VERSION "June 2, 2025"

NS_ :

BS_:

BU_: VEH CH Receiver Receiver ChassisBus VehicleBus PartyBus

BO_ 1029 VIN_info: 8 VEH
 SG_ VIN_infoIndex M : 0|8@1+ (1,0) [0|255] "" Vector__XXX
 SG_ VIN_B405 m17 : 8|56@1+ (1,0) [0|7.20576e+16] "" Vector__XXX
 SG_ VIN_C405 m18 : 8|56@1+ (1,0) [0|7.20576e+16] "" Vector__XXX
 SG_ VIN_A405 m16 : 8|56@1+ (1,0) [0|7.20576e+16] "" Vector__XXX

BO_ 1040 APP_cameraStatus: 1 CH
 SG_ APP_backupCameraFeedGood : 0|1@1+ (1,0) [0|0] "" Vector__XXX
 SG_ APP_backupCameraFrameRate : 1|6@1+ (1,0) [0|0] "" Vector__XXX

BO_ 1064 UI_telemetryControl: 8 CH
 SG_ UI_TCR_classConstElem : 5|1@1+ (1,0) [0|0] "" Vector__XXX
 SG_ UI_TCR_classMovingFourWheel : 8|1@1+ (1,0) [0|0] "" Vector__XXX
 SG_ UI_TCR_classMovingPed : 6|1@1+ (1,0) [0|0] "" Vector__XXX
 SG_ UI_TCR_classMovingTwoWheel : 7|1@1+ (1,0) [0|0] "" Vector__XXX
 SG_ UI_TCR_classUnknown : 9|1@1+ (1,0) [0|0] "" Vector__XXX
 SG_ UI_TCR_downSampleFactor : 10|4@1+ (1,0) [0|0] "" Vector__XXX
 SG_ UI_TCR_enable : 0|1@1+ (1,0) [0|0] "" Vector__XXX
 SG_ UI_TCR_maxDy : 48|5@1+ (0.5,0) [0|0] "m" Vector__XXX
 SG_ UI_TCR_maxObjects : 56|5@1+ (1,0) [0|0] "" Vector__XXX
 SG_ UI_TCR_maxRoadClass : 61|3@1+ (1,0) [0|0] "" Vector__XXX
 SG_ UI_TCR_minRCS : 40|8@1+ (0.25,-14) [0|0] "dB" Vector__XXX
 SG_ UI_TCR_moveStateIndeterm : 4|1@1+ (1,0) [0|0] "" Vector__XXX
 SG_ UI_TCR_moveStateMoving : 3|1@1+ (1,0) [0|0] "" Vector__XXX
 SG_ UI_TCR_moveStateStanding : 1|1@1+ (1,0) [0|0] "" Vector__XXX
 SG_ UI_TCR_moveStateStopped : 2|1@1+ (1,0) [0|0] "" Vector__XXX
 SG_ UI_TCR_vehSpeed : 32|8@1+ (1,0) [0|0] "" Vector__XXX
 SG_ UI_TCR_wExist : 24|5@1+ (1,0) [0|0] "" Vector__XXX

BO_ 1065 APP_warningMatrix2: 8 CH
 SG_ APP_w129_mainCamExtNotCal : 0|1@1+ (1,0) [0|0] "" Vector__XXX
 SG_ APP_w130_narrowCamExtNotCal : 1|1@1+ (1,0) [0|0] "" Vector__XXX
 SG_ APP_w131_mainCamCalSaved : 2|1@1+ (1,0) [0|0] "" Vector__XXX
 SG_ APP_w132_narrowCamCalSaved : 3|1@1+ (1,0) [0|0] "" Vector__XXX
 SG_ APP_w133_mainCamInitFault : 4|1@1+ (1,0) [0|0] "" Vector__XXX
 SG_ APP_w134_narrowCamInitFault : 5|1@1+ (1,0) [0|0] "" Vector__XXX
 SG_ APP_w135_fisheyeCamInitFault : 6|1@1+ (1,0) [0|0] "" Vector__XXX
 SG_ APP_w136_lPillarCamInitFault : 7|1@1+ (1,0) [0|0] "" Vector__XXX
 SG_ APP_w137_rPillarCamInitFault : 8|1@1+ (1,0) [0|0] "" Vector__XXX
 SG_ APP_w138_lRepeatCamInitFault : 9|1@1+ (1,0) [0|0] "" Vector__XXX
 SG_ APP_w139_rRepeatCamInitFault : 10|1@1+ (1,0) [0|0] "" Vector__XXX
 SG_ APP_w140_backupCamInitFault : 11|1@1+ (1,0) [0|0] "" Vector__XXX
 SG_ APP_w141_ECU_Thermal_Issue : 12|1@1+ (1,0) [0|0] "" Vector__XXX
 SG_ APP_w142_fwdCamPitchProblem : 13|1@1+ (1,0) [0|0] "" Vector__XXX
 SG_ APP_w143_IDF_event : 14|1@1+ (1,0) [0|0] "" Vector__XXX
 SG_ APP_w144_fanctrldError : 15|1@1+ (1,0) [0|0] "" Vector__XXX
 SG_ APP_w145_camSelfCalIssue : 16|1@1+ (1,0) [0|0] "" Vector__XXX
 SG_ APP_w146_telemetryProblem : 17|1@1+ (1,0) [0|0] "" Vector__XXX
 SG_ APP_w147_selfieCamInitFault : 18|1@1+ (1,0) [0|0] "" Vector__XXX
 SG_ APP_w148_overlayActive : 19|1@1+ (1,0) [0|0] "" Vector__XXX
 SG_ APP_w149_diskFull : 20|1@1+ (1,0) [0|0] "" Vector__XXX
 SG_ APP_w150_diMiaPartyBus : 21|1@1+ (1,0) [0|0] "" Vector__XXX
 SG_ APP_w151_epasMiaPartyBus : 22|1@1+ (1,0) [0|0] "" Vector__XXX
 SG_ APP_w152_espMiaPartyBus : 23|1@1+ (1,0) [0|0] "" Vector__XXX
 SG_ APP_w153_rcmMiaPartyBus : 24|1@1+ (1,0) [0|0] "" Vector__XXX
 SG_ APP_w154_vcleftMiaPartyBus : 25|1@1+ (1,0) [0|0] "" Vector__XXX
 SG_ APP_w155_vcrightMiaPartyBus : 26|1@1+ (1,0) [0|0] "" Vector__XXX
 SG_ APP_w156_epblMiaVehBus : 27|1@1+ (1,0) [0|0] "" Vector__XXX
 SG_ APP_w157_sccmMiaVehBus : 28|1@1+ (1,0) [0|0] "" Vector__XXX
 SG_ APP_w158_vcfrontMiaVehBus : 29|1@1+ (1,0) [0|0] "" Vector__XXX
 SG_ APP_w159_vcleftMiaVehBus : 30|1@1+ (1,0) [0|0] "" Vector__XXX
 SG_ APP_w160_vcrightMiaVehBus : 31|1@1+ (1,0) [0|0] "" Vector__XXX
 SG_ APP_w161_backupCameraUnavailable : 32|1@1+ (1,0) [0|0] "" Vector__XXX
 SG_ APP_w162_mainCameraTypeError : 33|1@1+ (1,0) [0|0] "" Vector__XXX
 SG_ APP_w163_narrowCameraTypeError : 34|1@1+ (1,0) [0|0] "" Vector__XXX
 SG_ APP_w164_fisheyeCameraTypeError : 35|1@1+ (1,0) [0|0] "" Vector__XXX
 SG_ APP_w165_lPillarCameraTypeError : 36|1@1+ (1,0) [0|0] "" Vector__XXX
 SG_ APP_w166_rPillarCameraTypeError : 37|1@1+ (1,0) [0|0] "" Vector__XXX
 SG_ APP_w167_lRepeatCameraTypeError : 38|1@1+ (1,0) [0|0] "" Vector__XXX
 SG_ APP_w168_rRepeatCameraTypeError : 39|1@1+ (1,0) [0|0] "" Vector__XXX
 SG_ APP_w169_backupCameraTypeError : 40|1@1+ (1,0) [0|0] "" Vector__XXX
 SG_ APP_w170_selfieCameraTypeError : 41|1@1+ (1,0) [0|0] "" Vector__XXX
 SG_ APP_w171_appHighCoolantFlowReq : 42|1@1+ (1,0) [0|0] "" Vector__XXX
 SG_ APP_w172_fisheyeCamExtNotCal : 43|1@1+ (1,0) [0|0] "" Vector__XXX
 SG_ APP_w173_lPillarCamExtNotCal : 44|1@1+ (1,0) [0|0] "" Vector__XXX
 SG_ APP_w174_rPillarCamExtNotCal : 45|1@1+ (1,0) [0|0] "" Vector__XXX
 SG_ APP_w175_lRepeatCamExtNotCal : 46|1@1+ (1,0) [0|0] "" Vector__XXX
 SG_ APP_w176_rRepeatCamExtNotCal : 47|1@1+ (1,0) [0|0] "" Vector__XXX
 SG_ APP_w177_fisheyeCamCalSaved : 48|1@1+ (1,0) [0|0] "" Vector__XXX
 SG_ APP_w178_lPillarCamCalSaved : 49|1@1+ (1,0) [0|0] "" Vector__XXX
 SG_ APP_w179_rPillarCamCalSaved : 50|1@1+ (1,0) [0|0] "" Vector__XXX
 SG_ APP_w180_lRepeatCamCalSaved : 51|1@1+ (1,0) [0|0] "" Vector__XXX
 SG_ APP_w181_rRepeatCamCalSaved : 52|1@1+ (1,0) [0|0] "" Vector__XXX
 SG_ APP_w182_mainCameraStreamExit : 53|1@1+ (1,0) [0|0] "" Vector__XXX
 SG_ APP_w183_narrowCameraStreamExit : 54|1@1+ (1,0) [0|0] "" Vector__XXX
 SG_ APP_w184_fisheyeCameraStreamExit : 55|1@1+ (1,0) [0|0] "" Vector__XXX
 SG_ APP_w185_lPillarCameraStreamExit : 56|1@1+ (1,0) [0|0] "" Vector__XXX
 SG_ APP_w186_rPillarCameraStreamExit : 57|1@1+ (1,0) [0|0] "" Vector__XXX
 SG_ APP_w187_lRepeatCameraStreamExit : 58|1@1+ (1,0) [0|0] "" Vector__XXX
 SG_ APP_w188_rRepeatCameraStreamExit : 59|1@1+ (1,0) [0|0] "" Vector__XXX
 SG_ APP_w189_backupCameraStreamExit : 60|1@1+ (1,0) [0|0] "" Vector__XXX
 SG_ APP_w190_selfieCameraStreamExit : 61|1@1+ (1,0) [0|0] "" Vector__XXX
 SG_ APP_w191_autopilotAborting : 62|1@1+ (1,0) [0|0] "" Vector__XXX
 SG_ APP_w192_emergencySpeakerFail : 63|1@1+ (1,0) [0|0] "" Vector__XXX

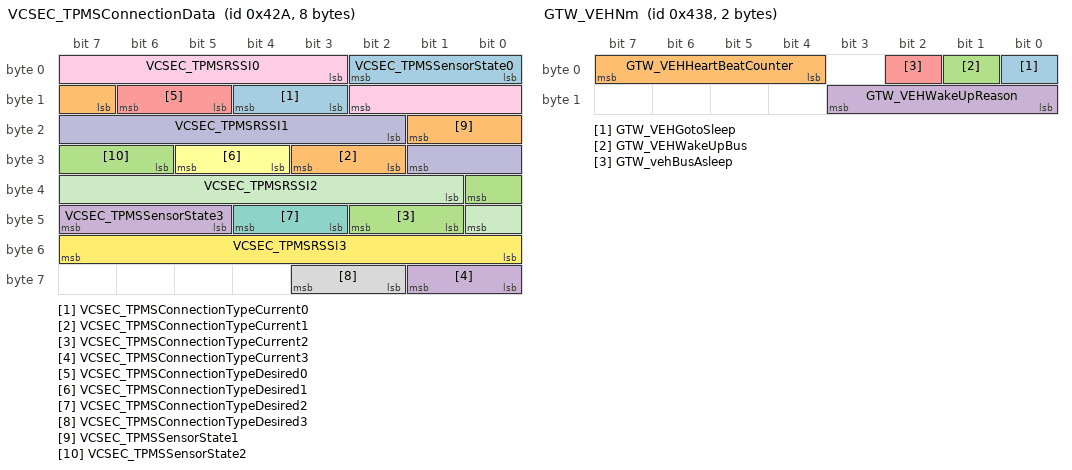
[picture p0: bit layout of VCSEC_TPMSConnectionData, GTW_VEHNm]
BO_ 1066 VCSEC_TPMSConnectionData: 8 VEH
 SG_ VCSEC_TPMSConnectionTypeCurrent0 : 11|2@1+ (1,0) [0|2] "" Vector__XXX
 SG_ VCSEC_TPMSConnectionTypeCurrent1 : 26|2@1+ (1,0) [0|2] "" Vector__XXX
 SG_ VCSEC_TPMSConnectionTypeCurrent2 : 41|2@1+ (1,0) [0|2] "" Vector__XXX
 SG_ VCSEC_TPMSConnectionTypeCurrent3 : 56|2@1+ (1,0) [0|2] "" Vector__XXX
 SG_ VCSEC_TPMSConnectionTypeDesired0 : 13|2@1+ (1,0) [0|2] "" Vector__XXX
 SG_ VCSEC_TPMSConnectionTypeDesired1 : 28|2@1+ (1,0) [0|2] "" Vector__XXX
 SG_ VCSEC_TPMSConnectionTypeDesired2 : 43|2@1+ (1,0) [0|2] "" Vector__XXX
 SG_ VCSEC_TPMSConnectionTypeDesired3 : 58|2@1+ (1,0) [0|2] "" Vector__XXX
 SG_ VCSEC_TPMSRSSI0 : 3|8@1- (1,0) [-127|0] "dBm" Vector__XXX
 SG_ VCSEC_TPMSRSSI1 : 18|8@1- (1,0) [-127|0] "dBm" Vector__XXX
 SG_ VCSEC_TPMSRSSI2 : 33|8@1- (1,0) [-127|0] "dBm" Vector__XXX
 SG_ VCSEC_TPMSRSSI3 : 48|8@1- (1,0) [-127|0] "dBm" Vector__XXX
 SG_ VCSEC_TPMSSensorState0 : 0|3@1+ (1,0) [0|4] "" Vector__XXX
 SG_ VCSEC_TPMSSensorState1 : 15|3@1+ (1,0) [0|4] "" Vector__XXX
 SG_ VCSEC_TPMSSensorState2 : 30|3@1+ (1,0) [0|4] "" Vector__XXX
 SG_ VCSEC_TPMSSensorState3 : 45|3@1+ (1,0) [0|4] "" Vector__XXX

BO_ 1080 GTW_VEHNm: 2 VEH
 SG_ GTW_VEHGotoSleep : 0|1@1+ (1,0) [0|0] "" Vector__XXX
 SG_ GTW_VEHHeartBeatCounter : 4|4@1+ (1,0) [0|0] "" Vector__XXX
 SG_ GTW_VEHWakeUpBus : 1|1@1+ (1,0) [0|0] "" Vector__XXX
 SG_ GTW_VEHWakeUpReason : 8|4@1+ (1,0) [0|0] "" Vector__XXX
 SG_ GTW_vehBusAsleep : 2|1@1+ (1,0) [0|0] "" Vector__XXX

BO_ 1081 APP_warningMatrix3: 8 CH
 SG_ APP_w193_camWindshieldUnclean : 0|1@1+ (1,0) [0|0] "" Vector__XXX
 SG_ APP_w194_accDriverResumeRqrd : 1|1@1+ (1,0) [0|0] "" Vector__XXX
 SG_ APP_w195_scwUnavailable : 2|1@1+ (1,0) [0|0] "" Vector__XXX
 SG_ APP_w196_stopSignWarning : 3|1@1+ (1,0) [0|0] "" Vector__XXX
 SG_ APP_w197_redLightWarning : 4|1@1+ (1,0) [0|0] "" Vector__XXX
 SG_ APP_w198_tsrUnavailable : 5|1@1+ (1,0) [0|0] "" Vector__XXX
 SG_ APP_w199_apcAbort : 6|1@1+ (1,0) [0|0] "" Vector__XXX
 SG_ APP_w200_lcSlowdown : 7|1@1+ (1,0) [0|0] "" Vector__XXX
 SG_ APP_w201_lcAborting : 8|1@1+ (1,0) [0|0] "" Vector__XXX
 SG_ APP_w202_scwNoisyEnvironment : 9|1@1+ (1,0) [0|0] "" Vector__XXX
 SG_ APP_w203_apcActivation : 10|1@1+ (1,0) [0|0] "" Vector__XXX
 SG_ APP_w204_apcFinalFront : 11|1@1+ (1,0) [0|0] "" Vector__XXX
 SG_ APP_w205_apcFinalRear : 12|1@1+ (1,0) [0|0] "" Vector__XXX
 SG_ APP_w206_autosteerNotEnabled : 13|1@1+ (1,0) [0|0] "" Vector__XXX
 SG_ APP_w207_autosteerUnavailable : 14|1@1+ (1,0) [0|0] "" Vector__XXX
 SG_ APP_w208_rackDetected : 15|1@1+ (1,0) [0|0] "" Vector__XXX
 SG_ APP_w209_autoSummonRequest : 16|1@1+ (1,0) [0|0] "" Vector__XXX
 SG_ APP_w210_camObstrcted : 17|1@1+ (1,0) [0|0] "" Vector__XXX
 SG_ APP_w211_accNoSeatBelt : 18|1@1+ (1,0) [0|0] "" Vector__XXX
 SG_ APP_w212_lcUnavailableStrikeOut : 19|1@1+ (1,0) [0|0] "" Vector__XXX
 SG_ APP_w213_autosteerStruckOut : 20|1@1+ (1,0) [0|0] "" Vector__XXX
 SG_ APP_w214_driverNotIntracting : 21|1@1+ (1,0) [0|0] "" Vector__XXX
 SG_ APP_w215_contDriverNotIntracting : 22|1@1+ (1,0) [0|0] "" Vector__XXX
 SG_ APP_w216_driverOverriding : 23|1@1+ (1,0) [0|0] "" Vector__XXX
 SG_ APP_w217_lcUnavailableSpeeding : 24|1@1+ (1,0) [0|0] "" Vector__XXX
 SG_ APP_w218_lcSpeedExceededLimit : 25|1@1+ (1,0) [0|0] "" Vector__XXX
 SG_ APP_w219_lcTempUnavailableSpeed : 26|1@1+ (1,0) [0|0] "" Vector__XXX
 SG_ APP_w220_lcTempUnavailableRoad : 27|1@1+ (1,0) [0|0] "" Vector__XXX
 SG_ APP_w221_accRadarBlind : 28|1@1+ (1,0) [0|0] "" Vector__XXX
 SG_ APP_w222_accCameraBlind : 29|1@1+ (1,0) [0|0] "" Vector__XXX
 SG_ APP_w223_accObjectInPath : 30|1@1+ (1,0) [0|0] "" Vector__XXX
 SG_ APP_w224_accCameraCalibration : 31|1@1+ (1,0) [0|0] "" Vector__XXX
 SG_ APP_w225_lcDegradedVisSpeedLmt : 32|1@1+ (1,0) [0|0] "" Vector__XXX
 SG_ APP_w226_lcCamCalNeededSpeedLmt : 33|1@1+ (1,0) [0|0] "" Vector__XXX
 SG_ APP_w227_virtualWallBlocked : 34|1@1+ (1,0) [0|0] "" Vector__XXX
 SG_ APP_w228_DEPRECATED : 35|1@1+ (1,0) [0|0] "" Vector__XXX
 SG_ APP_w229_alcUltrasoundDamaged : 36|1@1+ (1,0) [0|0] "" Vector__XXX
 SG_ APP_w230_alcUltrasoundBlocked : 37|1@1+ (1,0) [0|0] "" Vector__XXX

BO_ 1082 DAS_warningMatrix3: 8 VEH
 SG_ DAS_w193_camWindshieldUnclean : 0|1@1+ (1,0) [0|0] "" Vector__XXX
 SG_ DAS_w194_accDriverResumeRqrd : 1|1@1+ (1,0) [0|0] "" Vector__XXX
 SG_ DAS_w195_scwUnavailable : 2|1@1+ (1,0) [0|0] "" Vector__XXX
 SG_ DAS_w196_stopSignWarning : 3|1@1+ (1,0) [0|0] "" Vector__XXX
 SG_ DAS_w197_redLightWarning : 4|1@1+ (1,0) [0|0] "" Vector__XXX
 SG_ DAS_w198_tsrUnavailable : 5|1@1+ (1,0) [0|0] "" Vector__XXX
 SG_ DAS_w199_apcAbort : 6|1@1+ (1,0) [0|0] "" Vector__XXX
 SG_ DAS_w200_lcSlowdown : 7|1@1+ (1,0) [0|0] "" Vector__XXX
 SG_ DAS_w201_lcAborting : 8|1@1+ (1,0) [0|0] "" Vector__XXX
 SG_ DAS_w202_scwNoisyEnvironment : 9|1@1+ (1,0) [0|0] "" Vector__XXX
 SG_ DAS_w203_apcActivation : 10|1@1+ (1,0) [0|0] "" Vector__XXX
 SG_ DAS_w204_apcFinalFront : 11|1@1+ (1,0) [0|0] "" Vector__XXX
 SG_ DAS_w205_apcFinalRear : 12|1@1+ (1,0) [0|0] "" Vector__XXX
 SG_ DAS_w206_autosteerNotEnabled : 13|1@1+ (1,0) [0|0] "" Vector__XXX
 SG_ DAS_w207_autosteerUnavailable : 14|1@1+ (1,0) [0|0] "" Vector__XXX
 SG_ DAS_w208_rackDetected : 15|1@1+ (1,0) [0|0] "" Vector__XXX
 SG_ DAS_w209_autoSummonRequest : 16|1@1+ (1,0) [0|0] "" Vector__XXX
 SG_ DAS_w210_camObstrcted : 17|1@1+ (1,0) [0|0] "" Vector__XXX
 SG_ DAS_w211_accNoSeatBelt : 18|1@1+ (1,0) [0|0] "" Vector__XXX
 SG_ DAS_w212_lcUnavailableStrikeOut : 19|1@1+ (1,0) [0|0] "" Vector__XXX
 SG_ DAS_w213_autosteerStruckOut : 20|1@1+ (1,0) [0|0] "" Vector__XXX
 SG_ DAS_w214_driverNotIntracting : 21|1@1+ (1,0) [0|0] "" Vector__XXX
 SG_ DAS_w215_contDriverNotIntracting : 22|1@1+ (1,0) [0|0] "" Vector__XXX
 SG_ DAS_w216_driverOverriding : 23|1@1+ (1,0) [0|0] "" Vector__XXX
 SG_ DAS_w217_lcUnavailableSpeeding : 24|1@1+ (1,0) [0|0] "" Vector__XXX
 SG_ DAS_w218_lcSpeedExceededLimit : 25|1@1+ (1,0) [0|0] "" Vector__XXX
 SG_ DAS_w219_lcTempUnavailableSpeed : 26|1@1+ (1,0) [0|0] "" Vector__XXX
 SG_ DAS_w220_lcTempUnavailableRoad : 27|1@1+ (1,0) [0|0] "" Vector__XXX
 SG_ DAS_w221_accRadarBlind : 28|1@1+ (1,0) [0|0] "" Vector__XXX
 SG_ DAS_w222_accCameraBlind : 29|1@1+ (1,0) [0|0] "" Vector__XXX
 SG_ DAS_w223_accObjectInPath : 30|1@1+ (1,0) [0|0] "" Vector__XXX
 SG_ DAS_w224_accCameraCalibration : 31|1@1+ (1,0) [0|0] "" Vector__XXX
 SG_ DAS_w225_lcDegradedVisSpeedLmt : 32|1@1+ (1,0) [0|0] "" Vector__XXX
 SG_ DAS_w226_lcCamCalNeededSpeedLmt : 33|1@1+ (1,0) [0|0] "" Vector__XXX
 SG_ DAS_w227_virtualWallBlocked : 34|1@1+ (1,0) [0|0] "" Vector__XXX
 SG_ DAS_w228_DEPRECATED : 35|1@1+ (1,0) [0|0] "" Vector__XXX
 SG_ DAS_w229_alcUltrasoundDamaged : 36|1@1+ (1,0) [0|0] "" Vector__XXX
 SG_ DAS_w230_alcUltrasoundBlocked : 37|1@1+ (1,0) [0|0] "" Vector__XXX

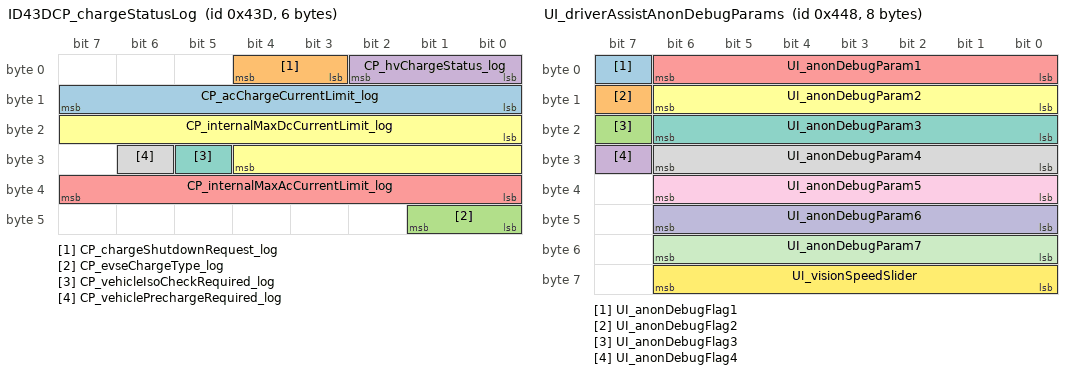
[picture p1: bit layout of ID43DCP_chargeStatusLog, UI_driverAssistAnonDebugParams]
BO_ 1085 ID43DCP_chargeStatusLog: 6 VehicleBus
 SG_ CP_acChargeCurrentLimit_log : 8|8@1+ (0.5,0) [0|127.5] "A"   X
 SG_ CP_chargeShutdownRequest_log : 3|2@1+ (1,0) [0|2] ""   X
 SG_ CP_evseChargeType_log : 40|2@1+ (1,0) [0|2] ""   X
 SG_ CP_hvChargeStatus_log : 0|3@1+ (1,0) [0|6] ""   X
 SG_ CP_internalMaxAcCurrentLimit_log : 32|8@1+ (0.5,0) [0|127.5] "A"   X
 SG_ CP_internalMaxDcCurrentLimit_log : 16|13@1+ (0.146502,0) [0|1200] "A"   X
 SG_ CP_vehicleIsoCheckRequired_log : 29|1@1+ (1,0) [0|1] ""   X
 SG_ CP_vehiclePrechargeRequired_log : 30|1@1+ (1,0) [0|1] ""   X

BO_ 1096 UI_driverAssistAnonDebugParams: 8 VEH
 SG_ UI_anonDebugFlag1 : 7|1@1+ (1,0) [0|0] "" Vector__XXX
 SG_ UI_anonDebugFlag2 : 15|1@1+ (1,0) [0|0] "" Vector__XXX
 SG_ UI_anonDebugFlag3 : 23|1@1+ (1,0) [0|0] "" Vector__XXX
 SG_ UI_anonDebugFlag4 : 31|1@1+ (1,0) [0|0] "" Vector__XXX
 SG_ UI_anonDebugParam1 : 0|7@1+ (1,0) [0|0] "" Vector__XXX
 SG_ UI_anonDebugParam2 : 8|7@1+ (1,0) [0|0] "" Vector__XXX
 SG_ UI_anonDebugParam3 : 16|7@1+ (1,0) [0|0] "" Vector__XXX
 SG_ UI_anonDebugParam4 : 24|7@1+ (1,0) [0|0] "" Vector__XXX
 SG_ UI_anonDebugParam5 : 32|7@1+ (1,0) [0|0] "" Vector__XXX
 SG_ UI_anonDebugParam6 : 40|7@1+ (1,0) [0|0] "" Vector__XXX
 SG_ UI_anonDebugParam7 : 48|7@1+ (1,0) [0|0] "" Vector__XXX
 SG_ UI_visionSpeedSlider : 56|7@1+ (1,0) [0|0] "" Vector__XXX

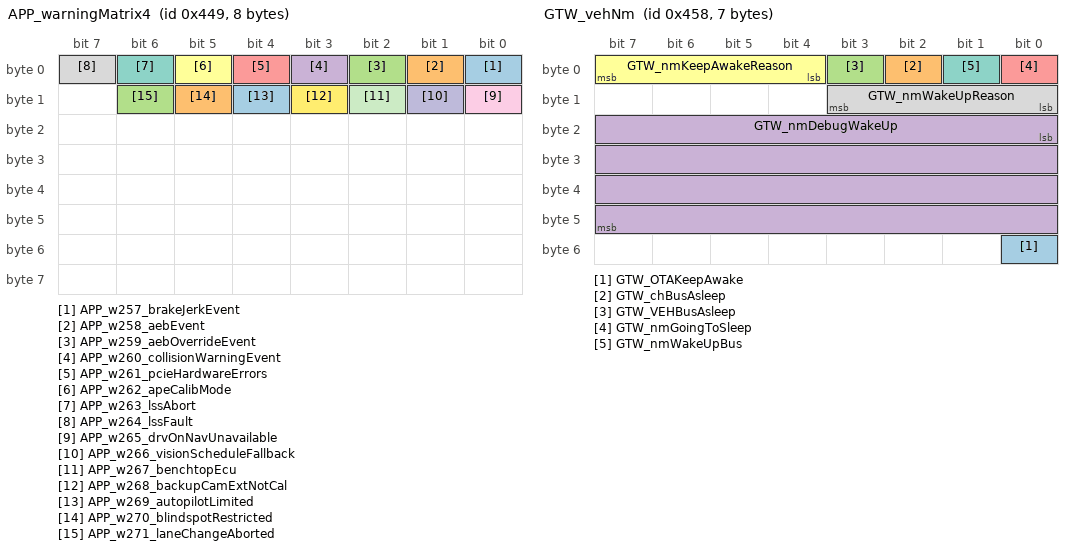
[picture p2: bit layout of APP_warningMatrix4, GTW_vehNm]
BO_ 1097 APP_warningMatrix4: 8 CH
 SG_ APP_w257_brakeJerkEvent : 0|1@1+ (1,0) [0|0] "" Vector__XXX
 SG_ APP_w258_aebEvent : 1|1@1+ (1,0) [0|0] "" Vector__XXX
 SG_ APP_w259_aebOverrideEvent : 2|1@1+ (1,0) [0|0] "" Vector__XXX
 SG_ APP_w260_collisionWarningEvent : 3|1@1+ (1,0) [0|0] "" Vector__XXX
 SG_ APP_w261_pcieHardwareErrors : 4|1@1+ (1,0) [0|0] "" Vector__XXX
 SG_ APP_w262_apeCalibMode : 5|1@1+ (1,0) [0|0] "" Vector__XXX
 SG_ APP_w263_lssAbort : 6|1@1+ (1,0) [0|0] "" Vector__XXX
 SG_ APP_w264_lssFault : 7|1@1+ (1,0) [0|0] "" Vector__XXX
 SG_ APP_w265_drvOnNavUnavailable : 8|1@1+ (1,0) [0|0] "" Vector__XXX
 SG_ APP_w266_visionScheduleFallback : 9|1@1+ (1,0) [0|0] "" Vector__XXX
 SG_ APP_w267_benchtopEcu : 10|1@1+ (1,0) [0|0] "" Vector__XXX
 SG_ APP_w268_backupCamExtNotCal : 11|1@1+ (1,0) [0|0] "" Vector__XXX
 SG_ APP_w269_autopilotLimited : 12|1@1+ (1,0) [0|0] "" Vector__XXX
 SG_ APP_w270_blindspotRestricted : 13|1@1+ (1,0) [0|0] "" Vector__XXX
 SG_ APP_w271_laneChangeAborted : 14|1@1+ (1,0) [0|0] "" Vector__XXX

BO_ 1112 GTW_vehNm: 7 VEH
 SG_ GTW_OTAKeepAwake : 48|1@1+ (1,0) [0|0] "" Vector__XXX
 SG_ GTW_chBusAsleep : 2|1@1+ (1,0) [0|0] "" Vector__XXX
 SG_ GTW_VEHBusAsleep : 3|1@1+ (1,0) [0|0] "" Vector__XXX
 SG_ GTW_nmDebugWakeUp : 16|32@1+ (1,0) [0|0] "" Vector__XXX
 SG_ GTW_nmGoingToSleep : 0|1@1+ (1,0) [0|0] "" Vector__XXX
 SG_ GTW_nmKeepAwakeReason : 4|4@1+ (1,0) [0|0] "" Vector__XXX
 SG_ GTW_nmWakeUpBus : 1|1@1+ (1,0) [0|0] "" Vector__XXX
 SG_ GTW_nmWakeUpReason : 8|4@1+ (1,0) [0|0] "" Vector__XXX

BO_ 1113 APS_warningMatrix2: 8 CH
 SG_ APS_w129_ECU_Power_Issue : 0|1@1+ (1,0) [0|0] "" Vector__XXX
 SG_ APS_w130_ECU_Thermal_Issue : 1|1@1+ (1,0) [0|0] "" Vector__XXX
 SG_ APS_w131_trap_exception : 2|1@1+ (1,0) [0|0] "" Vector__XXX
 SG_ APS_w132_appVersionMismatch : 3|1@1+ (1,0) [0|0] "" Vector__XXX
 SG_ APS_w133_VEHSwitchError : 4|1@1+ (1,0) [0|0] "" Vector__XXX
 SG_ APS_w134_appMia : 5|1@1+ (1,0) [0|0] "" Vector__XXX
 SG_ APS_w135_appCritical : 6|1@1+ (1,0) [0|0] "" Vector__XXX
 SG_ APS_w136_gpsDisabled : 7|1@1+ (1,0) [0|0] "" Vector__XXX
 SG_ APS_w137_gpsFaultReset : 8|1@1+ (1,0) [0|0] "" Vector__XXX
 SG_ APS_w138_gpsComIssue : 9|1@1+ (1,0) [0|0] "" Vector__XXX
 SG_ APS_w139_udpBufferOverflow : 10|1@1+ (1,0) [0|0] "" Vector__XXX
 SG_ APS_w140_vcfrontMiaVEH : 11|1@1+ (1,0) [0|0] "" Vector__XXX
 SG_ APS_w141_rcmMiaPartyBus : 12|1@1+ (1,0) [0|0] "" Vector__XXX
 SG_ APS_w142_diMiaPartyBus : 13|1@1+ (1,0) [0|0] "" Vector__XXX
 SG_ APS_w143_espMiaPartyBus : 14|1@1+ (1,0) [0|0] "" Vector__XXX
 SG_ APS_w144_vcleftMiaPartyBus : 15|1@1+ (1,0) [0|0] "" Vector__XXX
 SG_ APS_w145_vcrightMiaPartyBus : 16|1@1+ (1,0) [0|0] "" Vector__XXX
 SG_ APS_w146_epas3pMiaPartyBus : 17|1@1+ (1,0) [0|0] "" Vector__XXX
 SG_ APS_w147_vcleftMiaVehBus : 18|1@1+ (1,0) [0|0] "" Vector__XXX
 SG_ APS_w148_vcrightMiaVehBus : 19|1@1+ (1,0) [0|0] "" Vector__XXX
 SG_ APS_w149_epblMiaVehBus : 20|1@1+ (1,0) [0|0] "" Vector__XXX
 SG_ APS_w150_sccmMiaVehBus : 21|1@1+ (1,0) [0|0] "" Vector__XXX
 SG_ APS_w151_apRecovered : 22|1@1+ (1,0) [0|0] "" Vector__XXX
 SG_ APS_w152_gpsFusionStatus : 23|1@1+ (1,0) [0|0] "" Vector__XXX
 SG_ APS_w153_eacInhibit : 24|1@1+ (1,0) [0|0] "" Vector__XXX
 SG_ APS_w155_VEHLwipError : 26|1@1+ (1,0) [0|0] "" Vector__XXX
 SG_ APS_w156_lwipAssert : 27|1@1+ (1,0) [0|0] "" Vector__XXX
 SG_ APS_w157_autopilotReboot : 28|1@1+ (1,0) [0|0] "" Vector__XXX
 SG_ APS_w158_apbMia : 29|1@1+ (1,0) [0|0] "" Vector__XXX
 SG_ APS_w159_apbCritical : 30|1@1+ (1,0) [0|0] "" Vector__XXX
 SG_ APS_w160_apbVersionMismatch : 31|1@1+ (1,0) [0|0] "" Vector__XXX
 SG_ APS_w161_gpsAntennaDisconnected : 32|1@1+ (1,0) [0|0] "" Vector__XXX

BO_ 1132 CC_alertMatrix1: 8 VEH
 SG_ CC_a001_gndMonIntrptLineSide : 0|1@1+ (1,0) [0|0] "" Vector__XXX
 SG_ CC_a002_gndMonIntrptLoadSide : 1|1@1+ (1,0) [0|0] "" Vector__XXX
 SG_ CC_a003_CCIDTripped : 2|1@1+ (1,0) [0|0] "" Vector__XXX
 SG_ CC_a004_CCIDSelfTestFault : 3|1@1+ (1,0) [0|0] "" Vector__XXX
 SG_ CC_a005_groundedNeutral : 4|1@1+ (1,0) [0|0] "" Vector__XXX
 SG_ CC_a006_inputOverCurrent : 5|1@1+ (1,0) [0|0] "" Vector__XXX
 SG_ CC_a007_inputOverVoltage : 6|1@1+ (1,0) [0|0] "" Vector__XXX
 SG_ CC_a008_inputUnderVoltage : 7|1@1+ (1,0) [0|0] "" Vector__XXX
 SG_ CC_a009_inputMiswired : 8|1@1+ (1,0) [0|0] "" Vector__XXX
 SG_ CC_a010_contactorWelded : 9|1@1+ (1,0) [0|0] "" Vector__XXX
 SG_ CC_a011_ambientOT : 10|1@1+ (1,0) [0|0] "" Vector__XXX
 SG_ CC_a012_wallPlugOT : 11|1@1+ (1,0) [0|0] "" Vector__XXX
 SG_ CC_a013_vehConnOT : 12|1@1+ (1,0) [0|0] "" Vector__XXX
 SG_ CC_a014_mcuSelfTestFault : 13|1@1+ (1,0) [0|0] "" Vector__XXX
 SG_ CC_a015_PilotAFault : 14|1@1+ (1,0) [0|0] "" Vector__XXX
 SG_ CC_a016_PilotBFault : 15|1@1+ (1,0) [0|0] "" Vector__XXX
 SG_ CC_a017_PilotCFault : 16|1@1+ (1,0) [0|0] "" Vector__XXX
 SG_ CC_a018_PilotDFault : 17|1@1+ (1,0) [0|0] "" Vector__XXX
 SG_ CC_a019_proxDisconnected : 18|1@1+ (1,0) [0|0] "" Vector__XXX
 SG_ CC_a020_3vRailIncorrect : 19|1@1+ (1,0) [0|0] "" Vector__XXX
 SG_ CC_a021_CB_noMaster : 20|1@1+ (1,0) [0|0] "" Vector__XXX
 SG_ CC_a022_CB_tooManyMasters : 21|1@1+ (1,0) [0|0] "" Vector__XXX
 SG_ CC_a023_CB_tooManySlaves : 22|1@1+ (1,0) [0|0] "" Vector__XXX
 SG_ CC_a024_CB_masterISetTooLow : 23|1@1+ (1,0) [0|0] "" Vector__XXX
 SG_ CC_a025_evseTemp : 24|1@1+ (1,0) [0|0] "" Vector__XXX
 SG_ CC_a026_wallPlugTemp : 25|1@1+ (1,0) [0|0] "" Vector__XXX
 SG_ CC_a027_vehicleHandleTemp : 26|1@1+ (1,0) [0|0] "" Vector__XXX
 SG_ CC_a028_CB_rotarySelect : 27|1@1+ (1,0) [0|0] "" Vector__XXX
 SG_ CC_a029_PilotFFault : 28|1@1+ (1,0) [0|0] "" Vector__XXX
 SG_ CC_a030_masterSlaveMismatch : 29|1@1+ (1,0) [0|0] "" Vector__XXX

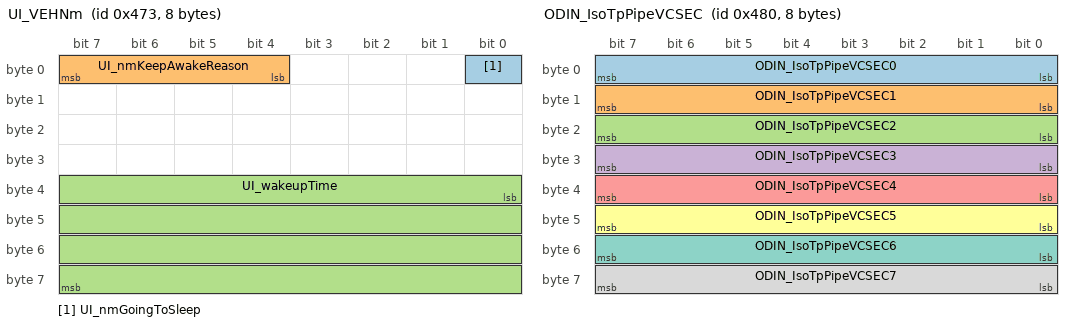
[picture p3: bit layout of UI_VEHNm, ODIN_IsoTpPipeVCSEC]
BO_ 1139 UI_VEHNm: 8 VEH
 SG_ UI_nmGoingToSleep : 0|1@1+ (1,0) [0|0] "" Vector__XXX
 SG_ UI_nmKeepAwakeReason : 4|4@1+ (1,0) [0|0] "" Vector__XXX
 SG_ UI_wakeupTime : 32|32@1+ (1,0) [0|0] "" Vector__XXX

BO_ 1152 ODIN_IsoTpPipeVCSEC: 8 VEH
 SG_ ODIN_IsoTpPipeVCSEC0 : 0|8@1+ (1,0) [0|0] "" Vector__XXX
 SG_ ODIN_IsoTpPipeVCSEC1 : 8|8@1+ (1,0) [0|0] "" Vector__XXX
 SG_ ODIN_IsoTpPipeVCSEC2 : 16|8@1+ (1,0) [0|0] "" Vector__XXX
 SG_ ODIN_IsoTpPipeVCSEC3 : 24|8@1+ (1,0) [0|0] "" Vector__XXX
 SG_ ODIN_IsoTpPipeVCSEC4 : 32|8@1+ (1,0) [0|0] "" Vector__XXX
 SG_ ODIN_IsoTpPipeVCSEC5 : 40|8@1+ (1,0) [0|0] "" Vector__XXX
 SG_ ODIN_IsoTpPipeVCSEC6 : 48|8@1+ (1,0) [0|0] "" Vector__XXX
 SG_ ODIN_IsoTpPipeVCSEC7 : 56|8@1+ (1,0) [0|0] "" Vector__XXX

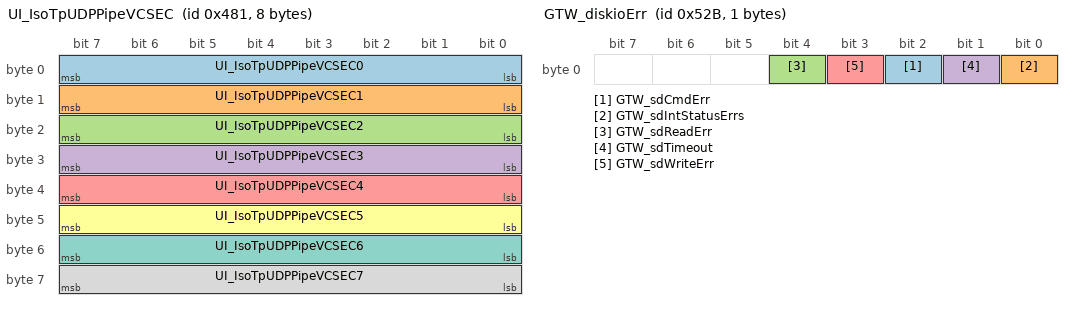
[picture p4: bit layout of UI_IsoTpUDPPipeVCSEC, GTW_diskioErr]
BO_ 1153 UI_IsoTpUDPPipeVCSEC: 8 VEH
 SG_ UI_IsoTpUDPPipeVCSEC0 : 0|8@1+ (1,0) [0|0] "" Vector__XXX
 SG_ UI_IsoTpUDPPipeVCSEC1 : 8|8@1+ (1,0) [0|0] "" Vector__XXX
 SG_ UI_IsoTpUDPPipeVCSEC2 : 16|8@1+ (1,0) [0|0] "" Vector__XXX
 SG_ UI_IsoTpUDPPipeVCSEC3 : 24|8@1+ (1,0) [0|0] "" Vector__XXX
 SG_ UI_IsoTpUDPPipeVCSEC4 : 32|8@1+ (1,0) [0|0] "" Vector__XXX
 SG_ UI_IsoTpUDPPipeVCSEC5 : 40|8@1+ (1,0) [0|0] "" Vector__XXX
 SG_ UI_IsoTpUDPPipeVCSEC6 : 48|8@1+ (1,0) [0|0] "" Vector__XXX
 SG_ UI_IsoTpUDPPipeVCSEC7 : 56|8@1+ (1,0) [0|0] "" Vector__XXX

BO_ 1250 VCLEFT_seatStatus: 8 VEH
 SG_ VCLEFT_seatStatusIndex M : 0|3@1+ (1,0) [0|0] "" Vector__XXX
 SG_ VCLEFT_frontSeatTrackPos m0 : 8|16@1- (1,0) [0|0] "" Vector__XXX
 SG_ VCLEFT_frontSeatTrackCurrent m0 : 24|12@1- (0.01,0) [0|0] "A" Vector__XXX
 SG_ VCLEFT_frontSeatTrackDuty m0 : 36|12@1- (0.1,0) [0|0] "%" Vector__XXX
 SG_ VCLEFT_frontSeatTrackState m0 : 48|3@1+ (1,0) [0|0] "" Vector__XXX
 SG_ VCLEFT_frontSeatTrackCalibrated m0 : 51|1@1+ (1,0) [0|0] "" Vector__XXX
 SG_ VCLEFT_frontSeatTrackLog m0 : 52|1@1+ (1,0) [0|0] "" Vector__XXX
 SG_ VCLEFT_frontSeatBackPos m1 : 8|16@1- (1,0) [0|0] "" Vector__XXX
 SG_ VCLEFT_frontSeatBackCurrent m1 : 24|12@1- (0.01,0) [0|0] "A" Vector__XXX
 SG_ VCLEFT_frontSeatBackDuty m1 : 36|12@1- (0.1,0) [0|0] "%" Vector__XXX
 SG_ VCLEFT_frontSeatBackState m1 : 48|3@1+ (1,0) [0|0] "" Vector__XXX
 SG_ VCLEFT_frontSeatBackCalibrated m1 : 51|1@1+ (1,0) [0|0] "" Vector__XXX
 SG_ VCLEFT_frontSeatBackLog m1 : 52|1@1+ (1,0) [0|0] "" Vector__XXX
 SG_ VCLEFT_frontSeatLiftPos m2 : 8|16@1- (1,0) [0|0] "" Vector__XXX
 SG_ VCLEFT_frontSeatLiftCurrent m2 : 24|12@1- (0.01,0) [0|0] "A" Vector__XXX
 SG_ VCLEFT_frontSeatLiftDuty m2 : 36|12@1- (0.1,0) [0|0] "%" Vector__XXX
 SG_ VCLEFT_frontSeatLiftState m2 : 48|3@1+ (1,0) [0|0] "" Vector__XXX
 SG_ VCLEFT_frontSeatLiftCalibrated m2 : 51|1@1+ (1,0) [0|0] "" Vector__XXX
 SG_ VCLEFT_frontSeatLiftLog m2 : 52|1@1+ (1,0) [0|0] "" Vector__XXX
 SG_ VCLEFT_frontSeatTiltPos m3 : 8|16@1- (1,0) [0|0] "" Vector__XXX
 SG_ VCLEFT_frontSeatTiltCurrent m3 : 24|12@1- (0.01,0) [0|0] "A" Vector__XXX
 SG_ VCLEFT_frontSeatTiltDuty m3 : 36|12@1- (0.1,0) [0|0] "%" Vector__XXX
 SG_ VCLEFT_frontSeatTiltState m3 : 48|3@1+ (1,0) [0|0] "" Vector__XXX
 SG_ VCLEFT_frontSeatTiltCalibrated m3 : 51|1@1+ (1,0) [0|0] "" Vector__XXX
 SG_ VCLEFT_frontSeatTiltLog m3 : 52|1@1+ (1,0) [0|0] "" Vector__XXX
 SG_ VCLEFT_lumbarAState m4 : 3|3@1+ (1,0) [0|0] "" Vector__XXX
 SG_ VCLEFT_lumbarBState m4 : 8|3@1+ (1,0) [0|0] "" Vector__XXX
 SG_ VCLEFT_lumbarAPressureHpa m4 : 16|16@1+ (1,0) [0|0] "" Vector__XXX
 SG_ VCLEFT_lumbarBPressureHpa m4 : 32|16@1+ (1,0) [0|0] "" Vector__XXX
 SG_ VCLEFT_lumbarActiveTooLongErr m4 : 48|1@1+ (1,0) [0|0] "" Vector__XXX
 SG_ VCLEFT_lumbarMaxPErr m4 : 49|1@1+ (1,0) [0|0] "" Vector__XXX
 SG_ VCLEFT_lumbarOvercurrentErr m4 : 50|1@1+ (1,0) [0|0] "" Vector__XXX
 SG_ VCLEFT_lumbarMaxOperatingPErr m4 : 51|1@1+ (1,0) [0|0] "" Vector__XXX
 SG_ VCLEFT_lumbarMinPErr m4 : 52|1@1+ (1,0) [0|0] "" Vector__XXX
 SG_ VCLEFT_lumbarGeneralErr m4 : 53|1@1+ (1,0) [0|0] "" Vector__XXX
 SG_ VCLEFT_lumbarDevMaxPumpPressA m4 : 54|1@1+ (1,0) [0|0] "" Vector__XXX
 SG_ VCLEFT_lumbarDevMaxPumpPressB m4 : 55|1@1+ (1,0) [0|0] "" Vector__XXX
 SG_ VCLEFT_frontSeatTrackPosReal m5 : 3|12@1- (1,0) [0|0] "mm" Vector__XXX
 SG_ VCLEFT_frontSeatBackPosReal m5 : 16|12@1- (0.1,0) [0|0] "deg" Vector__XXX
 SG_ VCLEFT_frontSeatLiftPosReal m5 : 28|12@1- (1,0) [0|0] "mm" Vector__XXX
 SG_ VCLEFT_frontSeatTiltPosReal m5 : 40|12@1- (0.1,0) [0|0] "deg" Vector__XXX

BO_ 1251 VCRIGHT_seatStatus: 8 VEH
 SG_ VCRIGHT_seatStatusIndex M : 0|3@1+ (1,0) [0|0] "" Vector__XXX
 SG_ VCRIGHT_frontSeatTrackPos m0 : 8|16@1- (1,0) [0|0] "" Vector__XXX
 SG_ VCRIGHT_frontSeatTrackCurrent m0 : 24|12@1- (0.01,0) [0|0] "A" Vector__XXX
 SG_ VCRIGHT_frontSeatTrackDuty m0 : 36|12@1- (0.1,0) [0|0] "%" Vector__XXX
 SG_ VCRIGHT_frontSeatTrackState m0 : 48|3@1+ (1,0) [0|0] "" Vector__XXX
 SG_ VCRIGHT_frontSeatTrackCalibrated m0 : 51|1@1+ (1,0) [0|0] "" Vector__XXX
 SG_ VCRIGHT_frontSeatTrackLog m0 : 52|1@1+ (1,0) [0|0] "" Vector__XXX
 SG_ VCRIGHT_frontSeatBackPos m1 : 8|16@1- (1,0) [0|0] "" Vector__XXX
 SG_ VCRIGHT_frontSeatBackCurrent m1 : 24|12@1- (0.01,0) [0|0] "A" Vector__XXX
 SG_ VCRIGHT_frontSeatBackDuty m1 : 36|12@1- (0.1,0) [0|0] "%" Vector__XXX
 SG_ VCRIGHT_frontSeatBackState m1 : 48|3@1+ (1,0) [0|0] "" Vector__XXX
 SG_ VCRIGHT_frontSeatBackCalibrated m1 : 51|1@1+ (1,0) [0|0] "" Vector__XXX
 SG_ VCRIGHT_frontSeatBackLog m1 : 52|1@1+ (1,0) [0|0] "" Vector__XXX
 SG_ VCRIGHT_frontSeatLiftPos m2 : 8|16@1- (1,0) [0|0] "" Vector__XXX
 SG_ VCRIGHT_frontSeatLiftCurrent m2 : 24|12@1- (0.01,0) [0|0] "A" Vector__XXX
 SG_ VCRIGHT_frontSeatLiftDuty m2 : 36|12@1- (0.1,0) [0|0] "%" Vector__XXX
 SG_ VCRIGHT_frontSeatLiftState m2 : 48|3@1+ (1,0) [0|0] "" Vector__XXX
 SG_ VCRIGHT_frontSeatLiftCalibrated m2 : 51|1@1+ (1,0) [0|0] "" Vector__XXX
 SG_ VCRIGHT_frontSeatLiftLog m2 : 52|1@1+ (1,0) [0|0] "" Vector__XXX
 SG_ VCRIGHT_frontSeatTiltPos m3 : 8|16@1- (1,0) [0|0] "" Vector__XXX
 SG_ VCRIGHT_frontSeatTiltCurrent m3 : 24|12@1- (0.01,0) [0|0] "A" Vector__XXX
 SG_ VCRIGHT_frontSeatTiltDuty m3 : 36|12@1- (0.1,0) [0|0] "%" Vector__XXX
 SG_ VCRIGHT_frontSeatTiltState m3 : 48|3@1+ (1,0) [0|0] "" Vector__XXX
 SG_ VCRIGHT_frontSeatTiltCalibrated m3 : 51|1@1+ (1,0) [0|0] "" Vector__XXX
 SG_ VCRIGHT_frontSeatTiltLog m3 : 52|1@1+ (1,0) [0|0] "" Vector__XXX
 SG_ VCRIGHT_lumbarAState m4 : 3|3@1+ (1,0) [0|0] "" Vector__XXX
 SG_ VCRIGHT_lumbarBState m4 : 8|3@1+ (1,0) [0|0] "" Vector__XXX
 SG_ VCRIGHT_lumbarAPressureHpa m4 : 16|16@1+ (1,0) [0|0] "" Vector__XXX
 SG_ VCRIGHT_lumbarBPressureHpa m4 : 32|16@1+ (1,0) [0|0] "" Vector__XXX
 SG_ VCRIGHT_lumbarActiveTooLongErr m4 : 48|1@1+ (1,0) [0|0] "" Vector__XXX
 SG_ VCRIGHT_lumbarMaxPErr m4 : 49|1@1+ (1,0) [0|0] "" Vector__XXX
 SG_ VCRIGHT_lumbarOvercurrentErr m4 : 50|1@1+ (1,0) [0|0] "" Vector__XXX
 SG_ VCRIGHT_lumbarMaxOperatingPErr m4 : 51|1@1+ (1,0) [0|0] "" Vector__XXX
 SG_ VCRIGHT_lumbarMinPErr m4 : 52|1@1+ (1,0) [0|0] "" Vector__XXX
 SG_ VCRIGHT_lumbarGeneralErr m4 : 53|1@1+ (1,0) [0|0] "" Vector__XXX
 SG_ VCRIGHT_lumbarDevMaxPumpPressA m4 : 54|1@1+ (1,0) [0|0] "" Vector__XXX
 SG_ VCRIGHT_lumbarDevMaxPumpPressB m4 : 55|1@1+ (1,0) [0|0] "" Vector__XXX
 SG_ VCRIGHT_frontSeatTrackPosReal m5 : 3|12@1- (1,0) [0|0] "mm" Vector__XXX
 SG_ VCRIGHT_frontSeatBackPosReal m5 : 16|12@1- (0.1,0) [0|0] "deg" Vector__XXX
 SG_ VCRIGHT_frontSeatLiftPosReal m5 : 28|12@1- (1,0) [0|0] "mm" Vector__XXX
 SG_ VCRIGHT_frontSeatTiltPosReal m5 : 40|12@1- (0.1,0) [0|0] "deg" Vector__XXX

BO_ 1280 UI_debugECU: 2 VEH
 SG_ UI_debugEcuTarget M : 0|3@1+ (1,0) [0|0] "" Vector__XXX
 SG_ UI_DI_debugEnable m1 : 8|1@1+ (1,0) [0|0] "" Vector__XXX
 SG_ UI_DIS_debugEnable m2 : 8|1@1+ (1,0) [0|0] "" Vector__XXX
 SG_ UI_PM_debugEnable m3 : 8|1@1+ (1,0) [0|0] "" Vector__XXX
 SG_ UI_PM_debugAt100Hz m3 : 9|1@1+ (1,0) [0|0] "" Vector__XXX
 SG_ UI_PMS_debugEnable m4 : 8|1@1+ (1,0) [0|0] "" Vector__XXX
 SG_ UI_PMS_debugAt100Hz m4 : 9|1@1+ (1,0) [0|0] "" Vector__XXX
 SG_ UI_BMS_debugAllEnable m5 : 8|1@1+ (1,0) [0|0] "" Vector__XXX
 SG_ UI_BMS_debugDisable m5 : 9|1@1+ (1,0) [0|0] "" Vector__XXX
 SG_ UI_VCRIGHT_debugEnable m6 : 8|1@1+ (1,0) [0|0] "" Vector__XXX
 SG_ UI_VCFRONT_debugEnable m7 : 3|1@1+ (1,0) [0|0] "" Vector__XXX

BO_ 1282 RADC_alertMatrix0: 8 CH
 SG_ RADC_a001_can1BusOff : 1|1@1+ (1,0) [0|0] "" Vector__XXX
 SG_ RADC_a002_ecuAdcError : 2|1@1+ (1,0) [0|0] "" Vector__XXX
 SG_ RADC_a003_ecuBistDisabled : 3|1@1+ (1,0) [0|0] "" Vector__XXX
 SG_ RADC_a004_ecuCrcHwError : 4|1@1+ (1,0) [0|0] "" Vector__XXX
 SG_ RADC_a005_ecuEcuMError : 5|1@1+ (1,0) [0|0] "" Vector__XXX
 SG_ RADC_a006_ecuFimError : 6|1@1+ (1,0) [0|0] "" Vector__XXX
 SG_ RADC_a007_ecuGptCheckError : 7|1@1+ (1,0) [0|0] "" Vector__XXX
 SG_ RADC_a008_ecuHwSwInterlock : 8|1@1+ (1,0) [0|0] "" Vector__XXX
 SG_ RADC_a009_plantModeActive : 9|1@1+ (1,0) [0|0] "" Vector__XXX
 SG_ RADC_a010_ecuIoHwAbError : 10|1@1+ (1,0) [0|0] "" Vector__XXX
 SG_ RADC_a011_ecuMcemError : 11|1@1+ (1,0) [0|0] "" Vector__XXX
 SG_ RADC_a012_ecuSpiError : 12|1@1+ (1,0) [0|0] "" Vector__XXX
 SG_ RADC_a013_ecuWdgError : 13|1@1+ (1,0) [0|0] "" Vector__XXX
 SG_ RADC_a014_fctSelfTestNotDone : 14|1@1+ (1,0) [0|0] "" Vector__XXX
 SG_ RADC_a015_fctSenInterference : 15|1@1+ (1,0) [0|0] "" Vector__XXX
 SG_ RADC_a016_adcOverVolt : 16|1@1+ (1,0) [0|0] "" Vector__XXX
 SG_ RADC_a017_adcUnderVolt : 17|1@1+ (1,0) [0|0] "" Vector__XXX
 SG_ RADC_a018_internalHardwareFault : 18|1@1+ (1,0) [0|0] "" Vector__XXX
 SG_ RADC_a019_internalSoftwareFault : 19|1@1+ (1,0) [0|0] "" Vector__XXX
 SG_ RADC_a020_overTemp : 20|1@1+ (1,0) [0|0] "" Vector__XXX
 SG_ RADC_a021_overTempCrit : 21|1@1+ (1,0) [0|0] "" Vector__XXX
 SG_ RADC_a022_tempImplausible : 22|1@1+ (1,0) [0|0] "" Vector__XXX
 SG_ RADC_a023_underTemp : 23|1@1+ (1,0) [0|0] "" Vector__XXX
 SG_ RADC_a024_underTempCrit : 24|1@1+ (1,0) [0|0] "" Vector__XXX
 SG_ RADC_a025_overVoltage : 25|1@1+ (1,0) [0|0] "" Vector__XXX
 SG_ RADC_a026_underVoltage : 26|1@1+ (1,0) [0|0] "" Vector__XXX
 SG_ RADC_a027_nvmFailure : 27|1@1+ (1,0) [0|0] "" Vector__XXX
 SG_ RADC_a028_rfChipError : 28|1@1+ (1,0) [0|0] "" Vector__XXX
 SG_ RADC_a029_rhcError : 29|1@1+ (1,0) [0|0] "" Vector__XXX
 SG_ RADC_a030_rspError : 30|1@1+ (1,0) [0|0] "" Vector__XXX
 SG_ RADC_a031_sensorMisaligned : 31|1@1+ (1,0) [0|0] "" Vector__XXX
 SG_ RADC_a032_sensorBlocked : 32|1@1+ (1,0) [0|0] "" Vector__XXX
 SG_ RADC_a033_sensorNeverAligned : 33|1@1+ (1,0) [0|0] "" Vector__XXX
 SG_ RADC_a034_vehDynamicsError : 34|1@1+ (1,0) [0|0] "" Vector__XXX
 SG_ RADC_a035_vinMIA : 35|1@1+ (1,0) [0|0] "" Vector__XXX
 SG_ RADC_a036_carConfigMIA : 36|1@1+ (1,0) [0|0] "" Vector__XXX
 SG_ RADC_a037_inertialSignalsMIA : 37|1@1+ (1,0) [0|0] "" Vector__XXX
 SG_ RADC_a038_steeringWheelAngleMIA : 38|1@1+ (1,0) [0|0] "" Vector__XXX
 SG_ RADC_a039_vehicleStateMIA : 39|1@1+ (1,0) [0|0] "" Vector__XXX
 SG_ RADC_a040_wheelSpeedsMIA : 40|1@1+ (1,0) [0|0] "" Vector__XXX
 SG_ RADC_a041_vinErr : 41|1@1+ (1,0) [0|0] "" Vector__XXX
 SG_ RADC_a042_carConfigErr : 42|1@1+ (1,0) [0|0] "" Vector__XXX
 SG_ RADC_a043_inertialSignalsErr : 43|1@1+ (1,0) [0|0] "" Vector__XXX
 SG_ RADC_a044_steeringWheelAngleErr : 44|1@1+ (1,0) [0|0] "" Vector__XXX
 SG_ RADC_a045_vehicleStateErr : 45|1@1+ (1,0) [0|0] "" Vector__XXX
 SG_ RADC_a046_wheelSpeedsErr : 46|1@1+ (1,0) [0|0] "" Vector__XXX
 SG_ RADC_a047_mismatchChassisType : 47|1@1+ (1,0) [0|0] "" Vector__XXX
 SG_ RADC_a048_mismatchAirSuspension : 48|1@1+ (1,0) [0|0] "" Vector__XXX
 SG_ RADC_a049_mismatchFourWheelDrive : 49|1@1+ (1,0) [0|0] "" Vector__XXX
 SG_ RADC_a050_mismatchCountry : 50|1@1+ (1,0) [0|0] "" Vector__XXX
 SG_ RADC_a051_mismatchEPASType : 51|1@1+ (1,0) [0|0] "" Vector__XXX
 SG_ RADC_a052_mismatcRadPos : 52|1@1+ (1,0) [0|0] "" Vector__XXX
 SG_ RADC_a053_emError : 53|1@1+ (1,0) [0|0] "" Vector__XXX
 SG_ RADC_a054_blockageInfo_Frame_1 : 54|1@1+ (1,0) [0|0] "" Vector__XXX
 SG_ RADC_a055_blockageInfo_Frame_2 : 55|1@1+ (1,0) [0|0] "" Vector__XXX

BO_ 1303 FC_identifier: 8 VEH
 SG_ FC_id : 0|32@1+ (1,0) [0|0] "" Vector__XXX
 SG_ FC_sessionId : 32|32@1+ (1,0) [0|0] "" Vector__XXX

BO_ 1310 FC_info: 8 VEH
 SG_ FC_infoIndex M : 0|8@1+ (1,0) [0|0] "" Vector__XXX
 SG_ FC_infoBuildType m10 : 8|3@1+ (1,0) [0|0] "" Vector__XXX
 SG_ FC_infoBuildConfigID m10 : 16|8@1+ (1,0) [0|0] "" Vector__XXX
 SG_ FC_infoHardwareID m10 : 32|16@1+ (1,0) [0|0] "" Vector__XXX
 SG_ FC_infoComponentID m10 : 48|16@1+ (1,0) [0|0] "" Vector__XXX
 SG_ FC_infoPcbaID m11 : 16|8@1+ (1,0) [0|0] "" Vector__XXX
 SG_ FC_infoAssemblyID m11 : 24|8@1+ (1,0) [0|0] "" Vector__XXX
 SG_ FC_infoUsageID m11 : 32|16@1+ (1,0) [0|0] "" Vector__XXX
 SG_ FC_infoSubUsageID m11 : 48|16@1+ (1,0) [0|0] "" Vector__XXX
 SG_ FC_infoApplicationCRC m13 : 32|32@1+ (1,0) [0|0] "" Vector__XXX
 SG_ FC_infoBootSvnRev m14 : 8|24@1+ (1,0) [0|0] "" Vector__XXX
 SG_ FC_infoBootCRC m15 : 32|32@1+ (1,0) [0|0] "" Vector__XXX
 SG_ FC_infoCPLDVersionMajor m16 : 16|8@1+ (1,0) [0|0] "" Vector__XXX
 SG_ FC_infoCPLDVersionMinor m16 : 24|8@1+ (1,0) [0|0] "" Vector__XXX
 SG_ FC_infoAppGitHashBytes m17 : 10|54@1+ (4,0) [0|0] "" Vector__XXX
 SG_ FC_infoBootGitHashBytes m18 : 10|54@1+ (4,0) [0|0] "" Vector__XXX
 SG_ FC_infoPlatformType m19 : 8|8@1+ (1,0) [0|0] "" Vector__XXX
 SG_ FC_infoMajorVersion m19 : 16|8@1+ (1,0) [0|0] "" Vector__XXX
 SG_ FC_infoBranchOrigin m19 : 24|8@1+ (1,0) [0|0] "" Vector__XXX
 SG_ FC_infoMaturity m19 : 32|8@1+ (1,0) [0|0] "" Vector__XXX
 SG_ FC_infoHardwareRevision m19 : 40|8@1+ (1,0) [0|0] "" Vector__XXX
 SG_ FC_infoBootUdsProtoVersion m20 : 8|8@1+ (1,0) [0|0] "" Vector__XXX
 SG_ FC_infoVariantCRC m22 : 32|32@1+ (1,0) [0|0] "" Vector__XXX
 SG_ FC_partNumChar01 m25 : 8|1@1+ (1,0) [0|0] "" Vector__XXX
 SG_ FC_partNumChar02 m25 : 16|1@1+ (1,0) [0|0] "" Vector__XXX
 SG_ FC_partNumChar03 m25 : 24|1@1+ (1,0) [0|0] "" Vector__XXX
 SG_ FC_partNumChar04 m25 : 32|1@1+ (1,0) [0|0] "" Vector__XXX
 SG_ FC_partNumChar05 m25 : 40|1@1+ (1,0) [0|0] "" Vector__XXX
 SG_ FC_partNumChar06 m25 : 48|1@1+ (1,0) [0|0] "" Vector__XXX
 SG_ FC_partNumChar07 m25 : 56|1@1+ (1,0) [0|0] "" Vector__XXX
 SG_ FC_partNumChar08 m26 : 8|1@1+ (1,0) [0|0] "" Vector__XXX
 SG_ FC_partNumChar09 m26 : 16|1@1+ (1,0) [0|0] "" Vector__XXX
 SG_ FC_partNumChar10 m26 : 24|1@1+ (1,0) [0|0] "" Vector__XXX
 SG_ FC_partNumChar11 m26 : 32|1@1+ (1,0) [0|0] "" Vector__XXX
 SG_ FC_partNumChar12 m26 : 40|1@1+ (1,0) [0|0] "" Vector__XXX
 SG_ FC_partNumChar13 m26 : 48|1@1+ (1,0) [0|0] "" Vector__XXX
 SG_ FC_partNumChar14 m26 : 56|1@1+ (1,0) [0|0] "" Vector__XXX
 SG_ FC_partNumChar15 m27 : 8|1@1+ (1,0) [0|0] "" Vector__XXX
 SG_ FC_partNumChar16 m27 : 16|1@1+ (1,0) [0|0] "" Vector__XXX
 SG_ FC_partNumChar17 m27 : 24|1@1+ (1,0) [0|0] "" Vector__XXX
 SG_ FC_partNumChar18 m27 : 32|1@1+ (1,0) [0|0] "" Vector__XXX
 SG_ FC_partNumChar19 m27 : 40|1@1+ (1,0) [0|0] "" Vector__XXX
 SG_ FC_partNumChar20 m27 : 48|1@1+ (1,0) [0|0] "" Vector__XXX

BO_ 1320 UTC_unixTime: 5 VEH
 SG_ UTC_unixTime : 0|32@0+ (1,0) [0|0] "sec" Vector__XXX

BO_ 1323 GTW_diskioErr: 1 VEH
 SG_ GTW_sdCmdErr : 2|1@1+ (1,0) [0|0] "" Vector__XXX
 SG_ GTW_sdIntStatusErrs : 0|1@1+ (1,0) [0|0] "" Vector__XXX
 SG_ GTW_sdReadErr : 4|1@1+ (1,0) [0|0] "" Vector__XXX
 SG_ GTW_sdTimeout : 1|1@1+ (1,0) [0|0] "" Vector__XXX
 SG_ GTW_sdWriteErr : 3|1@1+ (1,0) [0|0] "" Vector__XXX

BO_ 1329 RADC_info: 8 CH
 SG_ RADC_infoIndex M : 0|8@1+ (1,0) [0|0] "" Vector__XXX
 SG_ RADC_infoPlatformType m19 : 8|8@1+ (1,0) [0|0] "" Vector__XXX
 SG_ RADC_infoMajorVersion m19 : 16|8@1+ (1,0) [0|0] "" Vector__XXX
 SG_ RADC_infoBranchOrigin m19 : 24|8@1+ (1,0) [0|0] "" Vector__XXX
 SG_ RADC_infoMaturity m19 : 32|8@1+ (1,0) [0|0] "" Vector__XXX
 SG_ RADC_infoHardwareRevision m19 : 40|8@1+ (1,0) [0|0] "" Vector__XXX
 SG_ RADC_infoBuildType m10 : 8|8@1+ (1,0) [0|0] "" Vector__XXX
 SG_ RADC_infoBuildConfigID m10 : 16|16@1+ (1,0) [0|0] "" Vector__XXX
 SG_ RADC_infoHardwareID m10 : 32|16@1+ (1,0) [0|0] "" Vector__XXX
 SG_ RADC_infoComponentID m10 : 48|16@1+ (1,0) [0|0] "" Vector__XXX
 SG_ RADC_infoPcbaID m11 : 16|8@1+ (1,0) [0|0] "" Vector__XXX
 SG_ RADC_infoAssemblyID m11 : 24|8@1+ (1,0) [0|0] "" Vector__XXX
 SG_ RADC_infoUsageID m11 : 32|16@1+ (1,0) [0|0] "" Vector__XXX
 SG_ RADC_infoSubUsageID m11 : 48|16@1+ (1,0) [0|0] "" Vector__XXX
 SG_ RADC_infoBootUdsProtoVersion m20 : 8|8@1+ (1,0) [0|0] "" Vector__XXX
 SG_ RADC_infoBootloaderCRC m20 : 32|32@1+ (1,0) [0|0] "" Vector__XXX
 SG_ RADC_infoApplicationCRC m13 : 32|32@1+ (1,0) [0|0] "" Vector__XXX

BO_ 1337 DAS_info: 8 CH
 SG_ DAS_infoIndex M : 0|8@1+ (1,0) [0|0] "" Vector__XXX
 SG_ DAS_infoBuildType m10 : 8|8@1+ (1,0) [0|0] "" Vector__XXX
 SG_ DAS_infoBuildConfigID m10 : 16|16@1+ (1,0) [0|0] "" Vector__XXX
 SG_ DAS_infoHardwareID m10 : 32|16@1+ (1,0) [0|0] "" Vector__XXX
 SG_ DAS_infoComponentID m10 : 48|16@1+ (1,0) [0|0] "" Vector__XXX
 SG_ DAS_infoPcbaID m11 : 16|8@1+ (1,0) [0|0] "" Vector__XXX
 SG_ DAS_infoAssemblyID m11 : 24|8@1+ (1,0) [0|0] "" Vector__XXX
 SG_ DAS_infoUsageID m11 : 32|16@1+ (1,0) [0|0] "" Vector__XXX
 SG_ DAS_infoSubUsageID m11 : 48|16@1+ (1,0) [0|0] "" Vector__XXX
 SG_ DAS_infoApplicationCRC m13 : 32|32@1+ (1,0) [0|0] "" Vector__XXX
 SG_ DAS_infoBootloaderSvnRevision m14 : 8|24@1+ (1,0) [0|0] "" Vector__XXX
 SG_ DAS_infoEyeQBootCRC m16 : 16|32@1+ (1,0) [0|0] "" Vector__XXX
 SG_ DAS_infoAppGitHashBytes m17 : 10|54@1+ (4,0) [0|0] "" Vector__XXX
 SG_ DAS_infoBootGitHashBytes m18 : 10|54@1+ (4,0) [0|0] "" Vector__XXX
 SG_ DAS_infoPlatformType m19 : 8|8@1+ (1,0) [0|0] "" Vector__XXX
 SG_ DAS_infoMajorVersion m19 : 16|8@1+ (1,0) [0|0] "" Vector__XXX
 SG_ DAS_infoBranchOrigin m19 : 24|8@1+ (1,0) [0|0] "" Vector__XXX
 SG_ DAS_infoMaturity m19 : 32|8@1+ (1,0) [0|0] "" Vector__XXX
 SG_ DAS_infoHardwareRevision m19 : 40|8@1+ (1,0) [0|0] "" Vector__XXX
 SG_ DAS_infoBootUdsProtoVersion m20 : 8|8@1+ (1,0) [0|0] "" Vector__XXX
 SG_ DAS_infoBootloaderCRC m20 : 32|32@1+ (1,0) [0|0] "" Vector__XXX
 SG_ DAS_infoEyeQAppCRC m23 : 16|32@1+ (1,0) [0|0] "" Vector__XXX
 SG_ DAS_infoEyeQFfsCRC m24 : 16|32@1+ (1,0) [0|0] "" Vector__XXX

BO_ 1342 CP_info: 8 VEH
 SG_ CP_infoIndex M : 0|8@1+ (1,0) [0|0] "" Vector__XXX
 SG_ CP_buildType m10 : 8|3@1+ (1,0) [0|0] "" Vector__XXX
 SG_ CP_buildConfigId m10 : 16|16@1+ (1,0) [0|0] "" Vector__XXX
 SG_ CP_hardwareId m10 : 32|16@1+ (1,0) [0|0] "" Vector__XXX
 SG_ CP_componentId m10 : 48|16@1+ (1,0) [0|0] "" Vector__XXX
 SG_ CP_pcbaId m11 : 16|8@1+ (1,0) [0|0] "" Vector__XXX
 SG_ CP_assemblyId m11 : 24|8@1+ (1,0) [0|0] "" Vector__XXX
 SG_ CP_usageId m11 : 32|16@1+ (1,0) [0|0] "" Vector__XXX
 SG_ CP_subUsageId m11 : 48|16@1+ (1,0) [0|0] "" Vector__XXX
 SG_ CP_platformType m13 : 8|8@1+ (1,0) [0|0] "" Vector__XXX
 SG_ CP_appCrc m13 : 32|32@1+ (1,0) [0|0] "" Vector__XXX
 SG_ CP_appGitHash m17 : 10|54@1+ (4,0) [0|0] "" Vector__XXX
 SG_ CP_bootGitHash m18 : 10|54@1+ (4,0) [0|0] "" Vector__XXX
 SG_ CP_bootUdsProtoVersion m20 : 8|8@1+ (1,0) [0|0] "" Vector__XXX
 SG_ CP_bootCrc m20 : 32|32@1+ (1,0) [0|0] "" Vector__XXX

BO_ 1345 FC_maxLimits: 8 VEH
 SG_ FC_maxCurrentLimit : 16|13@1+ (0.0732422,0) [0|0] "A" Vector__XXX
 SG_ FC_maxPowerLimit : 0|13@1+ (0.0622559,0) [0|0] "kW" Vector__XXX

BO_ 1353 APP_info: 8 CH
 SG_ APP_infoIndex M : 0|8@1+ (1,0) [0|0] "" Vector__XXX
 SG_ APP_buildType m0 : 8|8@1+ (1,0) [0|0] "" Vector__XXX
 SG_ APP_infoAppFwGitHashBytes m1 : 10|54@1+ (4,0) [0|0] "" Vector__XXX
 SG_ APP_infoAppApGitHashBytes m2 : 10|54@1+ (4,0) [0|0] "" Vector__XXX

BO_ 1355 SCM_alertMatrix2: 8 VEH
 SG_ SCM_a065_vBatRationalityStage1 : 0|1@1+ (1,0) [0|0] "" Vector__XXX
 SG_ SCM_a066_vBatRationalityStage2 : 1|1@1+ (1,0) [0|0] "" Vector__XXX
 SG_ SCM_a067_vBatRationalityStage3 : 2|1@1+ (1,0) [0|0] "" Vector__XXX
 SG_ SCM_a068_vBatRationalityStage4 : 3|1@1+ (1,0) [0|0] "" Vector__XXX
 SG_ SCM_a069_vStageRationalityV1 : 4|1@1+ (1,0) [0|0] "" Vector__XXX
 SG_ SCM_a070_vStageRationalityV2 : 5|1@1+ (1,0) [0|0] "" Vector__XXX
 SG_ SCM_a071_chargerMIA : 6|1@1+ (1,0) [0|0] "" Vector__XXX
 SG_ SCM_a072_gtwMIA : 7|1@1+ (1,0) [0|0] "" Vector__XXX
 SG_ SCM_a073_lccMIA : 8|1@1+ (1,0) [0|0] "" Vector__XXX
 SG_ SCM_a074_isoVDiffHi : 9|1@1+ (1,0) [0|0] "" Vector__XXX
 SG_ SCM_a075_leakageTestAbsDecayLow : 10|1@1+ (1,0) [0|0] "" Vector__XXX
 SG_ SCM_a076_bmsMIA : 11|1@1+ (1,0) [0|0] "" Vector__XXX
 SG_ SCM_a077_unexpectedVbatBehavior : 12|1@1+ (1,0) [0|0] "" Vector__XXX
 SG_ SCM_a078_voltageMatchTimeout : 13|1@1+ (1,0) [0|0] "" Vector__XXX
 SG_ SCM_a079_unexpectedVbat : 14|1@1+ (1,0) [0|0] "" Vector__XXX
 SG_ SCM_a080_lccFaulted : 15|1@1+ (1,0) [0|0] "" Vector__XXX
 SG_ SCM_a081_rmsInputVoltageHigh : 16|1@1+ (1,0) [0|0] "" Vector__XXX
 SG_ SCM_a082_VbatUV : 17|1@1+ (1,0) [0|0] "" Vector__XXX
 SG_ SCM_a083_chargeCurrentLimited : 18|1@1+ (1,0) [0|0] "" Vector__XXX
 SG_ SCM_a084_unused84 : 19|1@1+ (1,0) [0|0] "" Vector__XXX
 SG_ SCM_a085_unused85 : 20|1@1+ (1,0) [0|0] "" Vector__XXX
 SG_ SCM_a086_lccResetDetected : 21|1@1+ (1,0) [0|0] "" Vector__XXX
 SG_ SCM_a087_posCordTempRationality : 22|1@1+ (1,0) [0|0] "" Vector__XXX
 SG_ SCM_a088_negCordTempRationality : 23|1@1+ (1,0) [0|0] "" Vector__XXX
 SG_ SCM_a089_posCordOT : 24|1@1+ (1,0) [0|0] "" Vector__XXX
 SG_ SCM_a090_negCordOT : 25|1@1+ (1,0) [0|0] "" Vector__XXX
 SG_ SCM_a091_voltageRiseDetection : 26|1@1+ (1,0) [0|0] "" Vector__XXX
 SG_ SCM_a092_cabEnableDeasserted : 27|1@1+ (1,0) [0|0] "" Vector__XXX
 SG_ SCM_a093_unused93 : 28|1@1+ (1,0) [0|0] "" Vector__XXX
 SG_ SCM_a094_unused94 : 29|1@1+ (1,0) [0|0] "" Vector__XXX
 SG_ SCM_a095_unused95 : 30|1@1+ (1,0) [0|0] "" Vector__XXX
 SG_ SCM_a096_unused96 : 31|1@1+ (1,0) [0|0] "" Vector__XXX
 SG_ SCM_a097_unused97 : 32|1@1+ (1,0) [0|0] "" Vector__XXX
 SG_ SCM_a098_unused98 : 33|1@1+ (1,0) [0|0] "" Vector__XXX
 SG_ SCM_a099_unused99 : 34|1@1+ (1,0) [0|0] "" Vector__XXX
 SG_ SCM_a100_unused100 : 35|1@1+ (1,0) [0|0] "" Vector__XXX
 SG_ SCM_a101_unused101 : 36|1@1+ (1,0) [0|0] "" Vector__XXX
 SG_ SCM_a102_unused102 : 37|1@1+ (1,0) [0|0] "" Vector__XXX
 SG_ SCM_a103_unused103 : 38|1@1+ (1,0) [0|0] "" Vector__XXX
 SG_ SCM_a104_unused104 : 39|1@1+ (1,0) [0|0] "" Vector__XXX
 SG_ SCM_a105_unused105 : 40|1@1+ (1,0) [0|0] "" Vector__XXX
 SG_ SCM_a106_unused106 : 41|1@1+ (1,0) [0|0] "" Vector__XXX
 SG_ SCM_a107_unused107 : 42|1@1+ (1,0) [0|0] "" Vector__XXX
 SG_ SCM_a108_unused108 : 43|1@1+ (1,0) [0|0] "" Vector__XXX
 SG_ SCM_a109_unused109 : 44|1@1+ (1,0) [0|0] "" Vector__XXX
 SG_ SCM_a110_unused110 : 45|1@1+ (1,0) [0|0] "" Vector__XXX
 SG_ SCM_a111_unused111 : 46|1@1+ (1,0) [0|0] "" Vector__XXX
 SG_ SCM_a112_unused112 : 47|1@1+ (1,0) [0|0] "" Vector__XXX
 SG_ SCM_a113_unused113 : 48|1@1+ (1,0) [0|0] "" Vector__XXX
 SG_ SCM_a114_unused114 : 49|1@1+ (1,0) [0|0] "" Vector__XXX
 SG_ SCM_a115_unused115 : 50|1@1+ (1,0) [0|0] "" Vector__XXX
 SG_ SCM_a116_unused116 : 51|1@1+ (1,0) [0|0] "" Vector__XXX
 SG_ SCM_a117_unused117 : 52|1@1+ (1,0) [0|0] "" Vector__XXX
 SG_ SCM_a118_unused118 : 53|1@1+ (1,0) [0|0] "" Vector__XXX
 SG_ SCM_a119_unused119 : 54|1@1+ (1,0) [0|0] "" Vector__XXX
 SG_ SCM_a120_unused120 : 55|1@1+ (1,0) [0|0] "" Vector__XXX
 SG_ SCM_a121_unused121 : 56|1@1+ (1,0) [0|0] "" Vector__XXX
 SG_ SCM_a122_unused122 : 57|1@1+ (1,0) [0|0] "" Vector__XXX
 SG_ SCM_a123_unused123 : 58|1@1+ (1,0) [0|0] "" Vector__XXX
 SG_ SCM_a124_unused124 : 59|1@1+ (1,0) [0|0] "" Vector__XXX
 SG_ SCM_a125_unused125 : 60|1@1+ (1,0) [0|0] "" Vector__XXX
 SG_ SCM_a126_unused126 : 61|1@1+ (1,0) [0|0] "" Vector__XXX
 SG_ SCM_a127_unused127 : 62|1@1+ (1,0) [0|0] "" Vector__XXX
 SG_ SCM_a128_unused128 : 63|1@1+ (1,0) [0|0] "" Vector__XXX

BO_ 1357 TAS_info: 8 VEH
 SG_ TAS_infoIndex M : 0|8@1+ (1,0) [0|0] "" Vector__XXX
 SG_ TAS_infoBuildType m10 : 8|3@1+ (1,0) [0|0] "" Vector__XXX
 SG_ TAS_infoBuildConfigId m10 : 16|16@1+ (1,0) [0|0] "" Vector__XXX
 SG_ TAS_infoHardwareId m10 : 32|1@1+ (1,0) [0|0] "" Vector__XXX
 SG_ TAS_infoComponentId m10 : 48|16@1+ (1,0) [0|0] "" Vector__XXX
 SG_ TAS_infoPcbaId m11 : 16|8@1+ (1,0) [0|0] "" Vector__XXX
 SG_ TAS_infoAssemblyId m11 : 24|8@1+ (1,0) [0|0] "" Vector__XXX
 SG_ TAS_infoUsageId m11 : 32|16@1+ (1,0) [0|0] "" Vector__XXX
 SG_ TAS_infoSubUsageId m11 : 48|16@1+ (1,0) [0|0] "" Vector__XXX
 SG_ TAS_infoAppCrc m13 : 32|32@1+ (1,0) [0|0] "" Vector__XXX
 SG_ TAS_infoBootloaderSvnRevision m14 : 8|24@1+ (1,0) [0|0] "" Vector__XXX
 SG_ TAS_infoAppGitHash m17 : 10|54@1+ (4,0) [0|0] "" Vector__XXX
 SG_ TAS_infoBootGitHash m18 : 10|54@1+ (4,0) [0|0] "" Vector__XXX
 SG_ TAS_infoPlatformType m19 : 8|8@1+ (1,0) [0|0] "" Vector__XXX
 SG_ TAS_infoMajorVersion m19 : 16|8@1+ (1,0) [0|0] "" Vector__XXX
 SG_ TAS_infoBranchOrigin m19 : 24|8@1+ (1,0) [0|0] "" Vector__XXX
 SG_ TAS_infoMaturity m19 : 32|8@1+ (1,0) [0|0] "" Vector__XXX
 SG_ TAS_infoHardwareRevision m19 : 40|8@1+ (1,0) [0|0] "" Vector__XXX
 SG_ TAS_infoBootUdsProtoVersion m20 : 8|8@1+ (1,0) [0|0] "" Vector__XXX
 SG_ TAS_infoBootCrc m20 : 32|32@1+ (1,0) [0|0] "" Vector__XXX

BO_ 1359 SCCM_alertMatrix: 8 VEH
 SG_ SCCM_matrixIndex M : 0|4@1+ (1,0) [0|0] "" Vector__XXX
 SG_ SCCM_a001_CANBusOff m0 : 4|1@1+ (1,0) [0|0] "" Vector__XXX
 SG_ SCCM_a002_CANTOut m0 : 5|1@1+ (1,0) [0|0] "" Vector__XXX
 SG_ SCCM_a003_highBeamOpen m0 : 6|1@1+ (1,0) [0|0] "" Vector__XXX
 SG_ SCCM_a004_highBeamShortToGND m0 : 7|1@1+ (1,0) [0|0] "" Vector__XXX
 SG_ SCCM_a005_tipWipeOpen m0 : 8|1@1+ (1,0) [0|0] "" Vector__XXX
 SG_ SCCM_a006_tipWipeShortToGND m0 : 9|1@1+ (1,0) [0|0] "" Vector__XXX
 SG_ SCCM_a007_turnIndComInfo m0 : 10|1@1+ (1,0) [0|0] "" Vector__XXX
 SG_ SCCM_a008_turnIndInvalidTrans m0 : 11|1@1+ (1,0) [0|0] "" Vector__XXX
 SG_ SCCM_a009_turnIndOpen m0 : 12|1@1+ (1,0) [0|0] "" Vector__XXX
 SG_ SCCM_a010_turnIndShortToGnd m0 : 13|1@1+ (1,0) [0|0] "" Vector__XXX
 SG_ SCCM_a011_turnIndHWErr m0 : 14|1@1+ (1,0) [0|0] "" Vector__XXX
 SG_ SCCM_a012_turnGenErr m0 : 15|1@1+ (1,0) [0|0] "" Vector__XXX
 SG_ SCCM_a013_voltageHigh m0 : 16|1@1+ (1,0) [0|0] "" Vector__XXX
 SG_ SCCM_a014_voltageLow m0 : 17|1@1+ (1,0) [0|0] "" Vector__XXX
 SG_ SCCM_a015_softwareError m0 : 18|1@1+ (1,0) [0|0] "" Vector__XXX
 SG_ SCCM_a016_hardwareError m0 : 19|1@1+ (1,0) [0|0] "" Vector__XXX
 SG_ SCCM_a017_memoryError m0 : 20|1@1+ (1,0) [0|0] "" Vector__XXX
 SG_ SCCM_a018_angleSpeedOutOfRange m0 : 21|1@1+ (1,0) [0|0] "" Vector__XXX
 SG_ SCCM_a019_angleSpeedAboveLimit m0 : 22|1@1+ (1,0) [0|0] "" Vector__XXX
 SG_ SCCM_a020_angleInternalError m0 : 23|1@1+ (1,0) [0|0] "" Vector__XXX
 SG_ SCCM_a021_gearStalkSignalInvalid m0 : 24|1@1+ (1,0) [0|0] "" Vector__XXX
 SG_ SCCM_a022_gearStalkOpenCircuit m0 : 25|1@1+ (1,0) [0|0] "" Vector__XXX
 SG_ SCCM_a023_gearStalkShortCircuit m0 : 26|1@1+ (1,0) [0|0] "" Vector__XXX
 SG_ SCCM_a024_gearStalkGenErr m0 : 27|1@1+ (1,0) [0|0] "" Vector__XXX
 SG_ SCCM_a025_runTimeError m0 : 28|1@1+ (1,0) [0|0] "" Vector__XXX
 SG_ SCCM_a026_parkButtonInvalidSignal m0 : 29|1@1+ (1,0) [0|0] "" Vector__XXX
 SG_ SCCM_a027_parkButtonOpenCircuit m0 : 30|1@1+ (1,0) [0|0] "" Vector__XXX
 SG_ SCCM_a028_parkButtonShortToGround m0 : 31|1@1+ (1,0) [0|0] "" Vector__XXX
 SG_ SCCM_a029_parkButtonMalfunction m0 : 32|1@1+ (1,0) [0|0] "" Vector__XXX

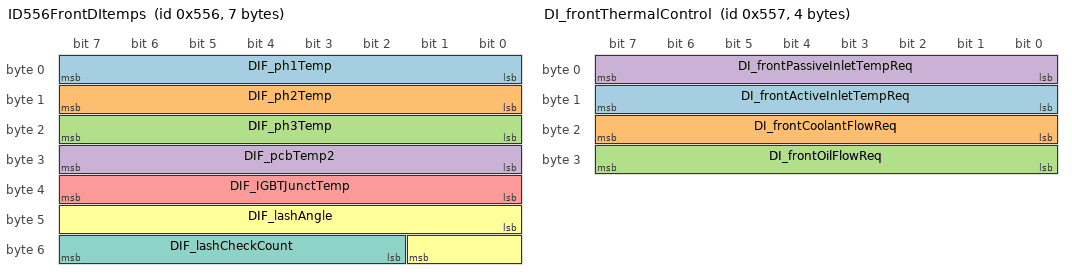
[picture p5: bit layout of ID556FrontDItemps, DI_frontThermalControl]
BO_ 1366 ID556FrontDItemps: 7 VehicleBus
 SG_ DIF_ph1Temp : 0|8@1+ (1,-40) [-40|120] "C"   X
 SG_ DIF_ph2Temp : 8|8@1+ (1,-40) [-40|120] "C"   X
 SG_ DIF_ph3Temp : 16|8@1+ (1,-40) [-40|120] "C"   X
 SG_ DIF_pcbTemp2 : 24|8@1+ (1,-40) [-40|150] "C"   X
 SG_ DIF_IGBTJunctTemp : 32|8@1+ (1,-40) [-40|200] "C"   X
 SG_ DIF_lashAngle : 40|10@1+ (0.06,0) [0|60] "Deg"   X
 SG_ DIF_lashCheckCount : 50|6@1+ (1,0) [0|63] ""   X

BO_ 1367 DI_frontThermalControl: 4 VEH
 SG_ DI_frontActiveInletTempReq : 8|8@1+ (1,-40) [-40|120] "C" Vector__XXX
 SG_ DI_frontCoolantFlowReq : 16|8@1+ (0.2,0) [0|50] "LPM" Vector__XXX
 SG_ DI_frontOilFlowReq : 24|8@1+ (0.06,0) [0|15] "LPM" Vector__XXX
 SG_ DI_frontPassiveInletTempReq : 0|8@1+ (1,-40) [-40|120] "C" Vector__XXX

BO_ 1376 GTW_factoryEcuPresent: 4 VEH
 SG_ GTW_BMSpresent : 0|1@1+ (1,0) [0|0] "" Vector__XXX
 SG_ GTW_CMPpresent : 23|1@1+ (1,0) [0|0] "" Vector__XXX
 SG_ GTW_CPpresent : 26|1@1+ (1,0) [0|0] "" Vector__XXX
 SG_ GTW_DASpresent : 24|1@1+ (1,0) [0|0] "" Vector__XXX
 SG_ GTW_DISpresent : 2|1@1+ (1,0) [0|0] "" Vector__XXX
 SG_ GTW_DIpresent : 1|1@1+ (1,0) [0|0] "" Vector__XXX
 SG_ GTW_EPAS3Ppresent : 3|1@1+ (1,0) [0|0] "" Vector__XXX
 SG_ GTW_EPAS3Spresent : 22|1@1+ (1,0) [0|0] "" Vector__XXX
 SG_ GTW_EPBLpresent : 4|1@1+ (1,0) [0|0] "" Vector__XXX
 SG_ GTW_EPBRpresent : 5|1@1+ (1,0) [0|0] "" Vector__XXX
 SG_ GTW_ESPpresent : 6|1@1+ (1,0) [0|0] "" Vector__XXX
 SG_ GTW_HVPpresent : 7|1@1+ (1,0) [0|0] "" Vector__XXX
 SG_ GTW_IBSTpresent : 8|1@1+ (1,0) [0|0] "" Vector__XXX
 SG_ GTW_OCS1Ppresent : 9|1@1+ (1,0) [0|0] "" Vector__XXX
 SG_ GTW_PARKpresent : 10|1@1+ (1,0) [0|0] "" Vector__XXX
 SG_ GTW_PCSpresent : 11|1@1+ (1,0) [0|0] "" Vector__XXX
 SG_ GTW_PMSpresent : 13|1@1+ (1,0) [0|0] "" Vector__XXX
 SG_ GTW_PMpresent : 12|1@1+ (1,0) [0|0] "" Vector__XXX
 SG_ GTW_PTCpresent : 25|1@1+ (1,0) [0|0] "" Vector__XXX
 SG_ GTW_RADCpresent : 14|1@1+ (1,0) [0|0] "" Vector__XXX
 SG_ GTW_RCMpresent : 15|1@1+ (1,0) [0|0] "" Vector__XXX
 SG_ GTW_SCCMpresent : 16|1@1+ (1,0) [0|0] "" Vector__XXX
 SG_ GTW_SWCpresent : 27|1@1+ (1,0) [0|0] "" Vector__XXX
 SG_ GTW_TPMSpresent : 18|1@1+ (1,0) [0|0] "" Vector__XXX
 SG_ GTW_VCFRONTpresent : 19|1@1+ (1,0) [0|0] "" Vector__XXX
 SG_ GTW_VCLEFTpresent : 20|1@1+ (1,0) [0|0] "" Vector__XXX
 SG_ GTW_VCRIGHTpresent : 21|1@1+ (1,0) [0|0] "" Vector__XXX
 SG_ GTW_VCSECpresent : 17|1@1+ (1,0) [0|0] "" Vector__XXX

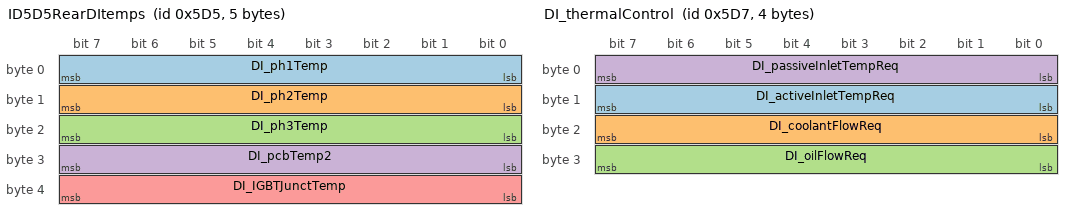
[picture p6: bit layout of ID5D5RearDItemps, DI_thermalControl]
BO_ 1493 ID5D5RearDItemps: 5 VehicleBus
 SG_ DI_ph1Temp : 0|8@1+ (1,-40) [-40|120] "C"   X
 SG_ DI_ph2Temp : 8|8@1+ (1,-40) [-40|120] "C"   X
 SG_ DI_ph3Temp : 16|8@1+ (1,-40) [-40|120] "C"   X
 SG_ DI_pcbTemp2 : 24|8@1+ (1,-40) [-40|150] "C"   X
 SG_ DI_IGBTJunctTemp : 32|8@1+ (1,-40) [-40|200] "C"   X

BO_ 1495 DI_thermalControl: 4 VEH
 SG_ DI_activeInletTempReq : 8|8@1+ (1,-40) [0|0] "DegC" Vector__XXX
 SG_ DI_coolantFlowReq : 16|8@1+ (0.2,0) [0|0] "LPM" Vector__XXX
 SG_ DI_oilFlowReq : 24|8@1+ (0.06,0) [0|15] "LPM" Vector__XXX
 SG_ DI_passiveInletTempReq : 0|8@1+ (1,-40) [0|0] "DegC" Vector__XXX

BO_ 1519 TPMS_info: 8 CH
 SG_ TPMS_infoIndex M : 0|8@1+ (1,0) [0|0] "" Vector__XXX
 SG_ TPMS_infoComponentID m10 : 48|16@1+ (1,0) [0|0] "" Vector__XXX
 SG_ TPMS_infoPcbaID m11 : 16|8@1+ (1,0) [0|0] "" Vector__XXX
 SG_ TPMS_infoAssemblyID m11 : 24|8@1+ (1,0) [0|0] "" Vector__XXX
 SG_ TPMS_infoUsageID m11 : 32|16@1+ (1,0) [0|0] "" Vector__XXX
 SG_ TPMS_infoBootUdsProtoVersion m20 : 8|8@1+ (1,0) [0|0] "" Vector__XXX
 SG_ TPMS_infoBootloaderCRC m20 : 32|32@1+ (1,0) [0|0] "" Vector__XXX
 SG_ TPMS_infoApplicationCRC m13 : 32|32@1+ (1,0) [0|0] "" Vector__XXX

BO_ 1523 UI_alertLog: 8 VEH
 SG_ UI_alertID M : 0|6@1+ (1,0) [0|0] "" Vector__XXX
 SG_ UI_alertState : 15|1@1+ (1,0) [0|0] "" Vector__XXX
 SG_ UI_a034_BackupCamera m34 : 16|1@1+ (1,0) [0|0] "" Vector__XXX
 SG_ UI_a034_Tuner m34 : 17|1@1+ (1,0) [0|0] "" Vector__XXX
 SG_ UI_a034_Bluetooth m34 : 18|1@1+ (1,0) [0|0] "" Vector__XXX
 SG_ UI_a034_WiFi m34 : 19|1@1+ (1,0) [0|0] "" Vector__XXX
 SG_ UI_a034_Cellular m34 : 20|1@1+ (1,0) [0|0] "" Vector__XXX
 SG_ UI_a034_TouchScreen m34 : 21|1@1+ (1,0) [0|0] "" Vector__XXX
 SG_ UI_a034_Display m34 : 22|1@1+ (1,0) [0|0] "" Vector__XXX
 SG_ UI_a034_Audio m34 : 23|1@1+ (1,0) [0|0] "" Vector__XXX
 SG_ UI_a034_FatalWakeup m34 : 24|1@1+ (1,0) [0|0] "" Vector__XXX
 SG_ UI_a034_UnknownWakeupError m34 : 25|1@1+ (1,0) [0|0] "" Vector__XXX
 SG_ UI_a006_remoteServiceAlertCode m6 : 16|32@1+ (1,0) [0|0] "" Vector__XXX

BO_ 1536 ID600_UDS_vcfrontRequest: 8 VEH
 SG_ UDS_vcfrontRequestData: 0|54@0+ (1024,0) [0|0] "" X

BO_ 1537 ID601_VCFRONT_udsResponse: 8 VEH
 SG_ VCFRONT_udsResponseData: 0|54@0+ (1024,0) [0|0] "" X

BO_ 1538 ID602_UDS_bmsRequest: 8 VEH
 SG_ UDS_bmsRequestData: 0|54@0+ (1024,0) [0|0] "" X

BO_ 1539 ID603_UDS_cmpRequest: 8 VEH
 SG_ UDS_cmpRequestData: 0|54@0+ (1024,0) [0|0] "" X

BO_ 1540 ID604_UDS_pmRequest: 8 VEH
 SG_ UDS_pmRequestData: 0|54@0+ (1024,0) [0|0] "" X

BO_ 1541 ID605_UDS_disRequest: 8 VEH
 SG_ UDS_disRequestData: 0|54@0+ (1024,0) [0|0] "" X

BO_ 1542 ID606_UDS_diRequest: 8 VEH
 SG_ UDS_diRequestData: 0|54@0+ (1024,0) [0|0] "" X

BO_ 1544 ID608_UDS_vcrightRequest: 8 VEH
 SG_ UDS_vcrightRequestData_H: 0|32@0+ (1,0) [0|0] "" X
 SG_ UDS_vcrightRequestData_L: 32|32@0+ (1,0) [0|0] "" X

BO_ 1545 ID609_VCRIGHT_udsResponse: 8 VEH
 SG_ VCRIGHT_udsResponseData_H: 0|32@0+ (1,0) [0|0] "" X
 SG_ VCRIGHT_udsResponseData_L: 32|32@0+ (1,0) [0|0] "" X

BO_ 1546 ID60A_UDS_vcsecRequest: 8 VEH
 SG_ UDS_vcsecRequestData: 0|54@0+ (1024,0) [0|0] "" X

BO_ 1547 ID60B_VCSEC_udsResponse: 8 VEH
 SG_ VCSEC_udsResponseData: 0|54@0+ (1024,0) [0|0] "" X

BO_ 1548 DAS_telemetryRadar: 8 VEH
 SG_ DAS_TR_Counter : 54|2@1+ (1,0) [0|0] "" Vector__XXX
 SG_ DAS_TR_ObjIndex M : 0|5@1+ (1,0) [0|0] "" Vector__XXX
 SG_ DAS_TR_Obj00_Class m0 : 5|3@1+ (1,0) [0|0] "" Vector__XXX
 SG_ DAS_TR_Obj00_Dx m0 : 8|10@1+ (0.15625,0) [0|0] "m" Vector__XXX
 SG_ DAS_TR_Obj00_Dy m0 : 18|6@1+ (0.5,-15.5) [0|0] "m" Vector__XXX
 SG_ DAS_TR_Obj00_Vx m0 : 24|8@1+ (0.5,-63.5) [0|0] "m/s" Vector__XXX
 SG_ DAS_TR_Obj00_RCS m0 : 32|8@1+ (0.25,-14) [0|0] "dB" Vector__XXX
 SG_ DAS_TR_Obj00_Length m0 : 40|6@1+ (0.125,0) [0|0] "m" Vector__XXX
 SG_ DAS_TR_Obj00_MovingState m0 : 46|2@1+ (1,0) [0|0] "" Vector__XXX
 SG_ DAS_TR_Obj00_Dz m0 : 48|6@1+ (0.25,-5) [0|0] "m" Vector__XXX
 SG_ DAS_TR_Obj00_Exist m0 : 56|5@1+ (3.125,0) [0|0] "%" Vector__XXX
 SG_ DAS_TR_Obj01_Class m1 : 5|3@1+ (1,0) [0|0] "" Vector__XXX
 SG_ DAS_TR_Obj01_Dx m1 : 8|10@1+ (0.15625,0) [0|0] "m" Vector__XXX
 SG_ DAS_TR_Obj01_Dy m1 : 18|6@1+ (0.5,-15.5) [0|0] "m" Vector__XXX
 SG_ DAS_TR_Obj01_Vx m1 : 24|8@1+ (0.5,-63.5) [0|0] "m/s" Vector__XXX
 SG_ DAS_TR_Obj01_RCS m1 : 32|8@1+ (0.25,-14) [0|0] "dB" Vector__XXX
 SG_ DAS_TR_Obj01_Length m1 : 40|6@1+ (0.125,0) [0|0] "m" Vector__XXX
 SG_ DAS_TR_Obj01_MovingState m1 : 46|2@1+ (1,0) [0|0] "" Vector__XXX
 SG_ DAS_TR_Obj01_Dz m1 : 48|6@1+ (0.25,-5) [0|0] "m" Vector__XXX
 SG_ DAS_TR_Obj01_Exist m1 : 56|5@1+ (3.125,0) [0|0] "%" Vector__XXX
 SG_ DAS_TR_Obj02_Class m2 : 5|3@1+ (1,0) [0|0] "" Vector__XXX
 SG_ DAS_TR_Obj02_Dx m2 : 8|10@1+ (0.15625,0) [0|0] "m" Vector__XXX
 SG_ DAS_TR_Obj02_Dy m2 : 18|6@1+ (0.5,-15.5) [0|0] "m" Vector__XXX
 SG_ DAS_TR_Obj02_Vx m2 : 24|8@1+ (0.5,-63.5) [0|0] "m/s" Vector__XXX
 SG_ DAS_TR_Obj02_RCS m2 : 32|8@1+ (0.25,-14) [0|0] "dB" Vector__XXX
 SG_ DAS_TR_Obj02_Length m2 : 40|6@1+ (0.125,0) [0|0] "m" Vector__XXX
 SG_ DAS_TR_Obj02_MovingState m2 : 46|2@1+ (1,0) [0|0] "" Vector__XXX
 SG_ DAS_TR_Obj02_Dz m2 : 48|6@1+ (0.25,-5) [0|0] "m" Vector__XXX
 SG_ DAS_TR_Obj02_Exist m2 : 56|5@1+ (3.125,0) [0|0] "%" Vector__XXX
 SG_ DAS_TR_Obj03_Class m3 : 5|3@1+ (1,0) [0|0] "" Vector__XXX
 SG_ DAS_TR_Obj03_Dx m3 : 8|10@1+ (0.15625,0) [0|0] "m" Vector__XXX
 SG_ DAS_TR_Obj03_Dy m3 : 18|6@1+ (0.5,-15.5) [0|0] "m" Vector__XXX
 SG_ DAS_TR_Obj03_Vx m3 : 24|8@1+ (0.5,-63.5) [0|0] "m/s" Vector__XXX
 SG_ DAS_TR_Obj03_RCS m3 : 32|8@1+ (0.25,-14) [0|0] "dB" Vector__XXX
 SG_ DAS_TR_Obj03_Length m3 : 40|6@1+ (0.125,0) [0|0] "m" Vector__XXX
 SG_ DAS_TR_Obj03_MovingState m3 : 46|2@1+ (1,0) [0|0] "" Vector__XXX
 SG_ DAS_TR_Obj03_Dz m3 : 48|6@1+ (0.25,-5) [0|0] "m" Vector__XXX
 SG_ DAS_TR_Obj03_Exist m3 : 56|5@1+ (3.125,0) [0|0] "%" Vector__XXX
 SG_ DAS_TR_Obj04_Class m4 : 5|3@1+ (1,0) [0|0] "" Vector__XXX
 SG_ DAS_TR_Obj04_Dx m4 : 8|10@1+ (0.15625,0) [0|0] "m" Vector__XXX
 SG_ DAS_TR_Obj04_Dy m4 : 18|6@1+ (0.5,-15.5) [0|0] "m" Vector__XXX
 SG_ DAS_TR_Obj04_Vx m4 : 24|8@1+ (0.5,-63.5) [0|0] "m/s" Vector__XXX
 SG_ DAS_TR_Obj04_RCS m4 : 32|8@1+ (0.25,-14) [0|0] "dB" Vector__XXX
 SG_ DAS_TR_Obj04_Length m4 : 40|6@1+ (0.125,0) [0|0] "m" Vector__XXX
 SG_ DAS_TR_Obj04_MovingState m4 : 46|2@1+ (1,0) [0|0] "" Vector__XXX
 SG_ DAS_TR_Obj04_Dz m4 : 48|6@1+ (0.25,-5) [0|0] "m" Vector__XXX
 SG_ DAS_TR_Obj04_Exist m4 : 56|5@1+ (3.125,0) [0|0] "%" Vector__XXX
 SG_ DAS_TR_Obj05_Class m5 : 5|3@1+ (1,0) [0|0] "" Vector__XXX
 SG_ DAS_TR_Obj05_Dx m5 : 8|10@1+ (0.15625,0) [0|0] "m" Vector__XXX
 SG_ DAS_TR_Obj05_Dy m5 : 18|6@1+ (0.5,-15.5) [0|0] "m" Vector__XXX
 SG_ DAS_TR_Obj05_Vx m5 : 24|8@1+ (0.5,-63.5) [0|0] "m/s" Vector__XXX
 SG_ DAS_TR_Obj05_RCS m5 : 32|8@1+ (0.25,-14) [0|0] "dB" Vector__XXX
 SG_ DAS_TR_Obj05_Length m5 : 40|6@1+ (0.125,0) [0|0] "m" Vector__XXX
 SG_ DAS_TR_Obj05_MovingState m5 : 46|2@1+ (1,0) [0|0] "" Vector__XXX
 SG_ DAS_TR_Obj05_Dz m5 : 48|6@1+ (0.25,-5) [0|0] "m" Vector__XXX
 SG_ DAS_TR_Obj05_Exist m5 : 56|5@1+ (3.125,0) [0|0] "%" Vector__XXX
 SG_ DAS_TR_Obj06_Class m6 : 5|3@1+ (1,0) [0|0] "" Vector__XXX
 SG_ DAS_TR_Obj06_Dx m6 : 8|10@1+ (0.15625,0) [0|0] "m" Vector__XXX
 SG_ DAS_TR_Obj06_Dy m6 : 18|6@1+ (0.5,-15.5) [0|0] "m" Vector__XXX
 SG_ DAS_TR_Obj06_Vx m6 : 24|8@1+ (0.5,-63.5) [0|0] "m/s" Vector__XXX
 SG_ DAS_TR_Obj06_RCS m6 : 32|8@1+ (0.25,-14) [0|0] "dB" Vector__XXX
 SG_ DAS_TR_Obj06_Length m6 : 40|6@1+ (0.125,0) [0|0] "m" Vector__XXX
 SG_ DAS_TR_Obj06_MovingState m6 : 46|2@1+ (1,0) [0|0] "" Vector__XXX
 SG_ DAS_TR_Obj06_Dz m6 : 48|6@1+ (0.25,-5) [0|0] "m" Vector__XXX
 SG_ DAS_TR_Obj06_Exist m6 : 56|5@1+ (3.125,0) [0|0] "%" Vector__XXX
 SG_ DAS_TR_Obj07_Class m7 : 5|3@1+ (1,0) [0|0] "" Vector__XXX
 SG_ DAS_TR_Obj07_Dx m7 : 8|10@1+ (0.15625,0) [0|0] "m" Vector__XXX
 SG_ DAS_TR_Obj07_Dy m7 : 18|6@1+ (0.5,-15.5) [0|0] "m" Vector__XXX
 SG_ DAS_TR_Obj07_Vx m7 : 24|8@1+ (0.5,-63.5) [0|0] "m/s" Vector__XXX
 SG_ DAS_TR_Obj07_RCS m7 : 32|8@1+ (0.25,-14) [0|0] "dB" Vector__XXX
 SG_ DAS_TR_Obj07_Length m7 : 40|6@1+ (0.125,0) [0|0] "m" Vector__XXX
 SG_ DAS_TR_Obj07_MovingState m7 : 46|2@1+ (1,0) [0|0] "" Vector__XXX
 SG_ DAS_TR_Obj07_Dz m7 : 48|6@1+ (0.25,-5) [0|0] "m" Vector__XXX
 SG_ DAS_TR_Obj07_Exist m7 : 56|5@1+ (3.125,0) [0|0] "%" Vector__XXX
 SG_ DAS_TR_Obj08_Class m8 : 5|3@1+ (1,0) [0|0] "" Vector__XXX
 SG_ DAS_TR_Obj08_Dx m8 : 8|10@1+ (0.15625,0) [0|0] "m" Vector__XXX
 SG_ DAS_TR_Obj08_Dy m8 : 18|6@1+ (0.5,-15.5) [0|0] "m" Vector__XXX
 SG_ DAS_TR_Obj08_Vx m8 : 24|8@1+ (0.5,-63.5) [0|0] "m/s" Vector__XXX
 SG_ DAS_TR_Obj08_RCS m8 : 32|8@1+ (0.25,-14) [0|0] "dB" Vector__XXX
 SG_ DAS_TR_Obj08_Length m8 : 40|6@1+ (0.125,0) [0|0] "m" Vector__XXX
 SG_ DAS_TR_Obj08_MovingState m8 : 46|2@1+ (1,0) [0|0] "" Vector__XXX
 SG_ DAS_TR_Obj08_Dz m8 : 48|6@1+ (0.25,-5) [0|0] "m" Vector__XXX
 SG_ DAS_TR_Obj08_Exist m8 : 56|5@1+ (3.125,0) [0|0] "%" Vector__XXX
 SG_ DAS_TR_Obj09_Class m9 : 5|3@1+ (1,0) [0|0] "" Vector__XXX
 SG_ DAS_TR_Obj09_Dx m9 : 8|10@1+ (0.15625,0) [0|0] "m" Vector__XXX
 SG_ DAS_TR_Obj09_Dy m9 : 18|6@1+ (0.5,-15.5) [0|0] "m" Vector__XXX
 SG_ DAS_TR_Obj09_Vx m9 : 24|8@1+ (0.5,-63.5) [0|0] "m/s" Vector__XXX
 SG_ DAS_TR_Obj09_RCS m9 : 32|8@1+ (0.25,-14) [0|0] "dB" Vector__XXX
 SG_ DAS_TR_Obj09_Length m9 : 40|6@1+ (0.125,0) [0|0] "m" Vector__XXX
 SG_ DAS_TR_Obj09_MovingState m9 : 46|2@1+ (1,0) [0|0] "" Vector__XXX
 SG_ DAS_TR_Obj09_Dz m9 : 48|6@1+ (0.25,-5) [0|0] "m" Vector__XXX
 SG_ DAS_TR_Obj09_Exist m9 : 56|5@1+ (3.125,0) [0|0] "%" Vector__XXX
 SG_ DAS_TR_Obj10_Class m10 : 5|3@1+ (1,0) [0|0] "" Vector__XXX
 SG_ DAS_TR_Obj10_Dx m10 : 8|10@1+ (0.15625,0) [0|0] "m" Vector__XXX
 SG_ DAS_TR_Obj10_Dy m10 : 18|6@1+ (0.5,-15.5) [0|0] "m" Vector__XXX
 SG_ DAS_TR_Obj10_Vx m10 : 24|8@1+ (0.5,-63.5) [0|0] "m/s" Vector__XXX
 SG_ DAS_TR_Obj10_RCS m10 : 32|8@1+ (0.25,-14) [0|0] "dB" Vector__XXX
 SG_ DAS_TR_Obj10_Length m10 : 40|6@1+ (0.125,0) [0|0] "m" Vector__XXX
 SG_ DAS_TR_Obj10_MovingState m10 : 46|2@1+ (1,0) [0|0] "" Vector__XXX
 SG_ DAS_TR_Obj10_Dz m10 : 48|6@1+ (0.25,-5) [0|0] "m" Vector__XXX
 SG_ DAS_TR_Obj10_Exist m10 : 56|5@1+ (3.125,0) [0|0] "%" Vector__XXX
 SG_ DAS_TR_Obj11_Class m11 : 5|3@1+ (1,0) [0|0] "" Vector__XXX
 SG_ DAS_TR_Obj11_Dx m11 : 8|10@1+ (0.15625,0) [0|0] "m" Vector__XXX
 SG_ DAS_TR_Obj11_Dy m11 : 18|6@1+ (0.5,-15.5) [0|0] "m" Vector__XXX
 SG_ DAS_TR_Obj11_Vx m11 : 24|8@1+ (0.5,-63.5) [0|0] "m/s" Vector__XXX
 SG_ DAS_TR_Obj11_RCS m11 : 32|8@1+ (0.25,-14) [0|0] "dB" Vector__XXX
 SG_ DAS_TR_Obj11_Length m11 : 40|6@1+ (0.125,0) [0|0] "m" Vector__XXX
 SG_ DAS_TR_Obj11_MovingState m11 : 46|2@1+ (1,0) [0|0] "" Vector__XXX
 SG_ DAS_TR_Obj11_Dz m11 : 48|6@1+ (0.25,-5) [0|0] "m" Vector__XXX
 SG_ DAS_TR_Obj11_Exist m11 : 56|5@1+ (3.125,0) [0|0] "%" Vector__XXX
 SG_ DAS_TR_Obj12_Class m12 : 5|3@1+ (1,0) [0|0] "" Vector__XXX
 SG_ DAS_TR_Obj12_Dx m12 : 8|10@1+ (0.15625,0) [0|0] "m" Vector__XXX
 SG_ DAS_TR_Obj12_Dy m12 : 18|6@1+ (0.5,-15.5) [0|0] "m" Vector__XXX
 SG_ DAS_TR_Obj12_Vx m12 : 24|8@1+ (0.5,-63.5) [0|0] "m/s" Vector__XXX
 SG_ DAS_TR_Obj12_RCS m12 : 32|8@1+ (0.25,-14) [0|0] "dB" Vector__XXX
 SG_ DAS_TR_Obj12_Length m12 : 40|6@1+ (0.125,0) [0|0] "m" Vector__XXX
 SG_ DAS_TR_Obj12_MovingState m12 : 46|2@1+ (1,0) [0|0] "" Vector__XXX
 SG_ DAS_TR_Obj12_Dz m12 : 48|6@1+ (0.25,-5) [0|0] "m" Vector__XXX
 SG_ DAS_TR_Obj12_Exist m12 : 56|5@1+ (3.125,0) [0|0] "%" Vector__XXX
 SG_ DAS_TR_Obj13_Class m13 : 5|3@1+ (1,0) [0|0] "" Vector__XXX
 SG_ DAS_TR_Obj13_Dx m13 : 8|10@1+ (0.15625,0) [0|0] "m" Vector__XXX
 SG_ DAS_TR_Obj13_Dy m13 : 18|6@1+ (0.5,-15.5) [0|0] "m" Vector__XXX
 SG_ DAS_TR_Obj13_Vx m13 : 24|8@1+ (0.5,-63.5) [0|0] "m/s" Vector__XXX
 SG_ DAS_TR_Obj13_RCS m13 : 32|8@1+ (0.25,-14) [0|0] "dB" Vector__XXX
 SG_ DAS_TR_Obj13_Length m13 : 40|6@1+ (0.125,0) [0|0] "m" Vector__XXX
 SG_ DAS_TR_Obj13_MovingState m13 : 46|2@1+ (1,0) [0|0] "" Vector__XXX
 SG_ DAS_TR_Obj13_Dz m13 : 48|6@1+ (0.25,-5) [0|0] "m" Vector__XXX
 SG_ DAS_TR_Obj13_Exist m13 : 56|5@1+ (3.125,0) [0|0] "%" Vector__XXX
 SG_ DAS_TR_Obj14_Class m14 : 5|3@1+ (1,0) [0|0] "" Vector__XXX
 SG_ DAS_TR_Obj14_Dx m14 : 8|10@1+ (0.15625,0) [0|0] "m" Vector__XXX
 SG_ DAS_TR_Obj14_Dy m14 : 18|6@1+ (0.5,-15.5) [0|0] "m" Vector__XXX
 SG_ DAS_TR_Obj14_Vx m14 : 24|8@1+ (0.5,-63.5) [0|0] "m/s" Vector__XXX
 SG_ DAS_TR_Obj14_RCS m14 : 32|8@1+ (0.25,-14) [0|0] "dB" Vector__XXX
 SG_ DAS_TR_Obj14_Length m14 : 40|6@1+ (0.125,0) [0|0] "m" Vector__XXX
 SG_ DAS_TR_Obj14_MovingState m14 : 46|2@1+ (1,0) [0|0] "" Vector__XXX
 SG_ DAS_TR_Obj14_Dz m14 : 48|6@1+ (0.25,-5) [0|0] "m" Vector__XXX
 SG_ DAS_TR_Obj14_Exist m14 : 56|5@1+ (3.125,0) [0|0] "%" Vector__XXX
 SG_ DAS_TR_Obj15_Class m15 : 5|3@1+ (1,0) [0|0] "" Vector__XXX
 SG_ DAS_TR_Obj15_Dx m15 : 8|10@1+ (0.15625,0) [0|0] "m" Vector__XXX
 SG_ DAS_TR_Obj15_Dy m15 : 18|6@1+ (0.5,-15.5) [0|0] "m" Vector__XXX
 SG_ DAS_TR_Obj15_Vx m15 : 24|8@1+ (0.5,-63.5) [0|0] "m/s" Vector__XXX
 SG_ DAS_TR_Obj15_RCS m15 : 32|8@1+ (0.25,-14) [0|0] "dB" Vector__XXX
 SG_ DAS_TR_Obj15_Length m15 : 40|6@1+ (0.125,0) [0|0] "m" Vector__XXX
 SG_ DAS_TR_Obj15_MovingState m15 : 46|2@1+ (1,0) [0|0] "" Vector__XXX
 SG_ DAS_TR_Obj15_Dz m15 : 48|6@1+ (0.25,-5) [0|0] "m" Vector__XXX
 SG_ DAS_TR_Obj15_Exist m15 : 56|5@1+ (3.125,0) [0|0] "%" Vector__XXX
 SG_ DAS_TR_Obj16_Class m16 : 5|3@1+ (1,0) [0|0] "" Vector__XXX
 SG_ DAS_TR_Obj16_Dx m16 : 8|10@1+ (0.15625,0) [0|0] "m" Vector__XXX
 SG_ DAS_TR_Obj16_Dy m16 : 18|6@1+ (0.5,-15.5) [0|0] "m" Vector__XXX
 SG_ DAS_TR_Obj16_Vx m16 : 24|8@1+ (0.5,-63.5) [0|0] "m/s" Vector__XXX
 SG_ DAS_TR_Obj16_RCS m16 : 32|8@1+ (0.25,-14) [0|0] "dB" Vector__XXX
 SG_ DAS_TR_Obj16_Length m16 : 40|6@1+ (0.125,0) [0|0] "m" Vector__XXX
 SG_ DAS_TR_Obj16_MovingState m16 : 46|2@1+ (1,0) [0|0] "" Vector__XXX
 SG_ DAS_TR_Obj16_Dz m16 : 48|6@1+ (0.25,-5) [0|0] "m" Vector__XXX
 SG_ DAS_TR_Obj16_Exist m16 : 56|5@1+ (3.125,0) [0|0] "%" Vector__XXX
 SG_ DAS_TR_Obj17_Class m17 : 5|3@1+ (1,0) [0|0] "" Vector__XXX
 SG_ DAS_TR_Obj17_Dx m17 : 8|10@1+ (0.15625,0) [0|0] "m" Vector__XXX
 SG_ DAS_TR_Obj17_Dy m17 : 18|6@1+ (0.5,-15.5) [0|0] "m" Vector__XXX
 SG_ DAS_TR_Obj17_Vx m17 : 24|8@1+ (0.5,-63.5) [0|0] "m/s" Vector__XXX
 SG_ DAS_TR_Obj17_RCS m17 : 32|8@1+ (0.25,-14) [0|0] "dB" Vector__XXX
 SG_ DAS_TR_Obj17_Length m17 : 40|6@1+ (0.125,0) [0|0] "m" Vector__XXX
 SG_ DAS_TR_Obj17_MovingState m17 : 46|2@1+ (1,0) [0|0] "" Vector__XXX
 SG_ DAS_TR_Obj17_Dz m17 : 48|6@1+ (0.25,-5) [0|0] "m" Vector__XXX
 SG_ DAS_TR_Obj17_Exist m17 : 56|5@1+ (3.125,0) [0|0] "%" Vector__XXX
 SG_ DAS_TR_Obj18_Class m18 : 5|3@1+ (1,0) [0|0] "" Vector__XXX
 SG_ DAS_TR_Obj18_Dx m18 : 8|10@1+ (0.15625,0) [0|0] "m" Vector__XXX
 SG_ DAS_TR_Obj18_Dy m18 : 18|6@1+ (0.5,-15.5) [0|0] "m" Vector__XXX
 SG_ DAS_TR_Obj18_Vx m18 : 24|8@1+ (0.5,-63.5) [0|0] "m/s" Vector__XXX
 SG_ DAS_TR_Obj18_RCS m18 : 32|8@1+ (0.25,-14) [0|0] "dB" Vector__XXX
 SG_ DAS_TR_Obj18_Length m18 : 40|6@1+ (0.125,0) [0|0] "m" Vector__XXX
 SG_ DAS_TR_Obj18_MovingState m18 : 46|2@1+ (1,0) [0|0] "" Vector__XXX
 SG_ DAS_TR_Obj18_Dz m18 : 48|6@1+ (0.25,-5) [0|0] "m" Vector__XXX
 SG_ DAS_TR_Obj18_Exist m18 : 56|5@1+ (3.125,0) [0|0] "%" Vector__XXX
 SG_ DAS_TR_Obj19_Class m19 : 5|3@1+ (1,0) [0|0] "" Vector__XXX
 SG_ DAS_TR_Obj19_Dx m19 : 8|10@1+ (0.15625,0) [0|0] "m" Vector__XXX
 SG_ DAS_TR_Obj19_Dy m19 : 18|6@1+ (0.5,-15.5) [0|0] "m" Vector__XXX
 SG_ DAS_TR_Obj19_Vx m19 : 24|8@1+ (0.5,-63.5) [0|0] "m/s" Vector__XXX
 SG_ DAS_TR_Obj19_RCS m19 : 32|8@1+ (0.25,-14) [0|0] "dB" Vector__XXX
 SG_ DAS_TR_Obj19_Length m19 : 40|6@1+ (0.125,0) [0|0] "m" Vector__XXX
 SG_ DAS_TR_Obj19_MovingState m19 : 46|2@1+ (1,0) [0|0] "" Vector__XXX
 SG_ DAS_TR_Obj19_Dz m19 : 48|6@1+ (0.25,-5) [0|0] "m" Vector__XXX
 SG_ DAS_TR_Obj19_Exist m19 : 56|5@1+ (3.125,0) [0|0] "%" Vector__XXX
 SG_ DAS_TR_Obj20_Class m20 : 5|3@1+ (1,0) [0|0] "" Vector__XXX
 SG_ DAS_TR_Obj20_Dx m20 : 8|10@1+ (0.15625,0) [0|0] "m" Vector__XXX
 SG_ DAS_TR_Obj20_Dy m20 : 18|6@1+ (0.5,-15.5) [0|0] "m" Vector__XXX
 SG_ DAS_TR_Obj20_Vx m20 : 24|8@1+ (0.5,-63.5) [0|0] "m/s" Vector__XXX
 SG_ DAS_TR_Obj20_RCS m20 : 32|8@1+ (0.25,-14) [0|0] "dB" Vector__XXX
 SG_ DAS_TR_Obj20_Length m20 : 40|6@1+ (0.125,0) [0|0] "m" Vector__XXX
 SG_ DAS_TR_Obj20_MovingState m20 : 46|2@1+ (1,0) [0|0] "" Vector__XXX
 SG_ DAS_TR_Obj20_Dz m20 : 48|6@1+ (0.25,-5) [0|0] "m" Vector__XXX
 SG_ DAS_TR_Obj20_Exist m20 : 56|5@1+ (3.125,0) [0|0] "%" Vector__XXX
 SG_ DAS_TR_Obj21_Class m21 : 5|3@1+ (1,0) [0|0] "" Vector__XXX
 SG_ DAS_TR_Obj21_Dx m21 : 8|10@1+ (0.15625,0) [0|0] "m" Vector__XXX
 SG_ DAS_TR_Obj21_Dy m21 : 18|6@1+ (0.5,-15.5) [0|0] "m" Vector__XXX
 SG_ DAS_TR_Obj21_Vx m21 : 24|8@1+ (0.5,-63.5) [0|0] "m/s" Vector__XXX
 SG_ DAS_TR_Obj21_RCS m21 : 32|8@1+ (0.25,-14) [0|0] "dB" Vector__XXX
 SG_ DAS_TR_Obj21_Length m21 : 40|6@1+ (0.125,0) [0|0] "m" Vector__XXX
 SG_ DAS_TR_Obj21_MovingState m21 : 46|2@1+ (1,0) [0|0] "" Vector__XXX
 SG_ DAS_TR_Obj21_Dz m21 : 48|6@1+ (0.25,-5) [0|0] "m" Vector__XXX
 SG_ DAS_TR_Obj21_Exist m21 : 56|5@1+ (3.125,0) [0|0] "%" Vector__XXX
 SG_ DAS_TR_Obj22_Class m22 : 5|3@1+ (1,0) [0|0] "" Vector__XXX
 SG_ DAS_TR_Obj22_Dx m22 : 8|10@1+ (0.15625,0) [0|0] "m" Vector__XXX
 SG_ DAS_TR_Obj22_Dy m22 : 18|6@1+ (0.5,-15.5) [0|0] "m" Vector__XXX
 SG_ DAS_TR_Obj22_Vx m22 : 24|8@1+ (0.5,-63.5) [0|0] "m/s" Vector__XXX
 SG_ DAS_TR_Obj22_RCS m22 : 32|8@1+ (0.25,-14) [0|0] "dB" Vector__XXX
 SG_ DAS_TR_Obj22_Length m22 : 40|6@1+ (0.125,0) [0|0] "m" Vector__XXX
 SG_ DAS_TR_Obj22_MovingState m22 : 46|2@1+ (1,0) [0|0] "" Vector__XXX
 SG_ DAS_TR_Obj22_Dz m22 : 48|6@1+ (0.25,-5) [0|0] "m" Vector__XXX
 SG_ DAS_TR_Obj22_Exist m22 : 56|5@1+ (3.125,0) [0|0] "%" Vector__XXX
 SG_ DAS_TR_Obj23_Class m23 : 5|3@1+ (1,0) [0|0] "" Vector__XXX
 SG_ DAS_TR_Obj23_Dx m23 : 8|10@1+ (0.15625,0) [0|0] "m" Vector__XXX
 SG_ DAS_TR_Obj23_Dy m23 : 18|6@1+ (0.5,-15.5) [0|0] "m" Vector__XXX
 SG_ DAS_TR_Obj23_Vx m23 : 24|8@1+ (0.5,-63.5) [0|0] "m/s" Vector__XXX
 SG_ DAS_TR_Obj23_RCS m23 : 32|8@1+ (0.25,-14) [0|0] "dB" Vector__XXX
 SG_ DAS_TR_Obj23_Length m23 : 40|6@1+ (0.125,0) [0|0] "m" Vector__XXX
 SG_ DAS_TR_Obj23_MovingState m23 : 46|2@1+ (1,0) [0|0] "" Vector__XXX
 SG_ DAS_TR_Obj23_Dz m23 : 48|6@1+ (0.25,-5) [0|0] "m" Vector__XXX
 SG_ DAS_TR_Obj23_Exist m23 : 56|5@1+ (3.125,0) [0|0] "%" Vector__XXX
 SG_ DAS_TR_Obj24_Class m24 : 5|3@1+ (1,0) [0|0] "" Vector__XXX
 SG_ DAS_TR_Obj24_Dx m24 : 8|10@1+ (0.15625,0) [0|0] "m" Vector__XXX
 SG_ DAS_TR_Obj24_Dy m24 : 18|6@1+ (0.5,-15.5) [0|0] "m" Vector__XXX
 SG_ DAS_TR_Obj24_Vx m24 : 24|8@1+ (0.5,-63.5) [0|0] "m/s" Vector__XXX
 SG_ DAS_TR_Obj24_RCS m24 : 32|8@1+ (0.25,-14) [0|0] "dB" Vector__XXX
 SG_ DAS_TR_Obj24_Length m24 : 40|6@1+ (0.125,0) [0|0] "m" Vector__XXX
 SG_ DAS_TR_Obj24_MovingState m24 : 46|2@1+ (1,0) [0|0] "" Vector__XXX
 SG_ DAS_TR_Obj24_Dz m24 : 48|6@1+ (0.25,-5) [0|0] "m" Vector__XXX
 SG_ DAS_TR_Obj24_Exist m24 : 56|5@1+ (3.125,0) [0|0] "%" Vector__XXX
 SG_ DAS_TR_Obj25_Class m25 : 5|3@1+ (1,0) [0|0] "" Vector__XXX
 SG_ DAS_TR_Obj25_Dx m25 : 8|10@1+ (0.15625,0) [0|0] "m" Vector__XXX
 SG_ DAS_TR_Obj25_Dy m25 : 18|6@1+ (0.5,-15.5) [0|0] "m" Vector__XXX
 SG_ DAS_TR_Obj25_Vx m25 : 24|8@1+ (0.5,-63.5) [0|0] "m/s" Vector__XXX
 SG_ DAS_TR_Obj25_RCS m25 : 32|8@1+ (0.25,-14) [0|0] "dB" Vector__XXX
 SG_ DAS_TR_Obj25_Length m25 : 40|6@1+ (0.125,0) [0|0] "m" Vector__XXX
 SG_ DAS_TR_Obj25_MovingState m25 : 46|2@1+ (1,0) [0|0] "" Vector__XXX
 SG_ DAS_TR_Obj25_Dz m25 : 48|6@1+ (0.25,-5) [0|0] "m" Vector__XXX
 SG_ DAS_TR_Obj25_Exist m25 : 56|5@1+ (3.125,0) [0|0] "%" Vector__XXX
 SG_ DAS_TR_Obj26_Class m26 : 5|3@1+ (1,0) [0|0] "" Vector__XXX
 SG_ DAS_TR_Obj26_Dx m26 : 8|10@1+ (0.15625,0) [0|0] "m" Vector__XXX
 SG_ DAS_TR_Obj26_Dy m26 : 18|6@1+ (0.5,-15.5) [0|0] "m" Vector__XXX
 SG_ DAS_TR_Obj26_Vx m26 : 24|8@1+ (0.5,-63.5) [0|0] "m/s" Vector__XXX
 SG_ DAS_TR_Obj26_RCS m26 : 32|8@1+ (0.25,-14) [0|0] "dB" Vector__XXX
 SG_ DAS_TR_Obj26_Length m26 : 40|6@1+ (0.125,0) [0|0] "m" Vector__XXX
 SG_ DAS_TR_Obj26_MovingState m26 : 46|2@1+ (1,0) [0|0] "" Vector__XXX
 SG_ DAS_TR_Obj26_Dz m26 : 48|6@1+ (0.25,-5) [0|0] "m" Vector__XXX
 SG_ DAS_TR_Obj26_Exist m26 : 56|5@1+ (3.125,0) [0|0] "%" Vector__XXX
 SG_ DAS_TR_Obj27_Class m27 : 5|3@1+ (1,0) [0|0] "" Vector__XXX
 SG_ DAS_TR_Obj27_Dx m27 : 8|10@1+ (0.15625,0) [0|0] "m" Vector__XXX
 SG_ DAS_TR_Obj27_Dy m27 : 18|6@1+ (0.5,-15.5) [0|0] "m" Vector__XXX
 SG_ DAS_TR_Obj27_Vx m27 : 24|8@1+ (0.5,-63.5) [0|0] "m/s" Vector__XXX
 SG_ DAS_TR_Obj27_RCS m27 : 32|8@1+ (0.25,-14) [0|0] "dB" Vector__XXX
 SG_ DAS_TR_Obj27_Length m27 : 40|6@1+ (0.125,0) [0|0] "m" Vector__XXX
 SG_ DAS_TR_Obj27_MovingState m27 : 46|2@1+ (1,0) [0|0] "" Vector__XXX
 SG_ DAS_TR_Obj27_Dz m27 : 48|6@1+ (0.25,-5) [0|0] "m" Vector__XXX
 SG_ DAS_TR_Obj27_Exist m27 : 56|5@1+ (3.125,0) [0|0] "%" Vector__XXX
 SG_ DAS_TR_Obj28_Class m28 : 5|3@1+ (1,0) [0|0] "" Vector__XXX
 SG_ DAS_TR_Obj28_Dx m28 : 8|10@1+ (0.15625,0) [0|0] "m" Vector__XXX
 SG_ DAS_TR_Obj28_Dy m28 : 18|6@1+ (0.5,-15.5) [0|0] "m" Vector__XXX
 SG_ DAS_TR_Obj28_Vx m28 : 24|8@1+ (0.5,-63.5) [0|0] "m/s" Vector__XXX
 SG_ DAS_TR_Obj28_RCS m28 : 32|8@1+ (0.25,-14) [0|0] "dB" Vector__XXX
 SG_ DAS_TR_Obj28_Length m28 : 40|6@1+ (0.125,0) [0|0] "m" Vector__XXX
 SG_ DAS_TR_Obj28_MovingState m28 : 46|2@1+ (1,0) [0|0] "" Vector__XXX
 SG_ DAS_TR_Obj28_Dz m28 : 48|6@1+ (0.25,-5) [0|0] "m" Vector__XXX
 SG_ DAS_TR_Obj28_Exist m28 : 56|5@1+ (3.125,0) [0|0] "%" Vector__XXX
 SG_ DAS_TR_Obj29_Class m29 : 5|3@1+ (1,0) [0|0] "" Vector__XXX
 SG_ DAS_TR_Obj29_Dx m29 : 8|10@1+ (0.15625,0) [0|0] "m" Vector__XXX
 SG_ DAS_TR_Obj29_Dy m29 : 18|6@1+ (0.5,-15.5) [0|0] "m" Vector__XXX
 SG_ DAS_TR_Obj29_Vx m29 : 24|8@1+ (0.5,-63.5) [0|0] "m/s" Vector__XXX
 SG_ DAS_TR_Obj29_RCS m29 : 32|8@1+ (0.25,-14) [0|0] "dB" Vector__XXX
 SG_ DAS_TR_Obj29_Length m29 : 40|6@1+ (0.125,0) [0|0] "m" Vector__XXX
 SG_ DAS_TR_Obj29_MovingState m29 : 46|2@1+ (1,0) [0|0] "" Vector__XXX
 SG_ DAS_TR_Obj29_Dz m29 : 48|6@1+ (0.25,-5) [0|0] "m" Vector__XXX
 SG_ DAS_TR_Obj29_Exist m29 : 56|5@1+ (3.125,0) [0|0] "%" Vector__XXX
 SG_ DAS_TR_Obj30_Class m30 : 5|3@1+ (1,0) [0|0] "" Vector__XXX
 SG_ DAS_TR_Obj30_Dx m30 : 8|10@1+ (0.15625,0) [0|0] "m" Vector__XXX
 SG_ DAS_TR_Obj30_Dy m30 : 18|6@1+ (0.5,-15.5) [0|0] "m" Vector__XXX
 SG_ DAS_TR_Obj30_Vx m30 : 24|8@1+ (0.5,-63.5) [0|0] "m/s" Vector__XXX
 SG_ DAS_TR_Obj30_RCS m30 : 32|8@1+ (0.25,-14) [0|0] "dB" Vector__XXX
 SG_ DAS_TR_Obj30_Length m30 : 40|6@1+ (0.125,0) [0|0] "m" Vector__XXX
 SG_ DAS_TR_Obj30_MovingState m30 : 46|2@1+ (1,0) [0|0] "" Vector__XXX
 SG_ DAS_TR_Obj30_Dz m30 : 48|6@1+ (0.25,-5) [0|0] "m" Vector__XXX
 SG_ DAS_TR_Obj30_Exist m30 : 56|5@1+ (3.125,0) [0|0] "%" Vector__XXX
 SG_ DAS_TR_Obj31_Class m31 : 5|3@1+ (1,0) [0|0] "" Vector__XXX
 SG_ DAS_TR_Obj31_Dx m31 : 8|10@1+ (0.15625,0) [0|0] "m" Vector__XXX
 SG_ DAS_TR_Obj31_Dy m31 : 18|6@1+ (0.5,-15.5) [0|0] "m" Vector__XXX
 SG_ DAS_TR_Obj31_Vx m31 : 24|8@1+ (0.5,-63.5) [0|0] "m/s" Vector__XXX
 SG_ DAS_TR_Obj31_RCS m31 : 32|8@1+ (0.25,-14) [0|0] "dB" Vector__XXX
 SG_ DAS_TR_Obj31_Length m31 : 40|6@1+ (0.125,0) [0|0] "m" Vector__XXX
 SG_ DAS_TR_Obj31_MovingState m31 : 46|2@1+ (1,0) [0|0] "" Vector__XXX
 SG_ DAS_TR_Obj31_Dz m31 : 48|6@1+ (0.25,-5) [0|0] "m" Vector__XXX
 SG_ DAS_TR_Obj31_Exist m31 : 56|5@1+ (3.125,0) [0|0] "%" Vector__XXX

BO_ 1550 ID60E_UDS_cpRequest: 8 VEH
 SG_ UDS_cpRequestData: 0|54@0+ (1024,0) [0|0] "" X

BO_ 1551 ID60F_UDS_thcRequest: 8 VEH
 SG_ UDS_thcRequestData_H: 0|32@0+ (1,0) [0|0] "" X
 SG_ UDS_thcRequestData_L: 32|32@0+ (1,0) [0|0] "" X

BO_ 1552 ID610_UDS_hvpRequest: 8 VEH
 SG_ UDS_hvpRequestData: 0|54@0+ (1024,0) [0|0] "" X

BO_ 1553 ID611_HVP_udsResponse: 8 VEH
 SG_ HVP_udsResponseData: 0|54@0+ (1024,0) [0|0] "" X

BO_ 1554 ID612_BMS_udsResponse: 8 VEH
 SG_ BMS_udsResponseData: 0|54@0+ (1024,0) [0|0] "" X
 SG_ UDS_infoMux M : 0|6@1+ (1,0) [0|255] "" Vector__XXX
 SG_ UDS_partNumChar01 m16 : 40|8@1+ (1,0) [0|0] "" Vector__XXX
 SG_ UDS_partNumChar02 m16 : 48|8@1+ (1,0) [0|0] "" Vector__XXX
 SG_ UDS_partNumChar03 m16 : 56|8@1+ (1,0) [0|0] "" Vector__XXX
 SG_ UDS_partNumChar04 m33 : 8|8@1+ (1,0) [0|0] "" Vector__XXX
 SG_ UDS_partNumChar05 m33 : 16|8@1+ (1,0) [0|0] "" Vector__XXX
 SG_ UDS_partNumChar06 m33 : 24|8@1+ (1,0) [0|0] "" Vector__XXX
 SG_ UDS_partNumChar07 m33 : 32|8@1+ (1,0) [0|0] "" Vector__XXX
 SG_ UDS_partNumChar08 m33 : 40|8@1+ (1,0) [0|0] "" Vector__XXX
 SG_ UDS_partNumChar09 m33 : 48|8@1+ (1,0) [0|0] "" Vector__XXX
 SG_ UDS_partNumChar10 m33 : 56|8@1+ (1,0) [0|0] "" Vector__XXX
 SG_ UDS_partNumChar11 m34 : 8|8@1+ (1,0) [0|0] "" Vector__XXX
 SG_ UDS_partNumChar12 m34 : 16|8@1+ (1,0) [0|0] "" Vector__XXX
 SG_ UDS_serialNumChar01 m16 : 40|8@1+ (1,0) [0|0] "" Vector__XXX
 SG_ UDS_serialNumChar02 m16 : 48|8@1+ (1,0) [0|0] "" Vector__XXX
 SG_ UDS_serialNumChar03 m16 : 56|8@1+ (1,0) [0|0] "" Vector__XXX
 SG_ UDS_serialNumChar04 m33 : 8|8@1+ (1,0) [0|0] "" Vector__XXX
 SG_ UDS_serialNumChar05 m33 : 16|8@1+ (1,0) [0|0] "" Vector__XXX
 SG_ UDS_serialNumChar06 m33 : 24|8@1+ (1,0) [0|0] "" Vector__XXX
 SG_ UDS_serialNumChar07 m33 : 32|8@1+ (1,0) [0|0] "" Vector__XXX
 SG_ UDS_serialNumChar08 m33 : 40|8@1+ (1,0) [0|0] "" Vector__XXX
 SG_ UDS_serialNumChar09 m33 : 48|8@1+ (1,0) [0|0] "" Vector__XXX
 SG_ UDS_serialNumChar10 m33 : 56|8@1+ (1,0) [0|0] "" Vector__XXX
 SG_ UDS_serialNumChar11 m34 : 8|8@1+ (1,0) [0|0] "" Vector__XXX
 SG_ UDS_serialNumChar12 m34 : 16|8@1+ (1,0) [0|0] "" Vector__XXX
 SG_ UDS_serialNumChar13 m34 : 24|8@1+ (1,0) [0|0] "" Vector__XXX
 SG_ UDS_serialNumChar14 m34 : 32|8@1+ (1,0) [0|0] "" Vector__XXX

BO_ 1555 ID613_CMP_udsResponse: 8 VEH
 SG_ CMP_udsResponseData: 0|54@0+ (1024,0) [0|0] "" X

BO_ 1556 ID614_PM_udsResponse: 8 VEH
 SG_ PM_udsResponseData: 0|54@0+ (1024,0) [0|0] "" X

BO_ 1557 ID615_DIS_udsResponse: 8 VEH
 SG_ DIS_udsResponseData: 0|54@0+ (1024,0) [0|0] "" X

BO_ 1558 ID616_DI_udsResponse: 8 VEH
 SG_ DI_udsResponseData: 0|54@0+ (1024,0) [0|0] "" X

BO_ 1566 ID61E_CP_udsResponse: 8 VEH
 SG_ CP_udsResponseData: 0|54@0+ (1024,0) [0|0] "" X

BO_ 1570 ID622_UDS_vcleftRequest: 8 VEH
 SG_ UDS_vcleftRequestData_H: 0|32@0+ (1,0) [0|0] "" X
 SG_ UDS_vcleftRequestData_L: 32|32@0+ (1,0) [0|0] "" X

BO_ 1571 ID623_VCLEFT_udsResponse: 8 VEH
 SG_ VCLEFT_udsResponseData_H: 0|32@0+ (1,0) [0|0] "" X
 SG_ VCLEFT_udsResponseData_L: 32|32@0+ (1,0) [0|0] "" X

BO_ 1572 ID624_UDS_epblRequest: 8 VEH
 SG_ UDS_epblRequestData_H: 0|32@0+ (1,0) [0|0] "" X
 SG_ UDS_epblRequestData_L: 32|32@0+ (1,0) [0|0] "" X

BO_ 1573 ID625_EPBL_udsResponse: 8 VEH
 SG_ EPBL_udsResponseData_H: 0|32@0+ (1,0) [0|0] "" X
 SG_ EPBL_udsResponseData_L: 32|32@0+ (1,0) [0|0] "" X

BO_ 1574 ID626_UDS_epbrRequest: 8 VEH
 SG_ UDS_epbrRequestData_H: 0|32@0+ (1,0) [0|0] "" X
 SG_ UDS_epbrRequestData_L: 32|32@0+ (1,0) [0|0] "" X

BO_ 1575 ID627_EPBR_udsResponse: 8 VEH
 SG_ EPBR_udsResponseData_H: 0|32@0+ (1,0) [0|0] "" X
 SG_ EPBR_udsResponseData_L: 32|32@0+ (1,0) [0|0] "" X

BO_ 1576 ID628_UDS_pcsRequest: 8 VEH
 SG_ UDS_pcsRequestData: 0|54@0+ (1024,0) [0|0] "" X

BO_ 1577 ID629_PCS_udsResponse: 8 VEH
 SG_ PCS_udsResponseData: 0|54@0+ (1024,0) [0|0] "" X

BO_ 1579 ID62B_UDS_ccRequest: 8 VEH
 SG_ UDS_ccRequestData: 0|54@0+ (1024,0) [0|0] "" X

BO_ 1584 ID630_UDS_epas3pRequest: 8 VEH
 SG_ UDS_epas3pRequestData: 0|54@0+ (1024,0) [0|0] "" X

BO_ 1592 ID638_EPAS3P_udsResponseCH: 8 VEH
 SG_ EPAS3P_udsResponseDataCH: 0|54@0+ (1024,0) [0|0] "" X

BO_ 1601 ID641_UDS_rcmRequest: 8 VEH
 SG_ UDS_rcmRequestData: 0|54@0+ (1024,0) [0|0] "" X

BO_ 1603 ID643_UDS_ocs1pRequest: 8 VEH
 SG_ UDS_ocs1pRequestData: 0|54@0+ (1024,0) [0|0] "" X

BO_ 1604 ID644_UDS_pmsRequest: 8 VEH
 SG_ UDS_pmsRequestData: 0|54@0+ (1024,0) [0|0] "" X

BO_ 1605 ID645_UDS_espRequest: 8 VEH
 SG_ UDS_espRequestData: 0|54@0+ (1024,0) [0|0] "" X

BO_ 1609 ID649_UDS_dasRequest: 8 VEH
 SG_ UDS_dasRequestData: 0|54@0+ (1024,0) [0|0] "" X

BO_ 1611 ID64B_UDS_tasRequest: 8 VEH
 SG_ UDS_tasRequestData: 0|54@0+ (1024,0) [0|0] "" X

BO_ 1613 ID64D_UDS_ibstRequest: 8 VEH
 SG_ UDS_ibstRequestData: 0|54@0+ (1024,0) [0|0] "" X

BO_ 1614 ID64E_UDS_parkRequest: 8 VEH
 SG_ UDS_parkRequestData: 0|54@0+ (1024,0) [0|0] "" X

BO_ 1615 ID64F_UDS_tpmsRequest: 8 VEH
 SG_ UDS_tpmsRequestData: 0|54@0+ (1024,0) [0|0] "" X

BO_ 1617 ID651_RCM_udsResponse: 8 VEH
 SG_ RCM_udsResponseData: 0|54@0+ (1024,0) [0|0] "" X

BO_ 1619 ID653_OCS1P_udsResponse: 8 VEH
 SG_ OCS1P_udsResponseData: 10|54@1+ (1024,0) [0|0] "" X

BO_ 1620 ID654_PMS_udsResponse: 8 VEH
 SG_ PMS_udsResponseData: 0|54@0+ (1024,0) [0|0] "" X

BO_ 1621 ID655_ESP_udsResponse: 8 VEH
 SG_ ESP_udsResponseData: 0|54@0+ (1024,0) [0|0] "" X

BO_ 1622 DI_info: 8 VEH
 SG_ DI_infoIndex M : 0|8@1+ (1,0) [0|0] "" Vector__XXX
 SG_ DI_buildType m10 : 8|3@1+ (1,0) [0|0] "" Vector__XXX
 SG_ DI_buildConfigurationId m10 : 16|16@1+ (1,0) [0|0] "" Vector__XXX
 SG_ DI_hardwareId m10 : 32|8@1+ (1,0) [0|0] "" Vector__XXX
 SG_ DI_componentId m10 : 48|16@1+ (1,0) [0|0] "" Vector__XXX
 SG_ DI_pcbaId m11 : 16|8@1+ (1,0) [0|0] "" Vector__XXX
 SG_ DI_assemblyId m11 : 24|8@1+ (1,0) [0|0] "" Vector__XXX
 SG_ DI_usageId m11 : 32|16@1+ (1,0) [0|0] "" Vector__XXX
 SG_ DI_subUsageId m11 : 48|16@1+ (1,0) [0|0] "" Vector__XXX
 SG_ DI_applicationSvnRevision m12 : 8|24@1+ (1,0) [0|0] "" Vector__XXX
 SG_ DI_applicationSvnUrlHash m12 : 32|32@1+ (1,0) [0|0] "" Vector__XXX
 SG_ DI_applicationCrc m13 : 32|32@1+ (1,0) [0|0] "" Vector__XXX
 SG_ DI_bootloaderSvnRevision m14 : 8|24@1+ (1,0) [0|0] "" Vector__XXX
 SG_ DI_bootloaderSvnUrlHash m14 : 32|32@1+ (1,0) [0|0] "" Vector__XXX
 SG_ DI_oilPumpBuildType m16 : 8|3@1+ (1,0) [0|0] "" Vector__XXX
 SG_ DI_oilPumpAppCrc m16 : 16|32@1+ (1,0) [0|0] "" Vector__XXX
 SG_ DI_appGitHash m17 : 10|54@1+ (4,0) [0|0] "" Vector__XXX
 SG_ DI_bootGitHash m18 : 10|54@1+ (4,0) [0|0] "" Vector__XXX
 SG_ DI_platformTyp m19 : 8|8@1+ (1,0) [0|0] "" Vector__XXX
 SG_ DI_infoBootLdUdsProtocolVersion m20 : 8|8@1+ (1,0) [0|0] "" Vector__XXX
 SG_ DI_bootloaderCrc m20 : 32|32@1+ (1,0) [0|0] "" Vector__XXX
 SG_ DI_subcomponentGitHash m31 : 10|54@1+ (4,0) [0|0] "" Vector__XXX

BO_ 1625 ID659_DAS_udsResponse: 8 VEH
 SG_ DAS_udsResponseData: 0|54@0+ (1024,0) [0|0] "" X

BO_ 1627 ID65B_TAS_udsResponse: 8 VEH
 SG_ TAS_udsResponseData: 0|54@0+ (1024,0) [0|0] "" X

BO_ 1629 ID65D_IBST_udsResponse: 8 VEH
 SG_ IBST_udsResponseData: 0|54@0+ (1024,0) [0|0] "" X

BO_ 1630 ID65E_PARK_udsResponse: 8 VEH
 SG_ PARK_udsResponseData: 10|54@1+ (1024,0) [0|0] "" X

BO_ 1631 ID65F_TPMS_udsResponse: 8 VEH
 SG_ TPMS_udsResponseData: 0|54@0+ (1024,0) [0|0] "" X

BO_ 1641 ID669_UDS_KOSTIAsccmRequest: 8 VEH
 SG_ UDS_KOSTIAsccmRequestData: 0|54@0+ (1024,0) [0|0] "" X

BO_ 1649 ID671_UDS_radcRequest: 8 VEH
 SG_ UDS_radcRequestData: 0|54@0+ (1024,0) [0|0] "" X

BO_ 1664 ID680_UDS_sccmRequest: 8 VEH
 SG_ UDS_sccmRequestData: 0|54@0+ (1024,0) [0|0] "" X

BO_ 1665 ID681_RADC_udsResponse: 8 VEH
 SG_ RADC_udsResponseData: 0|54@0+ (1024,0) [0|0] "" X

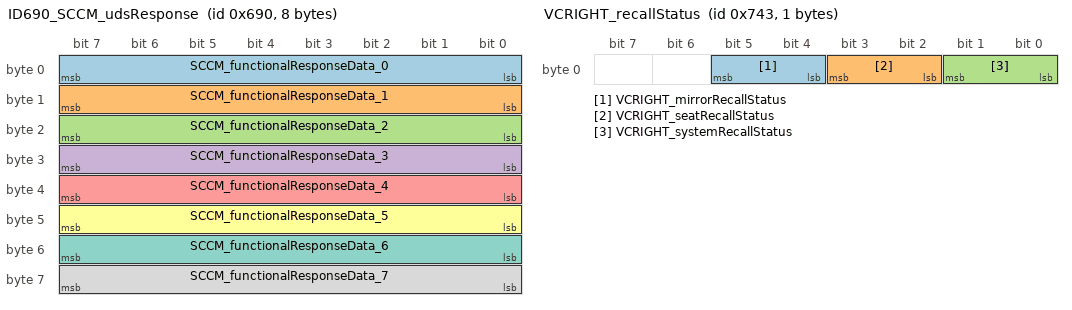
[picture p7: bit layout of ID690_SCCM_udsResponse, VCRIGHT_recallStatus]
BO_ 1680 ID690_SCCM_udsResponse: 8 VEH
 SG_ SCCM_functionalResponseData_0: 0|8@1+ (1,0) [0|0] "" X
 SG_ SCCM_functionalResponseData_1: 8|8@1+ (1,0) [0|0] "" X
 SG_ SCCM_functionalResponseData_2: 16|8@1+ (1,0) [0|0] "" X
 SG_ SCCM_functionalResponseData_3: 24|8@1+ (1,0) [0|0] "" X
 SG_ SCCM_functionalResponseData_4: 32|8@1+ (1,0) [0|0] "" X
 SG_ SCCM_functionalResponseData_5: 40|8@1+ (1,0) [0|0] "" X
 SG_ SCCM_functionalResponseData_6: 48|8@1+ (1,0) [0|0] "" X
 SG_ SCCM_functionalResponseData_7: 56|8@1+ (1,0) [0|0] "" X

BO_ 1734 ID6C6_UDS_ptcRequest: 8 VEH
 SG_ UDS_ptcRequestData: 0|54@0+ (1024,0) [0|0] "" X

BO_ 1748 PMS_info: 8 VEH
 SG_ PMS_infoIndex M : 0|8@1+ (1,0) [0|0] "" Vector__XXX
 SG_ PMS_buildType m10 : 8|8@1+ (1,0) [0|0] "" Vector__XXX
 SG_ PMS_buildConfigurationId m10 : 16|16@1+ (1,0) [0|0] "" Vector__XXX
 SG_ PMS_hardwareId m10 : 32|8@1+ (1,0) [0|0] "" Vector__XXX
 SG_ PMS_componentId m10 : 48|16@1+ (1,0) [0|0] "" Vector__XXX
 SG_ PMS_pcbaId m11 : 16|8@1+ (1,0) [0|0] "" Vector__XXX
 SG_ PMS_assemblyId m11 : 24|8@1+ (1,0) [0|0] "" Vector__XXX
 SG_ PMS_usageId m11 : 32|16@1+ (1,0) [0|0] "" Vector__XXX
 SG_ PMS_subUsageId m11 : 48|16@1+ (1,0) [0|0] "" Vector__XXX
 SG_ PMS_applicationCrc m13 : 32|32@1+ (1,0) [0|0] "" Vector__XXX
 SG_ PMS_bootloaderSvnRevision m14 : 8|24@1+ (1,0) [0|0] "" Vector__XXX
 SG_ PMS_bootloaderSvnUrlHash m14 : 32|32@1+ (1,0) [0|0] "" Vector__XXX
 SG_ PMS_appGitHash m17 : 10|54@1+ (4,0) [0|0] "" Vector__XXX
 SG_ PMS_bootGitHash m18 : 10|54@1+ (4,0) [0|0] "" Vector__XXX
 SG_ PMS_platformTyp m19 : 8|8@1+ (1,0) [0|0] "" Vector__XXX
 SG_ PMS_udsProtocolVersion m20 : 8|8@1+ (1,0) [0|0] "" Vector__XXX
 SG_ PMS_bootloaderCrc m20 : 32|32@1+ (1,0) [0|0] "" Vector__XXX

BO_ 1750 ID6D6_PTC_udsResponse: 8 VEH
 SG_ PTC_udsResponseData: 0|54@0+ (1024,0) [0|0] "" X

BO_ 1795 VCRIGHT_debugThermal10Hz: 8 VEH
 SG_ VCRIGHT_debugThermal10HzIndex M : 0|3@1+ (1,0) [0|0] "" Vector__XXX
 SG_ VCRIGHT_wattsDemandEvapFeedback m0 : 3|9@1- (20,0) [0|0] "W" Vector__XXX
 SG_ VCRIGHT_wattsDemandEvapFeedfwd m0 : 12|9@1+ (20,0) [0|0] "W" Vector__XXX
 SG_ VCRIGHT_wattsHeaterLeftFeedback m0 : 21|9@1- (20,0) [0|0] "W" Vector__XXX
 SG_ VCRIGHT_wattsHeaterLeftFeedfwd m0 : 30|9@1+ (20,0) [0|0] "W" Vector__XXX
 SG_ VCRIGHT_wattsHeaterRightFeedback m0 : 39|9@1- (20,0) [0|0] "W" Vector__XXX
 SG_ VCRIGHT_wattsHeaterRightFeedfwd m0 : 48|9@1+ (20,0) [0|0] "W" Vector__XXX
 SG_ VCRIGHT_tempEvapAdjustmentLeft m1 : 8|7@1+ (0.1,0) [0|0] "degC" Vector__XXX
 SG_ VCRIGHT_tempEvapAdjustmentRight m1 : 16|7@1+ (0.1,0) [0|0] "degC" Vector__XXX
 SG_ VCRIGHT_hvacPanelFloorSplitRow1 m2 : 8|8@1+ (0.4,0) [0|0] "%" Vector__XXX
 SG_ VCRIGHT_hvacDefrostPercent m2 : 16|8@1+ (0.4,0) [0|0] "%" Vector__XXX
 SG_ VCRIGHT_hvacRow2Percent m2 : 24|8@1+ (0.4,0) [0|0] "%" Vector__XXX
 SG_ VCRIGHT_hvacPanelFloorSplitRow2 m2 : 32|8@1+ (0.4,0) [0|0] "%" Vector__XXX
 SG_ VCRIGHT_cabinTempThs m3 : 8|8@1+ (0.5,-40) [0|0] "degC" Vector__XXX
 SG_ VCRIGHT_cabinTempThsBracket m3 : 16|8@1+ (0.5,-40) [0|0] "degC" Vector__XXX
 SG_ VCRIGHT_cabinTempProbe m3 : 24|8@1+ (0.5,-40) [0|0] "degC" Vector__XXX
 SG_ VCRIGHT_setTempAdjustmentLeft m3 : 32|7@1+ (0.1,0) [0|0] "degC" Vector__XXX
 SG_ VCRIGHT_setTempAdjustmentRight m3 : 40|7@1+ (0.1,0) [0|0] "degC" Vector__XXX
 SG_ VCRIGHT_hvacLHBleedCalibrated m4 : 3|1@1+ (1,0) [0|0] "" Vector__XXX
 SG_ VCRIGHT_hvacActuatorsCalibrated m4 : 4|1@1+ (1,0) [0|0] "" Vector__XXX
 SG_ VCRIGHT_hvacRHBleedCalibrated m4 : 7|1@1+ (1,0) [0|0] "" Vector__XXX
 SG_ VCRIGHT_hvacLHVaneCalibrated m4 : 11|1@1+ (1,0) [0|0] "" Vector__XXX
 SG_ VCRIGHT_hvacRHVaneCalibrated m4 : 15|1@1+ (1,0) [0|0] "" Vector__XXX
 SG_ VCRIGHT_hvacUpperModeCalibrated m4 : 19|1@1+ (1,0) [0|0] "" Vector__XXX
 SG_ VCRIGHT_hvacLowerModeCalibrated m4 : 23|1@1+ (1,0) [0|0] "" Vector__XXX
 SG_ VCRIGHT_hvacIntakeCalibrated m4 : 27|1@1+ (1,0) [0|0] "" Vector__XXX

BO_ 1826 UDS_bmbRequest: 8 VEH
 SG_ UDS_bmbRequestData : 0|54@0+ (1024,0) [0|0] "" X

BO_ 1834 ID72ABMS_serialNumber: 8 VehicleBus
 SG_ BMS_packSerialNumberByte01 m0 : 8|8@1+ (1,0) [0|255] ""  Receiver
 SG_ BMS_packSerialNumberByte02 m0 : 16|8@1+ (1,0) [0|255] ""  Receiver
 SG_ BMS_packSerialNumberByte03 m0 : 24|8@1+ (1,0) [0|255] ""  Receiver
 SG_ BMS_packSerialNumberByte04 m0 : 32|8@1+ (1,0) [0|255] ""  Receiver
 SG_ BMS_packSerialNumberByte05 m0 : 40|8@1+ (1,0) [0|255] ""  Receiver
 SG_ BMS_packSerialNumberByte06 m0 : 48|8@1+ (1,0) [0|255] ""  Receiver
 SG_ BMS_packSerialNumberByte07 m0 : 56|8@1+ (1,0) [0|255] ""  Receiver
 SG_ BMS_packSerialNumberByte08 m1 : 8|8@1+ (1,0) [0|255] ""  Receiver
 SG_ BMS_packSerialNumberByte09 m1 : 16|8@1+ (1,0) [0|255] ""  Receiver
 SG_ BMS_packSerialNumberByte10 m1 : 24|8@1+ (1,0) [0|255] ""  Receiver
 SG_ BMS_packSerialNumberByte11 m1 : 32|8@1+ (1,0) [0|255] ""  Receiver
 SG_ BMS_packSerialNumberByte12 m1 : 40|8@1+ (1,0) [0|255] ""  Receiver
 SG_ BMS_packSerialNumberByte13 m1 : 48|8@1+ (1,0) [0|255] ""  Receiver
 SG_ BMS_packSerialNumberByte14 m1 : 56|8@1+ (1,0) [0|255] ""  Receiver
 SG_ BMS_serialNumberMultiplexer M : 0|1@1+ (1,0) [0|1] ""  Receiver

BO_ 1840 ID730_UDS_epas3sRequest: 8 VEH
 SG_ UDS_epas3sRequestData: 0|54@0+ (1024,0) [0|0] "" X

BO_ 1848 ID738_EPAS3S_udsResponse: 8 VEH
 SG_ EPAS3S_udsResponseData: 0|54@0+ (1024,0) [0|0] "" X

BO_ 1859 VCRIGHT_recallStatus: 1 VEH
 SG_ VCRIGHT_mirrorRecallStatus : 4|2@1+ (1,0) [0|0] "" Vector__XXX
 SG_ VCRIGHT_seatRecallStatus : 2|2@1+ (1,0) [0|0] "" Vector__XXX
 SG_ VCRIGHT_systemRecallStatus : 0|2@1+ (1,0) [0|0] "" Vector__XXX

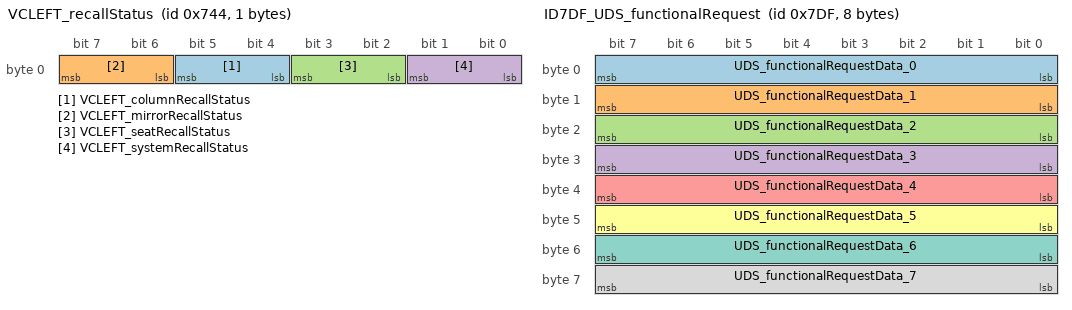
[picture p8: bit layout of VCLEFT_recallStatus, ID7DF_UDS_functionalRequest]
BO_ 1860 VCLEFT_recallStatus: 1 VEH
 SG_ VCLEFT_columnRecallStatus : 4|2@1+ (1,0) [0|0] "" Vector__XXX
 SG_ VCLEFT_mirrorRecallStatus : 6|2@1+ (1,0) [0|0] "" Vector__XXX
 SG_ VCLEFT_seatRecallStatus : 2|2@1+ (1,0) [0|0] "" Vector__XXX
 SG_ VCLEFT_systemRecallStatus : 0|2@1+ (1,0) [0|0] "" Vector__XXX

BO_ 1879 ID757DIF_debug: 8 VehicleBus
 SG_ DIF_debugSelector M : 0|8@1+ (1,0) [0|255] ""  Receiver
 SG_ DIF_brakeSwitchNC m42 : 63|1@1+ (1,0) [0|1] ""  Receiver
 SG_ DIF_brakeSwitchNO m42 : 62|1@1+ (1,0) [0|1] ""  Receiver
 SG_ DIF_busbarTemp m64 : 16|8@1+ (1,-40) [-40|215] "C"  Receiver
 SG_ DIF_controlStack m67 : 40|8@1+ (0.4,0) [0|100] "%"  Receiver
 SG_ DIF_cpu100HzAvg m66 : 32|8@1+ (0.4,0) [0|102] "%"  Receiver
 SG_ DIF_cpu100HzMin m66 : 24|8@1+ (0.4,0) [0|102] "%"  Receiver
 SG_ DIF_cpu10HzAvg m66 : 16|8@1+ (0.4,0) [0|102] "%"  Receiver
 SG_ DIF_cpu10HzMin m66 : 8|8@1+ (0.4,0) [0|102] "%"  Receiver
 SG_ DIF_cpu10msMin m66 : 40|8@1+ (0.4,0) [0|102] "%"  Receiver
 SG_ DIF_cpu1HzAvg m128 : 24|8@1+ (0.4,0) [0|102] "%"  Receiver
 SG_ DIF_cpu1HzMin m128 : 16|8@1+ (0.4,0) [0|102] "%"  Receiver
 SG_ DIF_cpu1kHzAvg m67 : 16|8@1+ (0.4,0) [0|102] "%"  Receiver
 SG_ DIF_cpu1kHzMin m67 : 8|8@1+ (0.4,0) [0|102] "%"  Receiver
 SG_ DIF_cpu20kHzAvg m67 : 32|8@1+ (0.4,0) [0|102] "%"  Receiver
 SG_ DIF_cpu20kHzMin m67 : 24|8@1+ (0.4,0) [0|102] "%"  Receiver
 SG_ DIF_cpuIDWord0 m131 : 16|16@1+ (1,0) [0|65535] ""  Receiver
 SG_ DIF_cpuIDWord1 m132 : 16|16@1+ (1,0) [0|65535] ""  Receiver
 SG_ DIF_cpuIDWord2 m132 : 32|16@1+ (1,0) [0|65535] ""  Receiver
 SG_ DIF_cpuIDWord3 m132 : 48|16@1+ (1,0) [0|65535] ""  Receiver
 SG_ DIF_crc m131 : 32|32@1+ (1,0) [0|4294970000] ""  Receiver
 SG_ DIF_currentLimit m41 : 32|16@1+ (0.1,0) [0|6553.5] "A"  Receiver
 SG_ DIF_dcCableCurrentEst m37 : 16|16@1- (0.1,0) [-3276.8|3276.7] "A"  Receiver
 SG_ DIF_dcCableHeat m47 : 32|16@1+ (0.001,0) [0|65.535] "kA2s"  Receiver
 SG_ DIF_dcCapTemp m64 : 8|8@1+ (1,-40) [-40|215] "C"  Receiver
 SG_ DIF_dcLinkCapTemp m70 : 32|8@1+ (1,-40) [-40|215] "C"  Receiver
 SG_ DIF_decodeHardwareStack m68 : 24|8@1+ (0.4,0) [0|100] "%"  Receiver
 SG_ DIF_driveUnitOdometer m69 : 32|32@1+ (10,0) [0|42949700000] "rev"  Receiver
 SG_ DIF_eepromStack m68 : 32|8@1+ (0.4,0) [0|100] "%"  Receiver
 SG_ DIF_fluxState m42 : 16|4@1+ (1,0) [0|10] ""  Receiver
 SG_ DIF_gainScale m37 : 8|8@1+ (0.01,0) [0|2.55] "scale"  Receiver
 SG_ DIF_gateDriveState m50 : 10|3@1+ (1,0) [0|4] ""  Receiver
 SG_ DIF_gateDriveSupplyState m50 : 8|2@1+ (1,0) [0|3] ""  Receiver
 SG_ DIF_hvDcCableTemp m70 : 40|8@1+ (1,-40) [-40|215] "C"  Receiver
 SG_ DIF_hwFaultCount m69 : 8|4@1+ (1,0) [0|15] ""  Receiver
 SG_ DIF_idleStack m68 : 16|8@1+ (0.4,0) [0|100] "%"  Receiver
 SG_ DIF_immobilizerStack m68 : 56|8@1+ (0.4,0) [0|100] "%"  Receiver
 SG_ DIF_internalAngleFilt m37 : 48|16@1+ (0.0003,0) [0|8] "rad"  Receiver
 SG_ DIF_llrScale m42 : 32|8@1+ (0.015,0) [0|3.825] "scale"  Receiver
 SG_ DIF_llsScale m42 : 24|8@1+ (0.004,0) [0|1.02] "scale"  Receiver
 SG_ DIF_lmScale m36 : 8|8@1+ (0.004,0) [0|1.02] "scale"  Receiver
 SG_ DIF_loadAngle m42 : 40|16@1- (0.0003,0) [-4|4] "rad"  Receiver
 SG_ DIF_loadAngleMargin m37 : 32|16@1- (0.0003,0) [-4|4] "rad"  Receiver
 SG_ DIF_magnetTempEst m47 : 48|8@1+ (1,-40) [-40|180] "C"  Receiver
 SG_ DIF_module10HzStack m66 : 48|8@1+ (0.4,0) [0|100] "%"  Receiver
 SG_ DIF_motorIA m32 : 16|16@1+ (0.1,0) [0|6553.5] "A"  Receiver
 SG_ DIF_motorIAavg m38 : 32|16@1- (0.1,0) [-3276.8|3276.7] "A"  Receiver
 SG_ DIF_motorIB m32 : 32|16@1+ (0.1,0) [0|6553.5] "A"  Receiver
 SG_ DIF_motorIBavg m38 : 48|16@1- (0.1,0) [-3276.8|3276.7] "A"  Receiver
 SG_ DIF_motorIC m32 : 48|16@1+ (0.1,0) [0|6553.5] "A"  Receiver
 SG_ DIF_motorType m128 : 8|6@1+ (1,0) [0|32] ""  Receiver
 SG_ DIF_motorV m34 : 48|16@1+ (2e-05,0) [0|1.3107] "mindex"  Receiver
 SG_ DIF_negDcBusbarTemp m70 : 48|8@1+ (1,-40) [-40|215] "C"  Receiver
 SG_ DIF_offsetA m32 : 8|8@1- (0.1,0) [-12.8|12.7] "A"  Receiver
 SG_ DIF_offsetB m33 : 8|8@1- (0.1,0) [-12.8|12.7] "A"  Receiver
 SG_ DIF_oilPumpMotorSpeed m46 : 8|8@1+ (40,0) [0|10200] "RPM"  Receiver
 SG_ DIF_oilPumpPhaseVoltage m46 : 16|8@1+ (0.1,0) [0|25.4] "V"  Receiver
 SG_ DIF_oilPumpPressureEstimateMax m46 : 24|8@1+ (2,0) [0|500] "kPa"  Receiver
 SG_ DIF_oilPumpPressureExpectedMin m46 : 32|8@1+ (2,0) [0|500] "kPa"  Receiver
 SG_ DIF_pcsTemp m64 : 24|8@1+ (1,-40) [-40|215] "C"  Receiver
 SG_ DIF_peakFlux m36 : 48|16@1+ (0.0001,0) [0|6.5535] "Wb"  Receiver
 SG_ DIF_peakIQref m38 : 16|16@1+ (0.1,0) [0|6553.5] "A"  Receiver
 SG_ DIF_phaseOutBusbarTemp m70 : 8|8@1+ (1,-40) [-40|215] "C"  Receiver
 SG_ DIF_phaseOutBusbarWeldTemp m70 : 16|8@1+ (1,-40) [-40|215] "C"  Receiver
 SG_ DIF_phaseOutLugTemp m70 : 24|8@1+ (1,-40) [-40|215] "C"  Receiver
 SG_ DIF_posDcBusbarTemp m70 : 56|8@1+ (1,-40) [-40|215] "C"  Receiver
 SG_ DIF_powerStageSafeState m50 : 13|2@1+ (1,0) [0|3] ""  Receiver
 SG_ DIF_pwmState m63 : 48|2@1+ (1,0) [0|3] ""  Receiver
 SG_ DIF_pwrSatChargeCurrent m42 : 8|8@1+ (0.4,0) [0|102] "%"  Receiver
 SG_ DIF_pwrSatDischargeCurrent m40 : 8|8@1+ (0.4,0) [0|102] "%"  Receiver
 SG_ DIF_pwrSatMaxBusVoltage m39 : 48|8@1+ (0.4,0) [0|102] "%"  Receiver
 SG_ DIF_pwrSatMaxDischargePower m39 : 16|8@1+ (0.4,0) [0|102] "%"  Receiver
 SG_ DIF_pwrSatMaxRegenPower m39 : 24|8@1+ (0.4,0) [0|102] "%"  Receiver
 SG_ DIF_pwrSatMinBusVoltage m39 : 56|8@1+ (0.4,0) [0|102] "%"  Receiver
 SG_ DIF_resolverClaMIA m48 : 43|1@1+ (1,0) [0|1] ""  Receiver
 SG_ DIF_resolverCommonGain m48 : 32|8@1+ (0.025,0) [0|5] "1"  Receiver
 SG_ DIF_resolverCosFiltered m52 : 32|8@1- (0.01,0) [-1|1] "1"  Receiver
 SG_ DIF_resolverCosRmsSquared m52 : 16|8@1+ (0.005,0) [0|1] "1"  Receiver
 SG_ DIF_resolverErrorRmsSquared m52 : 48|8@1+ (0.005,0) [0|1] "1"  Receiver
 SG_ DIF_resolverNoCarrier m48 : 41|1@1+ (1,0) [0|1] ""  Receiver
 SG_ DIF_resolverNoPhaseLock m48 : 42|1@1+ (1,0) [0|1] ""  Receiver
 SG_ DIF_resolverOffsetCos m48 : 8|8@1+ (0.015,0) [0|3.3] "V"  Receiver
 SG_ DIF_resolverOffsetSin m48 : 16|8@1+ (0.015,0) [0|3.3] "V"  Receiver
 SG_ DIF_resolverPhaseOffset m48 : 24|8@1+ (0.1,7.5) [7.5|32.5] "us"  Receiver
 SG_ DIF_resolverReady m48 : 40|1@1+ (1,0) [0|1] ""  Receiver
 SG_ DIF_resolverSinFiltered m52 : 40|8@1- (0.01,0) [-1|1] "1"  Receiver
 SG_ DIF_resolverSinRmsSquared m52 : 24|8@1+ (0.005,0) [0|1] "1"  Receiver
 SG_ DIF_rotorFlux m47 : 16|16@1+ (0.0001,0) [0|6.5535] "Wb"  Receiver
 SG_ DIF_rotorMaxMagnetTemp m72 : 16|8@1+ (1,-40) [-40|215] "C"  Receiver
 SG_ DIF_rotorOffsetEst m43 : 8|12@1- (0.01,0) [-20|20] "deg"  Receiver
 SG_ DIF_rotorOffsetLearningState m63 : 8|4@1+ (1,0) [0|9] ""  Receiver
 SG_ DIF_rotorOffsetMean m43 : 20|12@1- (0.01,0) [-20|20] "deg"  Receiver
 SG_ DIF_rsScale m34 : 8|8@1+ (0.01,0) [0|2.55] "scale"  Receiver
 SG_ DIF_soptMaxCurrentMagSqrd m49 : 40|16@1+ (100,0) [0|6553500] "A2"  Receiver
 SG_ DIF_soptTimeToOff m49 : 24|11@1+ (0.05,0) [0|100] "ms"  Receiver
 SG_ DIF_soptTimeToTrip m49 : 8|8@1+ (0.05,0) [0|10] "ms"  Receiver
 SG_ DIF_soptTripDelay m49 : 16|8@1+ (0.05,0) [0|10] "ms"  Receiver
 SG_ DIF_ssmState m38 : 8|4@1+ (1,0) [0|8] ""  Receiver
 SG_ DIF_statorEndWindingTemp m72 : 8|8@1+ (1,-40) [-40|215] "C"  Receiver
 SG_ DIF_statorFluxFdb m35 : 32|16@1+ (0.0001,0) [0|6.5535] "Wb"  Receiver
 SG_ DIF_statorFluxRef m35 : 16|16@1+ (0.0001,0) [0|6.5535] "Wb"  Receiver
 SG_ DIF_statorIDfdb m33 : 32|16@1- (0.1,0) [-3276.8|3276.7] "A"  Receiver
 SG_ DIF_statorIDref m33 : 16|16@1- (0.1,0) [-3276.8|3276.7] "A"  Receiver
 SG_ DIF_statorIQfdb m34 : 32|16@1- (0.1,0) [-3276.8|3276.7] "A"  Receiver
 SG_ DIF_statorIQref m34 : 16|16@1- (0.1,0) [-3276.8|3276.7] "A"  Receiver
 SG_ DIF_statorTemp1 m64 : 32|8@1+ (1,-40) [-40|215] "C"  Receiver
 SG_ DIF_statorTemp2 m64 : 40|8@1+ (1,-40) [-40|215] "C"  Receiver
 SG_ DIF_statorVD m36 : 32|16@1- (4e-05,0) [-1.31072|1.31068] "mindex"  Receiver
 SG_ DIF_statorVDFiltered m63 : 16|16@1- (4e-05,0) [-1.31072|1.31068] "mindex"  Receiver
 SG_ DIF_statorVQ m36 : 16|16@1- (4e-05,0) [-1.31072|1.31068] "mindex"  Receiver
 SG_ DIF_statorVQFiltered m63 : 32|16@1- (4e-05,0) [-1.31072|1.31068] "mindex"  Receiver
 SG_ DIF_sysHeatPowerOptimal m50 : 16|8@1+ (0.08,0) [0|20] "kW"  Receiver
 SG_ DIF_systemStack m68 : 8|8@1+ (0.4,0) [0|100] "%"  Receiver
 SG_ DIF_systemTorqueCommand m35 : 48|16@1- (0.035,0) [-1146.88|1146.85] "Nm"  Receiver
 SG_ DIF_tcMaxRequest m40 : 16|8@1+ (5,0) [0|1275] "Nm"  Receiver
 SG_ DIF_tcMinRequest m40 : 24|8@1+ (5,0) [0|1275] "Nm"  Receiver
 SG_ DIF_torquePerAmp m33 : 48|16@1+ (0.0001,0) [0|6.5535] "Nm/A"  Receiver
 SG_ DIF_tqSatMotorCurrent m39 : 40|8@1+ (0.4,0) [0|102] "%"  Receiver
 SG_ DIF_tqSatMotorVoltage m39 : 32|8@1+ (0.4,0) [0|102] "%"  Receiver
 SG_ DIF_tqSatThermal m39 : 8|8@1+ (0.4,0) [0|102] "%"  Receiver
 SG_ DIF_tqSatUiDriveTorque m40 : 32|8@1+ (0.4,0) [0|102] "%"  Receiver
 SG_ DIF_tqSatUiRegenTorque m40 : 40|8@1+ (0.4,0) [0|102] "%"  Receiver
 SG_ DIF_tqScaleDifferential m35 : 8|8@1+ (0.4,0) [0|102] "%"  Receiver
 SG_ DIF_tqScaleMaxMotorSpeed m40 : 48|8@1+ (0.4,0) [0|102] "%"  Receiver
 SG_ DIF_tqScaleShift m40 : 56|8@1+ (0.4,0) [0|102] "%"  Receiver
 SG_ DIF_udsStack m68 : 40|8@1+ (0.4,0) [0|100] "%"  Receiver
 SG_ DIF_usmState m38 : 12|3@1+ (1,0) [0|7] ""  Receiver
 SG_ DIF_veMassInvRaw m41 : 8|12@1+ (1e-07,0.0001) [0.0001|0.0005] "1/kg"  Receiver
 SG_ DIF_veResForce m41 : 20|12@1- (0.0005,0) [-1.024|1.0235] "G"  Receiver
 SG_ DIF_wasteCurrentLimit m41 : 48|16@1+ (0.1,0) [0|6553.5] "A"  Receiver
 SG_ DIF_xcpStack m68 : 48|8@1+ (0.4,0) [0|100] "%"  Receiver

BO_ 1880 DI_dyno: 8 VEH
 SG_ DI_dynoSelector M : 0|8@1+ (1,0) [0|0] "" Vector__XXX
 SG_ DI_Isx m0 : 16|16@1+ (1.5259e-05,0) [0|0] "A" Vector__XXX
 SG_ DI_Isy m0 : 32|16@1+ (1.5259e-05,0) [0|0] "A" Vector__XXX
 SG_ DI_IsMag m0 : 48|16@1- (0.1,0) [0|0] "A" Vector__XXX
 SG_ DI_Vsx m1 : 16|16@1- (4e-05,0) [0|0] "mindex" Vector__XXX
 SG_ DI_Vsy m1 : 32|16@1- (4e-05,0) [0|0] "mindex" Vector__XXX
 SG_ DI_voltageForFlux m1 : 48|16@1+ (0.00762951,0) [0|0] "V" Vector__XXX
 SG_ DI_torqueMotor m2 : 16|13@1- (0.25,0) [0|0] "Nm" Vector__XXX
 SG_ DI_state m2 : 29|3@1+ (1,0) [0|0] "" Vector__XXX
 SG_ DI_motorRPM m2 : 32|16@1- (1,0) [0|0] "RPM" Vector__XXX
 SG_ DI_torqueEstimate m2 : 48|13@1- (0.25,0) [0|0] "Nm" Vector__XXX
 SG_ DI_pedalMinTorque m32 : 8|12@1+ (0.25,-750) [0|0] "Nm" Vector__XXX
 SG_ DI_pedalMaxTorque m32 : 20|12@1+ (0.25,0) [0|0] "Nm" Vector__XXX
 SG_ DI_postPedalMinTorque m32 : 32|12@1+ (0.25,-750) [0|0] "Nm" Vector__XXX
 SG_ DI_postPedalMaxTorque m32 : 44|12@1+ (0.25,0) [0|0] "Nm" Vector__XXX
 SG_ DI_slipEstimate m33 : 8|10@1- (0.02,0) [0|0] "Hz" Vector__XXX
 SG_ DI_mechToElcFactor m64 : 8|4@1- (1,0) [0|0] "" Vector__XXX

BO_ 1885 CP_sensorData: 8 VEH
 SG_ CP_sensorDataSelect M : 0|4@1+ (1,0) [0|12] ""  Receiver
 SG_ CP_UHF_chipState m6 : 4|3@1+ (1,0) [0|7] ""  Receiver
 SG_ CP_UHF_fifoData m6 : 32|8@1+ (1,0) [0|255] ""  Receiver
 SG_ CP_UHF_rssi m6 : 8|8@1+ (1,0) [0|255] ""  Receiver
 SG_ CP_UHF_rxNumBytes m6 : 24|8@1+ (1,0) [0|255] ""  Receiver
 SG_ CP_UHF_rxOverflow m6 : 16|1@1+ (1,0) [0|1] ""  Receiver
 SG_ CP_UHF_selfTestRssi m6 : 40|8@1+ (1,0) [0|255] ""  Receiver
 SG_ CP_backCover2Counts m5 : 32|16@1+ (0.0015259,0) [0|100] "%"  Receiver
 SG_ CP_backCoverCounts m5 : 16|16@1+ (0.0015259,0) [0|100] "%"  Receiver
 SG_ CP_boardTemperature m1 : 32|8@1+ (1.29412,-50) [-50|280] "C"  Receiver
 SG_ CP_doorCountsDebounced m0 : 24|16@1+ (0.0015259,0) [0|100] "%"  Receiver
 SG_ CP_doorCountsFiltered m0 : 8|16@1+ (0.0015259,0) [0|100] "%"  Receiver
 SG_ CP_doorI m2 : 16|12@1+ (0.0025,0) [0|10.2375] "A"  Receiver
 SG_ CP_doorLastRequestMaxI m2 : 28|12@1+ (0.0025,0) [0|10.2375] "A"  Receiver
 SG_ CP_doorPot m2 : 4|12@1+ (0.025,0) [0|100] "%"  Receiver
 SG_ CP_faultLineV m5 : 4|12@1+ (0.00114,0) [0|4.65524] "V"  Receiver
 SG_ CP_inductiveSensor_raw m4 : 4|28@1+ (1,0) [0|268435000] ""  Receiver
 SG_ CP_inlet1HarnessIdState m12 : 4|2@1+ (1,0) [0|2] ""  Receiver
 SG_ CP_inlet1HarnessIdValue m12 : 8|3@1+ (1,0) [0|7] ""  Receiver
 SG_ CP_inlet1HarnessV m12 : 16|14@1+ (0.001,0) [0|13.3] "V"  Receiver
 SG_ CP_inlet2HarnessIdState m12 : 30|2@1+ (1,0) [0|2] ""  Receiver
 SG_ CP_inlet2HarnessIdValue m12 : 32|3@1+ (1,0) [0|7] ""  Receiver
 SG_ CP_inlet2HarnessV m12 : 40|14@1+ (0.001,0) [0|13.3] "V"  Receiver
 SG_ CP_latch2I m3 : 16|12@1+ (0.0025,0) [0|10.2375] "A"  Receiver
 SG_ CP_latchI m3 : 4|12@1+ (0.0025,0) [0|10.2375] "A"  Receiver
 SG_ CP_pilotHighValue m9 : 40|12@1- (0.01,0) [-20.48|20.47] "V"  Receiver
 SG_ CP_pilotHighValue_intervalMax10s m10 : 28|12@1- (0.01,0) [-20.48|20.47] "V"  Receiver
 SG_ CP_pilotHighValue_intervalMin10s m10 : 40|12@1- (0.01,0) [-20.48|20.47] "V"  Receiver
 SG_ CP_pilotLowValue m9 : 28|12@1- (0.01,0) [-20.48|20.47] "V"  Receiver
 SG_ CP_pilotLowValue_intervalMax10s m10 : 4|12@1- (0.01,0) [-20.48|20.47] "V"  Receiver
 SG_ CP_pilotLowValue_intervalMin10s m10 : 16|12@1- (0.01,0) [-20.48|20.47] "V"  Receiver
 SG_ CP_pilotPeriod m9 : 16|12@1+ (1,0) [0|4095] ""  Receiver
 SG_ CP_pilotPulseWidth m9 : 4|12@1+ (1,0) [0|4095] ""  Receiver
 SG_ CP_pinTemperature1 m1 : 8|8@1+ (0.803922,-55) [-55|149.99] "C"  Receiver
 SG_ CP_pinTemperature2 m1 : 16|8@1+ (0.803922,-55) [-55|149.99] "C"  Receiver
 SG_ CP_pinTemperature3 m1 : 24|8@1+ (0.803922,-55) [-55|149.99] "C"  Receiver
 SG_ CP_proxConn1Sense m8 : 56|1@1+ (1,0) [0|1] ""  Receiver
 SG_ CP_proxEn m8 : 57|1@1+ (1,0) [0|1] ""  Receiver
 SG_ CP_proximityV m8 : 8|16@1+ (0.0001,0) [0|6.5535] "V"  Receiver
 SG_ CP_proximityV_GBCC1 m11 : 8|14@1+ (0.001,0) [0|13.3] "V"  Receiver
 SG_ CP_proximityV_GBCC2 m11 : 24|14@1+ (0.001,0) [0|13.3] "V"  Receiver
 SG_ CP_proximityV_intervalMax10s m8 : 40|16@1+ (0.0001,0) [0|6.5535] "V"  Receiver
 SG_ CP_proximityV_intervalMin10s m8 : 24|16@1+ (0.0001,0) [0|6.5535] "V"  Receiver
 SG_ CP_refVoltage m7 : 8|8@1+ (0.00705882,0) [0|1.8] "V"  Receiver

BO_ 1898 HVP_vehicleDbg: 8 VEH
 SG_ HVP_ecuLogUploadRequest : 5|2@1+ (1,0) [0|0] "" Vector__XXX
 SG_ HVP_vehicleDebugMultiplexer M : 0|5@1+ (1,0) [0|0] "" Vector__XXX
 SG_ HVP_packNegativeContPwmDuty m0 : 8|14@1+ (0.01,0) [0|0] "%" Vector__XXX
 SG_ HVP_packPositiveContPwmDuty m0 : 22|14@1+ (0.01,0) [0|0] "%" Vector__XXX
 SG_ HVP_FcPositiveContPwmDuty m0 : 36|14@1+ (0.01,0) [0|0] "%" Vector__XXX
 SG_ HVP_FcNegativeContPwmDuty m0 : 50|14@1+ (0.01,0) [0|0] "%" Vector__XXX
 SG_ HVP_maxRobinBrickV m1 : 8|16@1- (0.001,0) [0|0] "V" Vector__XXX
 SG_ HVP_maxRobinBrickId m1 : 24|7@1+ (1,1) [0|0] "" Vector__XXX
 SG_ HVP_minRobinBrickV m1 : 32|16@1- (0.001,0) [0|0] "V" Vector__XXX
 SG_ HVP_minRobinBrickId m1 : 48|7@1+ (1,1) [0|0] "" Vector__XXX
 SG_ HVP_avgRobinBrickV m2 : 8|16@1- (0.001,0) [0|0] "V" Vector__XXX

BO_ 1962 HVP_debugMessage: 8 VEH
 SG_ HVP_debugMessageMultiplexer M : 0|4@1+ (1,0) [0|6] ""  Receiver
 SG_ HVP_auxCurrentMia m0 : 57|1@1+ (1,0) [0|1] ""  Receiver
 SG_ HVP_battery12V m5 : 36|12@1+ (0.1,0) [0|30] "V"  Receiver
 SG_ HVP_currentSenseMia m0 : 58|1@1+ (1,0) [0|1] ""  Receiver
 SG_ HVP_dcLinkNegativeV m3 : 8|16@1- (0.1,0) [-550|550] "V"  Receiver
 SG_ HVP_dcLinkPositiveV m3 : 24|16@1- (0.1,0) [-550|550] "V"  Receiver
 SG_ HVP_dcLinkVoltage m1 : 8|16@1- (0.1,0) [-3276.8|3276.7] "V"  Receiver
 SG_ HVP_fcContCoilCurrent m4 : 4|12@1+ (0.1,0) [0|7.5] "A"  Receiver
 SG_ HVP_fcContVoltage m4 : 16|12@1+ (0.1,0) [0|30] "V"  Receiver
 SG_ HVP_fcLinkNegativeV m3 : 40|16@1- (0.1,0) [-550|550] "V"  Receiver
 SG_ HVP_fcLinkPositiveV m5 : 8|16@1- (0.1,0) [-550|550] "V"  Receiver
 SG_ HVP_fcLinkVoltage m1 : 40|16@1- (0.1,0) [-3276.8|3276.7] "V"  Receiver
 SG_ HVP_gpioBmsEout m0 : 15|1@1+ (1,0) [0|1] ""  Receiver
 SG_ HVP_gpioCpFaultIn m0 : 6|1@1+ (1,0) [0|1] ""  Receiver
 SG_ HVP_gpioCpFaultOut m0 : 16|1@1+ (1,0) [0|1] ""  Receiver
 SG_ HVP_gpioCpLatchEnable m0 : 21|1@1+ (1,0) [0|1] ""  Receiver
 SG_ HVP_gpioCrashSignal m0 : 11|1@1+ (1,0) [0|1] ""  Receiver
 SG_ HVP_gpioFcContNegAux m0 : 14|1@1+ (1,0) [0|1] ""  Receiver
 SG_ HVP_gpioFcContPosAux m0 : 13|1@1+ (1,0) [0|1] ""  Receiver
 SG_ HVP_gpioFcContPowerEnable m0 : 25|1@1+ (1,0) [0|1] ""  Receiver
 SG_ HVP_gpioHvCablesOk m0 : 8|1@1+ (1,0) [0|1] ""  Receiver
 SG_ HVP_gpioHvilEnable m0 : 26|1@1+ (1,0) [0|1] ""  Receiver
 SG_ HVP_gpioHvpSelfEnable m0 : 9|1@1+ (1,0) [0|1] ""  Receiver
 SG_ HVP_gpioHvpVerEn m0 : 19|1@1+ (1,0) [0|1] ""  Receiver
 SG_ HVP_gpioLed m0 : 10|1@1+ (1,0) [0|1] ""  Receiver
 SG_ HVP_gpioPackContPowerEn m0 : 7|1@1+ (1,0) [0|1] ""  Receiver
 SG_ HVP_gpioPackCoontPosFlywheel m0 : 20|1@1+ (1,0) [0|1] ""  Receiver
 SG_ HVP_gpioPassivePyroDepl m0 : 4|1@1+ (1,0) [0|1] ""  Receiver
 SG_ HVP_gpioPcsChargePwmEnable m0 : 24|1@1+ (1,0) [0|1] ""  Receiver
 SG_ HVP_gpioPcsDcdcPwmEnable m0 : 23|1@1+ (1,0) [0|1] ""  Receiver
 SG_ HVP_gpioPcsEnable m0 : 22|1@1+ (1,0) [0|1] ""  Receiver
 SG_ HVP_gpioPyroIsoEn m0 : 5|1@1+ (1,0) [0|1] ""  Receiver
 SG_ HVP_gpioPyroPor m0 : 17|1@1+ (1,0) [0|1] ""  Receiver
 SG_ HVP_gpioSecDrdy m0 : 27|1@1+ (1,0) [0|1] ""  Receiver
 SG_ HVP_gpioShuntDataReady m0 : 12|1@1+ (1,0) [0|1] ""  Receiver
 SG_ HVP_gpioShuntEn m0 : 18|1@1+ (1,0) [0|1] ""  Receiver
 SG_ HVP_hvilInVoltage m4 : 28|12@1+ (0.1,0) [0|30] "V"  Receiver
 SG_ HVP_hvilOutVoltage m4 : 40|12@1+ (0.1,0) [0|30] "V"  Receiver
 SG_ HVP_hvp1v5Ref m0 : 28|12@1+ (0.1,0) [0|3] "V"  Receiver
 SG_ HVP_packContCoilCurrent m5 : 24|12@1+ (0.1,0) [0|7.5] "A"  Receiver
 SG_ HVP_packContVoltage m2 : 4|12@1+ (0.1,0) [0|30] "V"  Receiver
 SG_ HVP_packCurrentMia m0 : 56|1@1+ (1,0) [0|1] ""  Receiver
 SG_ HVP_packNegativeV m2 : 16|16@1- (0.1,0) [-550|550] "V"  Receiver
 SG_ HVP_packPositiveV m2 : 32|16@1- (0.1,0) [-550|550] "V"  Receiver
 SG_ HVP_packVoltage m1 : 24|16@1- (0.1,0) [-3276.8|3276.7] "V"  Receiver
 SG_ HVP_pyroAnalog m2 : 48|12@1+ (0.1,0) [0|3] "V"  Receiver
 SG_ HVP_shuntAsicTempDbg m6 : 40|16@1- (0.01,0) [-327.67|327.67] "C"  Receiver
 SG_ HVP_shuntAsicTempStatus m6 : 60|2@1+ (1,0) [0|3] ""  Receiver
 SG_ HVP_shuntAuxCurrentDbg m6 : 8|16@1- (0.1,0) [-3276.8|3276.7] "A"  Receiver
 SG_ HVP_shuntAuxCurrentStatus m6 : 56|2@1+ (1,0) [0|3] ""  Receiver
 SG_ HVP_shuntBarTempDbg m6 : 24|16@1- (0.01,0) [-327.67|327.67] "C"  Receiver
 SG_ HVP_shuntBarTempStatus m6 : 58|2@1+ (1,0) [0|3] ""  Receiver
 SG_ HVP_shuntCurrentDebug m0 : 40|16@1- (0.1,0) [-3276.8|3276.7] "A"  Receiver
 SG_ HVP_shuntHwMia m0 : 61|1@1+ (1,0) [0|1] ""  Receiver
 SG_ HVP_shuntRefVoltageDbg m5 : 48|16@1- (0.001,0) [-32.768|32.767] "V"  Receiver
 SG_ HVP_shuntRefVoltageMismatch m0 : 59|1@1+ (1,0) [0|1] ""  Receiver
 SG_ HVP_shuntThermistorMia m0 : 60|1@1+ (1,0) [0|1] ""  Receiver

BO_ 1992 EPBL_info: 8 VEH
 SG_ EPBL_infoIndex M : 0|8@1+ (1,0) [0|0] "" Vector__XXX
 SG_ EPBL_infoBuildType m10 : 8|3@1+ (1,0) [0|0] "" Vector__XXX
 SG_ EPBL_infoBuildConfigId m10 : 16|16@1+ (1,0) [0|0] "" Vector__XXX
 SG_ EPBL_infoHardwareId m10 : 32|16@1+ (1,0) [0|0] "" Vector__XXX
 SG_ EPBL_infoComponentId m10 : 48|16@1+ (1,0) [0|0] "" Vector__XXX
 SG_ EPBL_infoPcbaId m11 : 8|8@1+ (1,0) [0|0] "" Vector__XXX
 SG_ EPBL_infoAssemblyId m11 : 16|8@1+ (1,0) [0|0] "" Vector__XXX
 SG_ EPBL_infoUsageId m11 : 24|16@1+ (1,0) [0|0] "" Vector__XXX
 SG_ EPBL_infoSubUsageId m11 : 40|16@1+ (1,0) [0|0] "" Vector__XXX
 SG_ EPBL_infoAppCrc m13 : 8|32@1+ (1,0) [0|0] "" Vector__XXX
 SG_ EPBL_infoAppGitHash m17 : 10|54@1+ (4,0) [0|0] "" Vector__XXX
 SG_ EPBL_infoBootGitHash m18 : 10|54@1+ (4,0) [0|0] "" Vector__XXX
 SG_ EPBL_infoPlatformType m19 : 8|8@1+ (1,0) [0|0] "" Vector__XXX
 SG_ EPBL_infoBootUdsProtoVersion m20 : 8|16@1+ (1,0) [0|0] "" Vector__XXX
 SG_ EPBL_infoBootCrc m20 : 24|32@1+ (1,0) [0|0] "" Vector__XXX

BO_ 2005 DI_debug: 8 VEH
 SG_ DI_debugSelector M : 0|8@1+ (1,0) [0|0] "" Vector__XXX
 SG_ DI_motorType m128 : 8|5@1+ (1,0) [0|0] "" Vector__XXX
 SG_ DI_cpu1HzMin m128 : 16|8@1+ (0.4,0) [0|0] "%" Vector__XXX
 SG_ DI_cpu1HzMax m128 : 24|8@1+ (0.4,0) [0|0] "%" Vector__XXX
 SG_ DI_cpu1HzAvg m128 : 32|8@1+ (0.4,0) [0|0] "%" Vector__XXX
 SG_ DI_muSurfHigh m2 : 8|8@1+ (0.005,0) [0|0] "N/N" Vector__XXX
 SG_ DI_brakeCpScale m2 : 16|9@1- (0.01,0.5) [0|0] "N/N" Vector__XXX
 SG_ DI_pedalPosFilt m2 : 32|8@1+ (0.4,0) [0|0] "%" Vector__XXX
 SG_ DI_cpuIDWord0 m131 : 16|16@1+ (1,0) [0|0] "" Vector__XXX
 SG_ DI_crc m131 : 32|32@1+ (1,0) [0|0] "" Vector__XXX
 SG_ DI_cpuIDWord1 m132 : 16|16@1+ (1,0) [0|0] "" Vector__XXX
 SG_ DI_cpuIDWord2 m132 : 32|16@1+ (1,0) [0|0] "" Vector__XXX
 SG_ DI_cpuIDWord3 m132 : 48|16@1+ (1,0) [0|0] "" Vector__XXX
 SG_ DI_offsetA m32 : 8|8@1- (0.1,0) [0|0] "A" Vector__XXX
 SG_ DI_motorIA m32 : 16|16@1+ (0.1,0) [0|0] "A" Vector__XXX
 SG_ DI_motorIB m32 : 32|16@1+ (0.1,0) [0|0] "A" Vector__XXX
 SG_ DI_motorIC m32 : 48|16@1+ (0.1,0) [0|0] "A" Vector__XXX
 SG_ DI_offsetB m33 : 8|8@1- (0.1,0) [0|0] "A" Vector__XXX
 SG_ DI_statorIDref m33 : 16|16@1- (0.1,0) [0|0] "A" Vector__XXX
 SG_ DI_statorIDfdb m33 : 32|16@1- (0.1,0) [0|0] "A" Vector__XXX
 SG_ DI_torquePerAmp m33 : 48|16@1+ (0.0001,0) [0|0] "Nm/A" Vector__XXX
 SG_ DI_rsScale m34 : 8|8@1+ (0.01,0) [0|0] "scale" Vector__XXX
 SG_ DI_statorIQref m34 : 16|16@1- (0.1,0) [0|0] "A" Vector__XXX
 SG_ DI_statorIQfdb m34 : 32|16@1- (0.1,0) [0|0] "A" Vector__XXX
 SG_ DI_motorV m34 : 48|16@1+ (2e-05,0) [0|0] "mindex" Vector__XXX
 SG_ DI_tqScaleDifferential m35 : 8|8@1+ (0.4,0) [0|0] "%" Vector__XXX
 SG_ DI_statorFluxRef m35 : 16|16@1+ (0.0001,0) [0|0] "Wb" Vector__XXX
 SG_ DI_statorFluxFdb m35 : 32|16@1+ (0.0001,0) [0|0] "Wb" Vector__XXX
 SG_ DI_systemTorqueCommand m35 : 48|16@1- (0.035,0) [0|0] "Nm" Vector__XXX
 SG_ DI_lmScale m36 : 8|8@1+ (0.004,0) [0|0] "scale" Vector__XXX
 SG_ DI_statorVQ m36 : 16|16@1- (4e-05,0) [0|0] "mindex" Vector__XXX
 SG_ DI_statorVD m36 : 32|16@1- (4e-05,0) [0|0] "mindex" Vector__XXX
 SG_ DI_peakFlux m36 : 48|16@1+ (0.0001,0) [0|0] "Wb" Vector__XXX
 SG_ DI_gainScale m37 : 8|8@1+ (0.01,0) [0|0] "scale" Vector__XXX
 SG_ DI_dcCableCurrentEst m37 : 16|16@1- (0.1,0) [0|0] "A" Vector__XXX
 SG_ DI_loadAngleMargin m37 : 32|16@1- (0.0003,0) [0|0] "rad" Vector__XXX
 SG_ DI_internalAngleFilt m37 : 48|16@1+ (0.0003,0) [0|0] "rad" Vector__XXX
 SG_ DI_ssmState m38 : 8|4@1+ (1,0) [0|0] "" Vector__XXX
 SG_ DI_usmState m38 : 12|3@1+ (1,0) [0|0] "" Vector__XXX
 SG_ DI_peakIQref m38 : 16|16@1+ (0.1,0) [0|0] "A" Vector__XXX
 SG_ DI_motorIAavg m38 : 32|16@1- (0.1,0) [0|0] "A" Vector__XXX
 SG_ DI_motorIBavg m38 : 48|16@1- (0.1,0) [0|0] "A" Vector__XXX
 SG_ DI_tqSatThermal m39 : 8|8@1+ (0.4,0) [0|0] "%" Vector__XXX
 SG_ DI_pwrSatMaxDischargePower m39 : 16|8@1+ (0.4,0) [0|0] "%" Vector__XXX
 SG_ DI_pwrSatMaxRegenPower m39 : 24|8@1+ (0.4,0) [0|0] "%" Vector__XXX
 SG_ DI_tqSatMotorVoltage m39 : 32|8@1+ (0.4,0) [0|0] "%" Vector__XXX
 SG_ DI_tqSatMotorCurrent m39 : 40|8@1+ (0.4,0) [0|0] "%" Vector__XXX
 SG_ DI_pwrSatMaxBusVoltage m39 : 48|8@1+ (0.4,0) [0|0] "%" Vector__XXX
 SG_ DI_pwrSatMinBusVoltage m39 : 56|8@1+ (0.4,0) [0|0] "%" Vector__XXX
 SG_ DI_pwrSatDischargeCurrent m40 : 8|8@1+ (0.4,0) [0|0] "%" Vector__XXX
 SG_ DI_tcMaxRequest m40 : 16|8@1+ (5,0) [0|0] "Nm" Vector__XXX
 SG_ DI_tcMinRequest m40 : 24|8@1+ (5,0) [0|0] "Nm" Vector__XXX
 SG_ DI_tqSatUiDriveTorque m40 : 32|8@1+ (0.4,0) [0|0] "%" Vector__XXX
 SG_ DI_tqSatUiRegenTorque m40 : 40|8@1+ (0.4,0) [0|0] "%" Vector__XXX
 SG_ DI_tqScaleMaxMotorSpeed m40 : 48|8@1+ (0.4,0) [0|0] "%" Vector__XXX
 SG_ DI_tqScaleShift m40 : 56|8@1+ (0.4,0) [0|0] "%" Vector__XXX
 SG_ DI_veMassInvRaw m41 : 8|12@1+ (1e-07,0.0001) [0|0] "1/kg" Vector__XXX
 SG_ DI_veResForce m41 : 20|12@1- (0.0005,0) [0|0] "G" Vector__XXX
 SG_ DI_currentLimit m41 : 32|16@1+ (0.1,0) [0|0] "A" Vector__XXX
 SG_ DI_wasteCurrentLimit m41 : 48|16@1+ (0.1,0) [0|0] "A" Vector__XXX
 SG_ DI_pwrSatChargeCurrent m42 : 8|8@1+ (0.4,0) [0|0] "%" Vector__XXX
 SG_ DI_fluxState m42 : 16|4@1+ (1,0) [0|0] "" Vector__XXX
 SG_ DI_llsScale m42 : 24|8@1+ (0.004,0) [0|0] "scale" Vector__XXX
 SG_ DI_llrScale m42 : 32|8@1+ (0.015,0) [0|0] "scale" Vector__XXX
 SG_ DI_loadAngle m42 : 40|16@1- (0.0003,0) [0|0] "rad" Vector__XXX
 SG_ DI_brakeSwitchNO m42 : 62|1@1+ (1,0) [0|0] "" Vector__XXX
 SG_ DI_brakeSwitchNC m42 : 63|1@1+ (1,0) [0|0] "" Vector__XXX
 SG_ DI_sysPedalMinTorque m44 : 8|14@1+ (0.1,-1638.3) [0|0] "Nm" Vector__XXX
 SG_ DI_sysPedalMaxTorque m44 : 22|14@1+ (0.1,0) [0|0] "Nm" Vector__XXX
 SG_ DI_sysPostPedalMinTorque m44 : 36|14@1+ (0.1,-1638.3) [0|0] "Nm" Vector__XXX
 SG_ DI_sysPostPedalMaxTorque m44 : 50|14@1+ (0.1,0) [0|0] "Nm" Vector__XXX
 SG_ DI_aebFaultReason m45 : 16|4@1+ (1,0) [0|0] "" Vector__XXX
 SG_ DI_aebUnavailableReason m45 : 24|4@1+ (1,0) [0|0] "" Vector__XXX
 SG_ DI_aebCancelReason m45 : 32|8@1+ (1,0) [0|0] "" Vector__XXX
 SG_ DI_oilPumpPhaseCurrent m46 : 8|8@1+ (0.1,0) [0|0] "A" Vector__XXX
 SG_ DI_oilPumpPhaseVoltage m46 : 16|8@1+ (0.1,0) [0|0] "V" Vector__XXX
 SG_ DI_oilPumpPhaseAdvance m46 : 24|8@1+ (0.4,0) [0|0] "%" Vector__XXX
 SG_ DI_oilPumpPressureEstimate m46 : 32|8@1+ (2,0) [0|0] "kPa" Vector__XXX
 SG_ DI_rotorFlux m47 : 16|16@1+ (0.0001,0) [0|0] "Wb" Vector__XXX
 SG_ DI_dcCableHeat m47 : 32|16@1+ (0.001,0) [0|0] "kA2s" Vector__XXX
 SG_ DI_magnetTempEst m47 : 48|8@1+ (1,-40) [0|0] "DegC" Vector__XXX
 SG_ DI_magnetTempEst_SFO m47 : 56|8@1+ (1,-40) [0|0] "DegC" Vector__XXX
 SG_ DI_resolverOffsetCos m48 : 8|8@1+ (0.015,0) [0|0] "V" Vector__XXX
 SG_ DI_resolverOffsetSin m48 : 16|8@1+ (0.015,0) [0|0] "V" Vector__XXX
 SG_ DI_resolverPhaseOffset m48 : 24|8@1+ (0.1,7.5) [0|0] "us" Vector__XXX
 SG_ DI_resolverCommonGain m48 : 32|8@1+ (0.025,0) [0|0] "1" Vector__XXX
 SG_ DI_resolverReady m48 : 40|1@1+ (1,0) [0|0] "" Vector__XXX
 SG_ DI_resolverNoCarrier m48 : 41|1@1+ (1,0) [0|0] "" Vector__XXX
 SG_ DI_resolverNoPhaseLock m48 : 42|1@1+ (1,0) [0|0] "" Vector__XXX
 SG_ DI_resolverClaMIA m48 : 43|1@1+ (1,0) [0|0] "" Vector__XXX
 SG_ DI_soptTimeToTrip m49 : 8|8@1+ (0.05,0) [0|0] "ms" Vector__XXX
 SG_ DI_soptTripDelay m49 : 16|8@1+ (0.05,0) [0|0] "ms" Vector__XXX
 SG_ DI_soptTimeToOff m49 : 24|11@1+ (0.05,0) [0|0] "ms" Vector__XXX
 SG_ DI_soptMaxCurrentMagSqrd m49 : 40|16@1+ (100,0) [0|0] "A2" Vector__XXX
 SG_ DI_gateDriveSupplyState m50 : 8|2@1+ (1,0) [0|0] "" Vector__XXX
 SG_ DI_gateDriveState m50 : 10|3@1+ (1,0) [0|0] "" Vector__XXX
 SG_ DI_powerStageSafeState m50 : 13|2@1+ (1,0) [0|0] "" Vector__XXX
 SG_ DI_sysHeatPowerOptimal m50 : 16|8@1+ (0.08,0) [0|0] "kW" Vector__XXX
 SG_ DI_brkStState m50 : 24|3@1+ (1,0) [0|0] "" Vector__XXX
 SG_ DI_torquePedalMin m51 : 16|12@1+ (2,-7500) [0|0] "Nm" Vector__XXX
 SG_ DI_torquePedalMax m51 : 28|12@1+ (2,0) [0|0] "Nm" Vector__XXX
 SG_ DI_torquePostPedalMin m51 : 40|12@1+ (2,-7500) [0|0] "Nm" Vector__XXX
 SG_ DI_torquePostPedalMax m51 : 52|12@1+ (2,0) [0|0] "Nm" Vector__XXX
 SG_ DI_dcCapTemp m64 : 8|8@1+ (1,-40) [0|0] "DegC" Vector__XXX
 SG_ DI_busbarTemp m64 : 16|8@1+ (1,-40) [0|0] "DegC" Vector__XXX
 SG_ DI_pcsTemp m64 : 24|8@1+ (1,-40) [0|0] "DegC" Vector__XXX
 SG_ DI_statorTemp1 m64 : 32|8@1+ (1,-40) [0|0] "DegC" Vector__XXX
 SG_ DI_statorTemp2 m64 : 40|8@1+ (1,-40) [0|0] "DegC" Vector__XXX
 SG_ DI_immobilizerCondition m64 : 63|1@1+ (1,0) [0|0] "" Vector__XXX
 SG_ DI_velocityEstimatorState m65 : 8|3@1+ (1,0) [0|0] "" Vector__XXX
 SG_ DI_hvilCurrent m65 : 16|10@1+ (0.025,0) [0|0] "mA" Vector__XXX
 SG_ DI_hvilCmVoltage m65 : 32|10@1+ (0.02,0) [0|0] "V" Vector__XXX
 SG_ DI_cpu10HzMin m66 : 8|8@1+ (0.4,0) [0|0] "%" Vector__XXX
 SG_ DI_cpu10HzMax m66 : 16|8@1+ (0.4,0) [0|0] "%" Vector__XXX
 SG_ DI_cpu10HzAvg m66 : 24|8@1+ (0.4,0) [0|0] "%" Vector__XXX
 SG_ DI_cpu100HzMin m66 : 32|8@1+ (0.4,0) [0|0] "%" Vector__XXX
 SG_ DI_cpu100HzMax m66 : 40|8@1+ (0.4,0) [0|0] "%" Vector__XXX
 SG_ DI_cpu100HzAvg m66 : 48|8@1+ (0.4,0) [0|0] "%" Vector__XXX
 SG_ DI_module10HzStack m66 : 56|8@1+ (0.4,0) [0|0] "%" Vector__XXX
 SG_ DI_cpu1kHzMin m67 : 8|8@1+ (0.4,0) [0|0] "%" Vector__XXX
 SG_ DI_cpu1kHzMax m67 : 16|8@1+ (0.4,0) [0|0] "%" Vector__XXX
 SG_ DI_cpu1kHzAvg m67 : 24|8@1+ (0.4,0) [0|0] "%" Vector__XXX
 SG_ DI_cpu20kHzMin m67 : 32|8@1+ (0.4,0) [0|0] "%" Vector__XXX
 SG_ DI_cpu20kHzMax m67 : 40|8@1+ (0.4,0) [0|0] "%" Vector__XXX
 SG_ DI_cpu20kHzAvg m67 : 48|8@1+ (0.4,0) [0|0] "%" Vector__XXX
 SG_ DI_controlStack m67 : 56|8@1+ (0.4,0) [0|0] "%" Vector__XXX
 SG_ DI_systemStack m68 : 8|8@1+ (0.4,0) [0|0] "%" Vector__XXX
 SG_ DI_idleStack m68 : 16|8@1+ (0.4,0) [0|0] "%" Vector__XXX
 SG_ DI_decodeHardwareStack m68 : 24|8@1+ (0.4,0) [0|0] "%" Vector__XXX
 SG_ DI_eepromStack m68 : 32|8@1+ (0.4,0) [0|0] "%" Vector__XXX
 SG_ DI_udsStack m68 : 40|8@1+ (0.4,0) [0|0] "%" Vector__XXX
 SG_ DI_xcpStack m68 : 48|8@1+ (0.4,0) [0|0] "%" Vector__XXX
 SG_ DI_immobilizerStack m68 : 56|8@1+ (0.4,0) [0|0] "%" Vector__XXX
 SG_ DI_hwFaultCounter m69 : 8|4@1+ (1,0) [0|0] "" Vector__XXX
 SG_ DI_driveUnitOdometer m69 : 32|32@1+ (10,0) [0|0] "rev" Vector__XXX
 SG_ DI_phaseOutBusbarTemp m70 : 8|8@1+ (1,-40) [0|0] "DegC" Vector__XXX
 SG_ DI_phaseOutBusbarWeldTemp m70 : 16|8@1+ (1,-40) [0|0] "DegC" Vector__XXX
 SG_ DI_phaseOutLugTemp m70 : 24|8@1+ (1,-40) [0|0] "DegC" Vector__XXX
 SG_ DI_dcLinkCapTemp m70 : 32|8@1+ (1,-40) [0|0] "DegC" Vector__XXX
 SG_ DI_hvDcCableTemp m70 : 40|8@1+ (1,-40) [0|0] "DegC" Vector__XXX
 SG_ DI_negDcBusbarTemp m70 : 48|8@1+ (1,-40) [0|0] "DegC" Vector__XXX
 SG_ DI_posDcBusbarTemp m70 : 56|8@1+ (1,-40) [0|0] "DegC" Vector__XXX
 SG_ DI_statorEndWindingTemp m72 : 8|8@1+ (1,-40) [0|0] "DegC" Vector__XXX
 SG_ DI_rotorMaxMagnetTemp m72 : 16|8@1+ (1,-40) [0|0] "DegC" Vector__XXX

BO_ 2015 ID7DF_UDS_functionalRequest: 8 VEH
 SG_ UDS_functionalRequestData_0: 0|8@1+ (1,0) [0|0] "" X
 SG_ UDS_functionalRequestData_1: 8|8@1+ (1,0) [0|0] "" X
 SG_ UDS_functionalRequestData_2: 16|8@1+ (1,0) [0|0] "" X
 SG_ UDS_functionalRequestData_3: 24|8@1+ (1,0) [0|0] "" X
 SG_ UDS_functionalRequestData_4: 32|8@1+ (1,0) [0|0] "" X
 SG_ UDS_functionalRequestData_5: 40|8@1+ (1,0) [0|0] "" X
 SG_ UDS_functionalRequestData_6: 48|8@1+ (1,0) [0|0] "" X
 SG_ UDS_functionalRequestData_7: 56|8@1+ (1,0) [0|0] "" X

BO_ 2024 EPBR_info: 8 VEH
 SG_ EPBR_infoIndex M : 0|8@1+ (1,0) [0|0] "" Vector__XXX
 SG_ EPBR_infoBuildType m10 : 8|3@1+ (1,0) [0|0] "" Vector__XXX
 SG_ EPBR_infoBuildConfigId m10 : 16|16@1+ (1,0) [0|0] "" Vector__XXX
 SG_ EPBR_infoHardwareId m10 : 32|16@1+ (1,0) [0|0] "" Vector__XXX
 SG_ EPBR_infoComponentId m10 : 48|16@1+ (1,0) [0|0] "" Vector__XXX
 SG_ EPBR_infoPcbaId m11 : 8|8@1+ (1,0) [0|0] "" Vector__XXX
 SG_ EPBR_infoAssemblyId m11 : 16|8@1+ (1,0) [0|0] "" Vector__XXX
 SG_ EPBR_infoUsageId m11 : 24|16@1+ (1,0) [0|0] "" Vector__XXX
 SG_ EPBR_infoSubUsageId m11 : 40|16@1+ (1,0) [0|0] "" Vector__XXX
 SG_ EPBR_infoAppCrc m13 : 8|32@1+ (1,0) [0|0] "" Vector__XXX
 SG_ EPBR_infoAppGitHash m17 : 10|54@1+ (4,0) [0|0] "" Vector__XXX
 SG_ EPBR_infoBootGitHash m18 : 10|54@1+ (4,0) [0|0] "" Vector__XXX
 SG_ EPBR_infoPlatformType m19 : 8|8@1+ (1,0) [0|0] "" Vector__XXX
 SG_ EPBR_infoBootUdsProtoVersion m20 : 8|16@1+ (1,0) [0|0] "" Vector__XXX
 SG_ EPBR_infoBootCrc m20 : 24|32@1+ (1,0) [0|0] "" Vector__XXX

BO_ 2033 GTW_hrl: 7 VEH
 SG_ GTW_hrlIndex M : 0|2@1+ (1,0) [0|0] "" Vector__XXX
 SG_ GTW_hrlPagesCount m1 : 8|32@0+ (1,0) [0|0] "" Vector__XXX
 SG_ GTW_hrlState m2 : 2|1@1+ (1,0) [0|0] "" Vector__XXX
 SG_ GTW_hrlTriggerDuration m2 : 8|16@0+ (1,0) [0|0] "seconds" Vector__XXX
 SG_ GTW_hrlTriggerType m2 : 24|4@1+ (1,0) [0|0] "" Vector__XXX
 SG_ GTW_hrlTriggerId m2 : 32|16@0+ (1,0) [0|0] "" Vector__XXX
 SG_ GTW_hrlTriggerBus m2 : 48|3@1+ (1,0) [0|0] "" Vector__XXX

BO_ 2047 GTW_carConfig: 8 VEH
 SG_ GTW_carConfigMultiplexer M : 0|8@1+ (1,0) [0|255] ""  Receiver
 SG_ GTW_CabinBlowerCtrlType m2 : 30|1@1+ (1,0) [0|1] ""  Receiver
 SG_ GTW_activeHighBeam m2 : 34|1@1+ (1,0) [0|1] ""  Receiver
 SG_ GTW_airSuspension m3 : 22|2@1+ (1,0) [0|2] ""  Receiver
 SG_ GTW_airbagCutoffSwitch m2 : 35|1@1+ (1,0) [0|1] ""  Receiver
 SG_ GTW_audioType m3 : 30|2@1+ (1,0) [0|2] ""  Receiver
 SG_ GTW_autopilot m2 : 42|3@1+ (1,0) [0|4] ""  Receiver
 SG_ GTW_autopilotCameraType m3 : 26|1@1+ (1,0) [0|0] ""  Receiver
 SG_ GTW_auxParkLamps m2 : 26|2@1+ (1,0) [0|3] ""  Receiver
 SG_ GTW_bPillarNFCParam m2 : 56|1@1+ (1,0) [0|1] ""  Receiver
 SG_ GTW_birthday m4 : 8|32@1+ (1,0) [0|4294970000] ""  Receiver
 SG_ GTW_brakeHWType m2 : 59|2@1+ (1,0) [0|3] ""  Receiver
 SG_ GTW_brakeLineSwitchType m3 : 39|1@1+ (1,0) [0|1] ""  Receiver
 SG_ GTW_cabinPTCHeaterType m2 : 31|1@1+ (1,0) [0|1] ""  Receiver
 SG_ GTW_chassisType m3 : 18|3@1+ (1,0) [0|4] ""  Receiver
 SG_ GTW_compressorType m2 : 47|1@1+ (1,0) [0|1] ""  Receiver
 SG_ GTW_connectivityPackage m3 : 27|1@1+ (1,0) [0|1] ""  Receiver
 SG_ GTW_coolantPumpType m3 : 17|1@1+ (1,0) [0|1] ""  Receiver
 SG_ GTW_country m1 : 16|16@1+ (1,0) [0|65535] ""  Receiver
 SG_ GTW_dasHw m1 : 40|3@1+ (1,0) [3|4] ""  Receiver
 SG_ GTW_deliveryStatus m1 : 8|1@1+ (1,0) [0|1] ""  Receiver
 SG_ GTW_drivetrainType m1 : 10|1@1+ (1,0) [0|1] "" Vector__XXX
 SG_ GTW_eBuckConfig m2 : 32|1@1+ (1,0) [0|1] ""  Receiver
 SG_ GTW_eCallEnabled m4 : 40|2@1+ (1,0) [0|2] ""  Receiver
 SG_ GTW_efficiencyPackage m3 : 58|2@1+ (1,0) [0|3] ""  Receiver
 SG_ GTW_epasType m1 : 9|1@1+ (1,0) [0|1] ""  Receiver
 SG_ GTW_espValveType m3 : 40|2@1+ (1,0) [0|2] ""  Receiver
 SG_ GTW_exteriorColor m2 : 48|3@1+ (1,0) [0|6] ""  Receiver
 SG_ GTW_frontFogLamps m2 : 20|1@1+ (1,0) [0|1] ""  Receiver
 SG_ GTW_frontSeatHeaters m2 : 9|1@1+ (1,0) [0|1] ""  Receiver
 SG_ GTW_frontSeatReclinerHardware m3 : 37|2@1+ (1,0) [0|3] ""  Receiver
 SG_ GTW_frontSeatType m3 : 60|3@1+ (1,0) [0|4] ""  Receiver
 SG_ GTW_headlamps m1 : 14|2@1+ (1,0) [0|2] ""  Receiver
 SG_ GTW_headlightLevelerType m3 : 47|1@1+ (1,0) [0|1] ""  Receiver
 SG_ GTW_heatedWipers m2 : 8|1@1+ (1,0) [0|1] ""  Receiver
 SG_ GTW_homelinkType m2 : 13|1@1+ (1,0) [0|1] ""  Receiver
 SG_ GTW_hvacPanelVaneType m2 : 29|1@1+ (1,0) [0|1] ""  Receiver
 SG_ GTW_hvacQuietSnorkelType m2 : 28|1@1+ (1,0) [0|1] ""  Receiver
 SG_ GTW_ibstWakeType m2 : 24|1@1+ (1,0) [0|1] ""  Receiver
 SG_ GTW_immersiveAudio m3 : 56|2@1+ (1,0) [0|2] ""  Receiver
 SG_ GTW_interiorLighting m2 : 57|2@1+ (1,0) [0|2] ""  Receiver
 SG_ GTW_intrusionSensorType m2 : 36|1@1+ (1,0) [0|1] ""  Receiver
 SG_ GTW_loggingVersion m2 : 22|1@1+ (1,0) [0|1] ""  Receiver
 SG_ GTW_lumbarECUType m2 : 23|1@1+ (1,0) [0|1] ""  Receiver
 SG_ GTW_m3FrontOverheadConsoleType m2 : 25|1@1+ (1,0) [0|1] ""  Receiver
 SG_ GTW_mapRegion m3 : 8|4@1+ (1,0) [0|10] ""  Receiver
 SG_ GTW_memoryMirrors m2 : 17|1@1+ (1,0) [0|1] ""  Receiver
 SG_ GTW_numberHVILNodes m2 : 51|3@1+ (1,0) [0|5] ""  Receiver
 SG_ GTW_packEnergy m3 : 32|5@1+ (1,0) [0|4] ""  Receiver
 SG_ GTW_packMassDeviation m4 : 42|1@1+ (1,0) [0|1] ""  Receiver
 SG_ GTW_passengerAirbagType m4 : 43|2@1+ (1,0) [0|2] ""  Receiver
 SG_ GTW_passengerOccupancySensorType m3 : 24|1@1+ (1,0) [0|1] ""  Receiver
 SG_ GTW_pedestrianWarningSound m2 : 54|1@1+ (1,0) [0|1] ""  Receiver
 SG_ GTW_performancePackage m3 : 12|3@1+ (1,0) [0|3] ""  Receiver
 SG_ GTW_plcSupportType m3 : 28|2@1+ (1,0) [0|2] ""  Receiver
 SG_ GTW_powerSteeringColumn m2 : 18|1@1+ (1,0) [0|1] ""  Receiver
 SG_ GTW_radarHeaterType m3 : 55|1@1+ (1,0) [0|1] ""  Receiver
 SG_ GTW_rearDriveUnitType m3 : 21|1@1+ (1,0) [0|1] ""  Receiver
 SG_ GTW_rearFogLamps m2 : 39|1@1+ (1,0) [0|1] ""  Receiver
 SG_ GTW_rearGlassType m2 : 38|1@1+ (1,0) [0|1] ""  Receiver
 SG_ GTW_rearLightType m1 : 12|2@1+ (1,0) [0|2] ""  Receiver
 SG_ GTW_rearSeatHeaters m2 : 10|1@1+ (1,0) [0|1] ""  Receiver
 SG_ GTW_refrigerantType m3 : 45|2@1+ (1,0) [0|2] ""  Receiver
 SG_ GTW_restraintsHardwareType m1 : 48|8@1+ (1,0) [21|163] ""  Receiver
 SG_ GTW_rightHandDrive m1 : 11|1@1+ (1,0) [0|1] ""  Receiver
 SG_ GTW_roofGlassType m2 : 61|1@1+ (1,0) [0|1] ""  Receiver
 SG_ GTW_roofType m2 : 40|2@1+ (1,0) [0|2] ""  Receiver
 SG_ GTW_softRange m3 : 42|3@1+ (1,0) [0|2] ""  Receiver
 SG_ GTW_spoilerType m2 : 37|1@1+ (1,0) [0|1] ""  Receiver
 SG_ GTW_steeringColumnUJointType m2 : 55|1@1+ (1,0) [0|1] ""  Receiver
 SG_ GTW_superchargingAccess m2 : 45|2@1+ (1,0) [0|2] ""  Receiver
 SG_ GTW_tireType m1 : 32|5@1+ (1,0) [0|21] ""  Receiver
 SG_ GTW_towPackage m3 : 15|1@1+ (1,0) [0|1] ""  Receiver
 SG_ GTW_tpmsType m2 : 11|1@1+ (1,0) [0|1] ""  Receiver
 SG_ GTW_trackModePackage m2 : 62|1@1+ (1,0) [0|1] ""  Receiver
 SG_ GTW_twelveVBatteryType m3 : 63|1@1+ (1,0) [0|1] ""  Receiver
 SG_ GTW_vdcType m2 : 14|1@1+ (1,0) [0|1] ""  Receiver
 SG_ GTW_wheelType m3 : 48|7@1+ (1,0) [0|20] ""  Receiver
 SG_ GTW_windshieldType m2 : 33|1@1+ (1,0) [0|1] ""  Receiver
 SG_ GTW_xcpESP m2 : 16|1@1+ (1,0) [0|1] ""  Receiver
 SG_ GTW_xcpIbst m2 : 15|1@1+ (1,0) [0|1] ""  Receiver

BA_DEF_ BO_  "GenMsgSendType" ENUM  "Cyclic";
BA_DEF_ BO_  "GenMsgCycleTime" INT 0 10000;
BA_ "GenMsgSendType" BO_ 1320 0;
BA_ "GenMsgCycleTime" BO_ 1320 100;
BA_ "GenMsgSendType" BO_ 1040 0;
BA_ "GenMsgCycleTime" BO_ 1040 500;
BA_ "GenMsgSendType" BO_ 1353 0;
BA_ "GenMsgCycleTime" BO_ 1353 1000;
BA_ "GenMsgSendType" BO_ 1065 0;
BA_ "GenMsgCycleTime" BO_ 1065 1000;
BA_ "GenMsgSendType" BO_ 1081 0;
BA_ "GenMsgCycleTime" BO_ 1081 1000;
BA_ "GenMsgSendType" BO_ 1097 0;
BA_ "GenMsgCycleTime" BO_ 1097 1000;
BA_ "GenMsgSendType" BO_ 1113 0;
BA_ "GenMsgCycleTime" BO_ 1113 1000;
BA_ "GenMsgSendType" BO_ 1132 0;
BA_ "GenMsgCycleTime" BO_ 1132 1000;
BA_ "GenMsgSendType" BO_ 1342 0;
BA_ "GenMsgCycleTime" BO_ 1342 1000;
BA_ "GenMsgSendType" BO_ 1885 0;
BA_ "GenMsgCycleTime" BO_ 1885 200;
BA_ "GenMsgSendType" BO_ 1337 0;
BA_ "GenMsgCycleTime" BO_ 1337 1000;
BA_ "GenMsgSendType" BO_ 1548 0;
BA_ "GenMsgCycleTime" BO_ 1548 5;
BA_ "GenMsgSendType" BO_ 1082 0;
BA_ "GenMsgCycleTime" BO_ 1082 1000;
BA_ "GenMsgSendType" BO_ 1879 0;
BA_ "GenMsgCycleTime" BO_ 1879 100;
BA_ "GenMsgSendType" BO_ 1880 0;
BA_ "GenMsgCycleTime" BO_ 1880 10;
BA_ "GenMsgSendType" BO_ 1622 0;
BA_ "GenMsgCycleTime" BO_ 1622 1000;
BA_ "GenMsgSendType" BO_ 1367 0;
BA_ "GenMsgCycleTime" BO_ 1367 1000;
BA_ "GenMsgSendType" BO_ 1992 0;
BA_ "GenMsgCycleTime" BO_ 1992 1000;
BA_ "GenMsgSendType" BO_ 2024 0;
BA_ "GenMsgCycleTime" BO_ 2024 1000;
BA_ "GenMsgSendType" BO_ 1303 0;
BA_ "GenMsgCycleTime" BO_ 1303 1000;
BA_ "GenMsgSendType" BO_ 1310 0;
BA_ "GenMsgCycleTime" BO_ 1310 1000;
BA_ "GenMsgSendType" BO_ 1345 0;
BA_ "GenMsgCycleTime" BO_ 1345 100;
BA_ "GenMsgSendType" BO_ 2047 0;
BA_ "GenMsgCycleTime" BO_ 2047 100;
BA_ "GenMsgSendType" BO_ 1080 0;
BA_ "GenMsgCycleTime" BO_ 1080 100;
BA_ "GenMsgSendType" BO_ 1376 0;
BA_ "GenMsgCycleTime" BO_ 1376 1000;
BA_ "GenMsgSendType" BO_ 2033 0;
BA_ "GenMsgCycleTime" BO_ 2033 2000;
BA_ "GenMsgSendType" BO_ 1112 0;
BA_ "GenMsgCycleTime" BO_ 1112 100;
BA_ "GenMsgSendType" BO_ 1962 0;
BA_ "GenMsgCycleTime" BO_ 1962 1000;
BA_ "GenMsgSendType" BO_ 1898 0;
BA_ "GenMsgCycleTime" BO_ 1898 300;
BA_ "GenMsgSendType" BO_ 1748 0;
BA_ "GenMsgCycleTime" BO_ 1748 1000;
BA_ "GenMsgSendType" BO_ 1282 0;
BA_ "GenMsgCycleTime" BO_ 1282 1000;
BA_ "GenMsgSendType" BO_ 1329 0;
BA_ "GenMsgCycleTime" BO_ 1329 1000;
BA_ "GenMsgSendType" BO_ 1359 0;
BA_ "GenMsgCycleTime" BO_ 1359 100;
BA_ "GenMsgSendType" BO_ 1355 0;
BA_ "GenMsgCycleTime" BO_ 1355 1000;
BA_ "GenMsgSendType" BO_ 1357 0;
BA_ "GenMsgCycleTime" BO_ 1357 1000;
BA_ "GenMsgSendType" BO_ 1280 0;
BA_ "GenMsgCycleTime" BO_ 1280 5000;
BA_ "GenMsgSendType" BO_ 1096 0;
BA_ "GenMsgCycleTime" BO_ 1096 1000;
BA_ "GenMsgSendType" BO_ 1139 0;
BA_ "GenMsgCycleTime" BO_ 1139 500;
BA_ "GenMsgSendType" BO_ 1064 0;
BA_ "GenMsgCycleTime" BO_ 1064 1000;
BA_ "GenMsgSendType" BO_ 1860 0;
BA_ "GenMsgCycleTime" BO_ 1860 1000;
BA_ "GenMsgSendType" BO_ 1250 0;
BA_ "GenMsgCycleTime" BO_ 1250 100;
BA_ "GenMsgSendType" BO_ 1795 0;
BA_ "GenMsgCycleTime" BO_ 1795 10;
BA_ "GenMsgSendType" BO_ 1859 0;
BA_ "GenMsgCycleTime" BO_ 1859 1000;
BA_ "GenMsgSendType" BO_ 1251 0;
BA_ "GenMsgCycleTime" BO_ 1251 100;
VAL_ 1066 VCSEC_TPMSConnectionTypeCurrent0 0 "CONNECTIONTYPE_FAST" 1 "CONNECTIONTYPE_SLOW" 2 "CONNECTIONTYPE_UNKNOWN" ;
VAL_ 1066 VCSEC_TPMSConnectionTypeCurrent0 0 "CONNECTIONTYPE_FAST" 1 "CONNECTIONTYPE_SLOW" 2 "CONNECTIONTYPE_UNKNOWN" ;
VAL_ 1066 VCSEC_TPMSConnectionTypeCurrent1 0 "CONNECTIONTYPE_FAST" 1 "CONNECTIONTYPE_SLOW" 2 "CONNECTIONTYPE_UNKNOWN" ;
VAL_ 1066 VCSEC_TPMSConnectionTypeCurrent2 0 "CONNECTIONTYPE_FAST" 1 "CONNECTIONTYPE_SLOW" 2 "CONNECTIONTYPE_UNKNOWN" ;
VAL_ 1066 VCSEC_TPMSConnectionTypeCurrent3 0 "CONNECTIONTYPE_FAST" 1 "CONNECTIONTYPE_SLOW" 2 "CONNECTIONTYPE_UNKNOWN" ;
VAL_ 1066 VCSEC_TPMSConnectionTypeDesired0 0 "CONNECTIONTYPE_FAST" 1 "CONNECTIONTYPE_SLOW" 2 "CONNECTIONTYPE_UNKNOWN" ;
VAL_ 1066 VCSEC_TPMSConnectionTypeDesired1 0 "CONNECTIONTYPE_FAST" 1 "CONNECTIONTYPE_SLOW" 2 "CONNECTIONTYPE_UNKNOWN" ;
VAL_ 1066 VCSEC_TPMSConnectionTypeDesired2 0 "CONNECTIONTYPE_FAST" 1 "CONNECTIONTYPE_SLOW" 2 "CONNECTIONTYPE_UNKNOWN" ;
VAL_ 1066 VCSEC_TPMSConnectionTypeDesired3 0 "CONNECTIONTYPE_FAST" 1 "CONNECTIONTYPE_SLOW" 2 "CONNECTIONTYPE_UNKNOWN" ;
VAL_ 1066 VCSEC_TPMSSensorState0 3 "SENSOR_CONNECTED" 4 "SENSOR_DISCONNECTING" 0 "SENSOR_NOT_PAIRED" 1 "SENSOR_WAIT_FOR_ADV" 2 "SENSOR_WAIT_FOR_CONN" ;
VAL_ 1066 VCSEC_TPMSSensorState1 3 "SENSOR_CONNECTED" 4 "SENSOR_DISCONNECTING" 0 "SENSOR_NOT_PAIRED" 1 "SENSOR_WAIT_FOR_ADV" 2 "SENSOR_WAIT_FOR_CONN" ;
VAL_ 1066 VCSEC_TPMSSensorState2 3 "SENSOR_CONNECTED" 4 "SENSOR_DISCONNECTING" 0 "SENSOR_NOT_PAIRED" 1 "SENSOR_WAIT_FOR_ADV" 2 "SENSOR_WAIT_FOR_CONN" ;
VAL_ 1066 VCSEC_TPMSSensorState3 3 "SENSOR_CONNECTED" 4 "SENSOR_DISCONNECTING" 0 "SENSOR_NOT_PAIRED" 1 "SENSOR_WAIT_FOR_ADV" 2 "SENSOR_WAIT_FOR_CONN" ;
VAL_ 1080 GTW_VEHWakeUpReason 0 "NONE" 1 "RESET" 2 "GSM_RI" 3 "CH_CAN" 4 "VEH_CAN" 5 "VEH_CAN" 6 "VCFRONT" 7 "RTC_ALARM" 8 "UI_SCHEDULED" ;
VAL_ 1085 CP_chargeShutdownRequest_log 2 "EMERGENCY_SHUTDOWN_REQUESTED" 1 "GRACEFUL_SHUTDOWN_REQUESTED" 0 "NO_SHUTDOWN_REQUESTED" ;
VAL_ 1085 CP_chargeShutdownRequest_log 2 "EMERGENCY_SHUTDOWN_REQUESTED" 1 "GRACEFUL_SHUTDOWN_REQUESTED" 0 "NO_SHUTDOWN_REQUESTED" ;
VAL_ 1085 CP_evseChargeType_log 2 "AC_CHARGER_PRESENT" 1 "DC_CHARGER_PRESENT" 0 "NO_CHARGER_PRESENT" ;
VAL_ 1085 CP_hvChargeStatus_log 1 "CP_CHARGE_CONNECTED" 5 "CP_CHARGE_ENABLED" 6 "CP_CHARGE_FAULTED" 0 "CP_CHARGE_INACTIVE" 2 "CP_CHARGE_STANDBY" 4 "CP_EVSE_TEST_PASSED" 3 "CP_EXT_EVSE_TEST_ACTIVE" ;
VAL_ 1096 UI_anonDebugFlag1 0 "OFF" 1 "ON" ;
VAL_ 1096 UI_anonDebugFlag2 0 "OFF" 1 "ON" ;
VAL_ 1096 UI_anonDebugFlag3 0 "OFF" 1 "ON" ;
VAL_ 1096 UI_anonDebugFlag4 0 "OFF" 1 "ON" ;
VAL_ 1112 GTW_nmKeepAwakeReason 0 "NONE_SNA" 15 "TBD" ;
VAL_ 1112 GTW_nmWakeUpReason 0 "NONE" 1 "RESET" 2 "GSM_RI" 3 "CH_CAN" 4 "VEH_CAN" 5 "VEH_CAN" 6 "VCFRONT" 7 "RTC_ALARM" 8 "UI_SCHEDULED" ;
VAL_ 1139 UI_nmKeepAwakeReason 0 "NONE_SNA" 1 "KEEPALIVEACTIVE" 2 "GUI_NEVER_SLEEP_SET" 3 "PM_CHECKING" 4 "UNKNOWN_REMOTE_REQUEST" 5 "MODEM_RESET" 6 "UPDATER" 7 "HERMES" 8 "AUTOFUSER" 9 "UPDATE_COUNTDOWN" 15 "MULTIPLE" ;
VAL_ 1250 VCLEFT_seatStatusIndex 0 "TRACK" 1 "BACK" 2 "LIFT" 3 "TILT" 4 "LUMBAR" 5 "POSITION" ;
VAL_ 1250 VCLEFT_frontSeatTrackState 0 "STOPPED" 1 "MOVING_UP" 2 "MOVING_DOWN" 3 "RECALLING" 4 "CALIBRATING" 5 "UNDEFINED" ;
VAL_ 1250 VCLEFT_frontSeatBackState 0 "STOPPED" 1 "MOVING_UP" 2 "MOVING_DOWN" 3 "RECALLING" 4 "CALIBRATING" 5 "UNDEFINED" ;
VAL_ 1250 VCLEFT_frontSeatLiftState 0 "STOPPED" 1 "MOVING_UP" 2 "MOVING_DOWN" 3 "RECALLING" 4 "CALIBRATING" 5 "UNDEFINED" ;
VAL_ 1250 VCLEFT_frontSeatTiltState 0 "STOPPED" 1 "MOVING_UP" 2 "MOVING_DOWN" 3 "RECALLING" 4 "CALIBRATING" 5 "UNDEFINED" ;
VAL_ 1250 VCLEFT_lumbarAState 0 "STOPPED" 1 "MOVING_UP" 2 "MOVING_DOWN" 3 "RECALLING" 4 "CALIBRATING" 5 "UNDEFINED" ;
VAL_ 1250 VCLEFT_lumbarBState 0 "STOPPED" 1 "MOVING_UP" 2 "MOVING_DOWN" 3 "RECALLING" 4 "CALIBRATING" 5 "UNDEFINED" ;
VAL_ 1251 VCRIGHT_seatStatusIndex 0 "TRACK" 1 "BACK" 2 "LIFT" 3 "TILT" 4 "LUMBAR" 5 "POSITION" ;
VAL_ 1251 VCRIGHT_frontSeatTrackState 0 "STOPPED" 1 "MOVING_UP" 2 "MOVING_DOWN" 3 "RECALLING" 4 "CALIBRATING" 5 "UNDEFINED" ;
VAL_ 1251 VCRIGHT_frontSeatBackState 0 "STOPPED" 1 "MOVING_UP" 2 "MOVING_DOWN" 3 "RECALLING" 4 "CALIBRATING" 5 "UNDEFINED" ;
VAL_ 1251 VCRIGHT_frontSeatLiftState 0 "STOPPED" 1 "MOVING_UP" 2 "MOVING_DOWN" 3 "RECALLING" 4 "CALIBRATING" 5 "UNDEFINED" ;
VAL_ 1251 VCRIGHT_frontSeatTiltState 0 "STOPPED" 1 "MOVING_UP" 2 "MOVING_DOWN" 3 "RECALLING" 4 "CALIBRATING" 5 "UNDEFINED" ;
VAL_ 1251 VCRIGHT_lumbarAState 0 "STOPPED" 1 "MOVING_UP" 2 "MOVING_DOWN" 3 "RECALLING" 4 "CALIBRATING" 5 "UNDEFINED" ;
VAL_ 1251 VCRIGHT_lumbarBState 0 "STOPPED" 1 "MOVING_UP" 2 "MOVING_DOWN" 3 "RECALLING" 4 "CALIBRATING" 5 "UNDEFINED" ;
VAL_ 1280 UI_debugEcuTarget 1 "DI" 2 "DIS" 3 "PM" 4 "PMS" 5 "BMS" 6 "VCRIGHT" 7 "VCFRONT" ;
VAL_ 1310 FC_infoIndex 0 "DEPRECATED_0_FC" 1 "DEPRECATED_1_FC" 2 "DEPRECATED_2_FC" 3 "DEPRECATED_3_FC" 4 "DEPRECATED_4_FC" 5 "DEPRECATED_5_FC" 6 "DEPRECATED_6_FC" 7 "DEPRECATED_7_FC" 8 "DEPRECATED_8_FC" 9 "DEPRECATED_9_FC" 10 "BUILD_HWID_COMPONENTID_FC" 11 "PCBAID_ASSYID_USAGEID_FC" 13 "APP_CRC_FC" 14 "BOOTLOADER_SVN_FC" 15 "BOOTLOADER_CRC_FC" 16 "SUBCOMPONENT_FC" 17 "APP_GITHASH_FC" 18 "BOOTLOADER_GITHASH_FC" 19 "VERSION_DEPRECATED_FC" 20 "UDS_PROTOCOL_BOOTCRC_FC" 22 "VARIANT_CRC_FC" 25 "PART_NUM_1" 26 "PART_NUM_2" 27 "PART_NUM_3" 255 "END_FC" ;
VAL_ 1310 FC_infoBuildType 0 "UNKNOWN_BUILD_FC" 1 "PLATFORM_BUILD_FC" 2 "LOCAL_BUILD_FC" 3 "TRACEABLE_CI_BUILD_FC" 4 "MFG_BUILD_FC" ;
VAL_ 1329 RADC_infoIndex 10 "Mux10" 11 "Mux11" 13 "Mux13" 19 "Mux19" 20 "Mux20" ;
VAL_ 1329 RADC_infoBuildType 0 "UNKNOWN_BUILD" 1 "PLATFORM_BUILD" 2 "LOCAL_BUILD" 3 "TRACEABLE_CI_BUILD" 4 "MFG_BUILD" ;
VAL_ 1337 DAS_infoIndex 0 "DEPRECATED_0" 1 "DEPRECATED_1" 2 "DEPRECATED_2" 3 "DEPRECATED_3" 4 "DEPRECATED_4" 5 "DEPRECATED_5" 6 "DEPRECATED_6" 7 "DEPRECATED_7" 8 "DEPRECATED_8" 9 "DEPRECATED_9" 10 "BUILD_HWID_COMPONENTID" 11 "PCBAID_ASSYID_USAGEID" 13 "APP_CRC" 14 "BOOTLOADER_SVN" 15 "BOOTLOADER_CRC" 16 "EYEQ_BOOT" 17 "APP_GITHASH" 18 "BOOTLOADER_GITHASH" 19 "VERSION_DEPRECATED" 20 "UDS_PROTOCOL_BOOTCRC" 23 "EYEQ_APP" 24 "EYEQ_FFS" 255 "END" ;
VAL_ 1337 DAS_infoBuildType 0 "UNKNOWN_BUILD" 1 "PLATFORM_BUILD" 2 "LOCAL_BUILD" 3 "TRACEABLE_CI_BUILD" 4 "MFG_BUILD" ;
VAL_ 1337 DAS_infoHardwareRevision 252 "CONFIGURABLE_HWID_PLACEHOLDER" ;
VAL_ 1342 CP_infoIndex 0 "DEPRECATED_0" 1 "DEPRECATED_1" 2 "DEPRECATED_2" 3 "DEPRECATED_3" 4 "DEPRECATED_4" 5 "DEPRECATED_5" 6 "DEPRECATED_6" 7 "DEPRECATED_7" 8 "DEPRECATED_8" 9 "DEPRECATED_9" 10 "BUILD_HWID_COMPONENTID" 11 "PCBAID_ASSYID_USAGEID" 13 "APP_CRC" 14 "BOOTLOADER_SVN" 15 "BOOTLOADER_CRC" 16 "SUBCOMPONENT" 17 "APP_GITHASH" 18 "BOOTLOADER_GITHASH" 19 "VERSION_DEPRECATED" 20 "UDS_PROTOCOL_BOOTCRC" 22 "VARIANTCRC" 25 "PACKAGE_PN_1_7" 26 "PACKAGE_PN_8_14" 27 "PACKAGE_PN_15_20" 29 "PACKAGE_SN_1_7" 30 "PACKAGE_SN_8_14" 31 "SUBCOMPONENT_GITHASH" 255 "END" ;
VAL_ 1342 CP_buildType 0 "UNKNOWN_BUILD" 1 "PLATFORM_BUILD" 2 "LOCAL_BUILD" 3 "TRACEABLE_CI_BUILD" 4 "MFG_BUILD" ;
VAL_ 1353 APP_infoIndex 0 "AP_BUILD_TYPE" 1 "FW_GITHASH" 2 "AP_GITHASH" ;
VAL_ 1353 APP_buildType 0 "SIGNED" 1 "LOCAL" 3 "REPO" ;
VAL_ 1357 TAS_infoIndex 0 "DEPRECATED_0" 1 "DEPRECATED_1" 2 "DEPRECATED_2" 3 "DEPRECATED_3" 4 "DEPRECATED_4" 5 "DEPRECATED_5" 6 "DEPRECATED_6" 7 "DEPRECATED_7" 8 "DEPRECATED_8" 9 "DEPRECATED_9" 10 "BUILD_HWID_COMPONENTID" 11 "PCBAID_ASSYID_USAGEID" 13 "APP_CRC" 14 "BOOTLOADER_SVN" 15 "BOOTLOADER_CRC" 16 "SUBCOMPONENT1" 17 "APP_GITHASH" 18 "BOOTLOADER_GITHASH" 19 "VERSION_DEPRECATED" 20 "UDS_PROTOCOL_BOOTCRC" 23 "SUBCOMPONENT2" 24 "SUBCOMPONENT3" 31 "SUBCOMPONENT4" 255 "END" ;
VAL_ 1357 TAS_infoBuildType 0 "UNKNOWN_BUILD" 1 "PLATFORM_BUILD" 2 "LOCAL_BUILD" 3 "TRACEABLE_CI_BUILD" 4 "MFG_BUILD" ;
VAL_ 1357 TAS_infoAssemblyId 1 "ASSEMBLY1" 255 "ASSEMBLY_SNA" ;
VAL_ 1357 TAS_infoMajorVersion 254 "LOCAL_BUILD" 255 "SNA" ;
VAL_ 1357 TAS_infoBranchOrigin 254 "LOCAL_BUILD" 255 "SNA" ;
VAL_ 1357 TAS_infoMaturity 254 "LOCAL_BUILD" 255 "SNA" ;
VAL_ 1357 TAS_infoHardwareRevision 254 "LOCAL_BUILD" 255 "SNA" ;
VAL_ 1359 SCCM_matrixIndex 0 "SCCM_AlertMatrix0" ;
VAL_ 1366 DIF_IGBTJunctTemp 255 "SNA" ;
VAL_ 1366 DIF_IGBTJunctTemp 255 "SNA" ;
VAL_ 1493 DI_IGBTJunctTemp 255 "SNA" ;
VAL_ 1493 DI_IGBTJunctTemp 255 "SNA" ;
VAL_ 1519 TPMS_infoIndex 0 "DEPRECATED_0" 1 "DEPRECATED_1" 2 "DEPRECATED_2" 3 "DEPRECATED_3" 4 "DEPRECATED_4" 5 "DEPRECATED_5" 6 "DEPRECATED_6" 7 "DEPRECATED_7" 8 "DEPRECATED_8" 9 "DEPRECATED_9" 10 "BUILD_HWID_COMPONENTID" 11 "PCBAID_ASSYID_USAGEID" 13 "APP_CRC" 14 "BOOTLOADER_SVN" 15 "BOOTLOADER_CRC" 16 "SUBCOMPONENT" 17 "APP_GITHASH" 18 "BOOTLOADER_GITHASH" 19 "VERSION_DEPRECATED" 20 "UDS_PROTOCOL_BOOTCRC" 22 "VARIANTCRC" 25 "PACKAGE_PN_1_7" 26 "PACKAGE_PN_8_14" 27 "PACKAGE_PN_15_20" 29 "PACKAGE_SN_1_7" 30 "PACKAGE_SN_8_14" 31 "SUBCOMPONENT_GITHASH" 255 "END" ;
VAL_ 1523 UI_alertID 0 "ALERT_DO_NOT_USE_ZERO" 1 "a001_DriverDoorOpen" 2 "a002_DoorOpen" 3 "a003_TrunkOpen" 4 "a004_FrunkOpen" 5 "a005_HeadlightsOnDoorOpen" 6 "a006_RemoteServiceAlert" 7 "a007_SoftPackConfigMismatch" 8 "a008_TouchScreenError" 9 "a009_SquashfsError" 10 "a010_MapsMissing" 11 "a011_IncorrectMap" 12 "a012_NotOnPrivateProperty" 13 "a013_TPMSHardWarning" 14 "a014_TPMSSoftWarning" 15 "a015_TPMSOverPressureWarning" 16 "a016_TPMSTemperatureWarning" 17 "a017_TPMSSystemFault" 18 "a018_SlipStartOn" 19 "a019_ParkBrakeFault" 20 "a020_SteeringReduced" 21 "a021_RearSeatbeltUnbuckled" 22 "a022_ApeFusesEtc" 23 "a023_CellInternetCheckFailed" 24 "a024_WifiInternetCheckFailed" 25 "a025_WifiOnlineCheckFailed" 26 "a026_ModemResetLoopDetected" 27 "a027_AutoSteerMIA" 28 "a028_FrontTrunkPopupClosed" 29 "a029_ModemMIA" 30 "a030_ModemVMCrash" 31 "a031_BrakeFluidLow" 32 "a032_CellModemRecoveryResets" 33 "a033_ApTrialExpired" 34 "a034_WakeupProblem" 35 "a035_AudioWatchdogKernelError" 36 "a036_AudioWatchdogHfpError" 37 "a037_AudioWatchdogXrunStormError" 38 "a038_AudioWatchdogA2bI2cLockupError" 39 "a039_AudioA2bNeedRediscovery" 40 "a040_HomelinkTransmit" 41 "a041_AudioDmesgXrun" 42 "a042_AudioDmesgRtThrottling" 43 "a043_InvalidMapDataOverride" 44 "a044_AudioDmesgDspException" ;
VAL_ 1523 UI_alertState 0 "CLEARED" 1 "SET" ;
VAL_ 1548 DAS_TR_ObjIndex 0 "Mux0" 1 "Mux1" 2 "Mux2" 3 "Mux3" 4 "Mux4" 5 "Mux5" 6 "Mux6" 7 "Mux7" 8 "Mux8" 9 "Mux9" 10 "Mux10" 11 "Mux11" 12 "Mux12" 13 "Mux13" 14 "Mux14" 15 "Mux15" 16 "Mux16" 17 "Mux17" 18 "Mux18" 19 "Mux19" 20 "Mux20" 21 "Mux21" 22 "Mux22" 23 "Mux23" 24 "Mux24" 25 "Mux25" 26 "Mux26" 27 "Mux27" 28 "Mux28" 29 "Mux29" 30 "Mux30" 31 "Mux31" ;
VAL_ 1548 DAS_TR_Obj00_Class 0 "UNKNOWN" 1 "MOVING_FOUR_WHEEL_VEHICLE" 2 "MOVING_TWO_WHEEL_VEHICLE" 3 "MOVING_PEDESTRIAN" 4 "CONSTRUCTION_ELEMENT" ;
VAL_ 1548 DAS_TR_Obj00_MovingState 0 "INDETERMINATE" 1 "MOVING" 2 "STOPPED" 3 "STANDING" ;
VAL_ 1622 DI_infoIndex 0 "DEPRECATED_0" 1 "DEPRECATED_1" 2 "DEPRECATED_2" 3 "DEPRECATED_3" 4 "DEPRECATED_4" 5 "DEPRECATED_5" 6 "DEPRECATED_6" 7 "DEPRECATED_7" 8 "DEPRECATED_8" 9 "DEPRECATED_9" 10 "BUILD_HWID_COMPONENTID" 11 "PCBAID_ASSYID_USAGEID" 13 "APP_CRC" 14 "BOOTLOADER_SVN" 15 "BOOTLOADER_CRC" 16 "SUBCOMPONENT" 17 "APP_GITHASH" 18 "BOOTLOADER_GITHASH" 19 "VERSION_DEPRECATED" 20 "UDS_PROTOCOL_BOOTCRC" 22 "VARIANTCRC" 25 "PACKAGE_PN_1_7" 26 "PACKAGE_PN_8_14" 27 "PACKAGE_PN_15_20" 29 "PACKAGE_SN_1_7" 30 "PACKAGE_SN_8_14" 31 "SUBCOMPONENT_GITHASH" 255 "END" ;
VAL_ 1622 DI_buildType 0 "UNKNOWN_BUILD" 1 "PLATFORM_BUILD" 2 "LOCAL_BUILD" 3 "TRACEABLE_CI_BUILD" 4 "MFG_BUILD" ;
VAL_ 1622 DI_hardwareId 252 "CONFIGURABLE_HWID_PLACEHOLDER" ;
VAL_ 1622 DI_oilPumpBuildType 0 "UNKNOWN_BUILD" 1 "PLATFORM_BUILD" 2 "LOCAL_BUILD" 3 "TRACEABLE_CI_BUILD" 4 "MFG_BUILD" ;
VAL_ 1748 PMS_infoIndex 0 "DEPRECATED_0" 1 "DEPRECATED_1" 2 "DEPRECATED_2" 3 "DEPRECATED_3" 4 "DEPRECATED_4" 5 "DEPRECATED_5" 6 "DEPRECATED_6" 7 "DEPRECATED_7" 8 "DEPRECATED_8" 9 "DEPRECATED_9" 10 "BUILD_HWID_COMPONENTID" 11 "PCBAID_ASSYID_USAGEID" 13 "APP_CRC" 14 "BOOTLOADER_SVN" 15 "BOOTLOADER_CRC" 16 "SUBCOMPONENT" 17 "APP_GITHASH" 18 "BOOTLOADER_GITHASH" 19 "VERSION_DEPRECATED" 20 "UDS_PROTOCOL_BOOTCRC" 22 "VARIANTCRC" 25 "PACKAGE_PN_1_7" 26 "PACKAGE_PN_8_14" 27 "PACKAGE_PN_15_20" 29 "PACKAGE_SN_1_7" 30 "PACKAGE_SN_8_14" 31 "SUBCOMPONENT_GITHASH" 255 "END" ;
VAL_ 1748 PMS_buildType 0 "UNKNOWN_BUILD" 1 "PLATFORM_BUILD" 2 "LOCAL_BUILD" 3 "TRACEABLE_CI_BUILD" 4 "MFG_BUILD" ;
VAL_ 1748 PMS_hardwareId 252 "CONFIGURABLE_HWID_PLACEHOLDER" ;
VAL_ 1795 VCRIGHT_debugThermal10HzIndex 0 "heaterAndEvapWatts" 1 "temps" 2 "airflow" 3 "cabinModel" 4 "actuatorStatus" 5 "END" ;
VAL_ 1795 VCRIGHT_tempEvapAdjustmentLeft 255 "SNA" ;
VAL_ 1795 VCRIGHT_tempEvapAdjustmentRight 255 "SNA" ;
VAL_ 1795 VCRIGHT_cabinTempThs 255 "SNA" ;
VAL_ 1795 VCRIGHT_cabinTempThsBracket 255 "SNA" ;
VAL_ 1795 VCRIGHT_cabinTempProbe 255 "SNA" ;
VAL_ 1795 VCRIGHT_setTempAdjustmentLeft 255 "SNA" ;
VAL_ 1795 VCRIGHT_setTempAdjustmentRight 255 "SNA" ;
VAL_ 1859 VCRIGHT_mirrorRecallStatus 0 "SNA" 1 "IN_PROGRESS" 2 "COMPLETE" 3 "INTERRUPTED" ;
VAL_ 1859 VCRIGHT_seatRecallStatus 0 "SNA" 1 "IN_PROGRESS" 2 "COMPLETE" 3 "INTERRUPTED" ;
VAL_ 1859 VCRIGHT_systemRecallStatus 0 "SNA" 1 "IN_PROGRESS" 2 "COMPLETE" 3 "INTERRUPTED" ;
VAL_ 1860 VCLEFT_columnRecallStatus 0 "SNA" 1 "IN_PROGRESS" 2 "COMPLETE" 3 "INTERRUPTED" ;
VAL_ 1860 VCLEFT_mirrorRecallStatus 0 "SNA" 1 "IN_PROGRESS" 2 "COMPLETE" 3 "INTERRUPTED" ;
VAL_ 1860 VCLEFT_seatRecallStatus 0 "SNA" 1 "IN_PROGRESS" 2 "COMPLETE" 3 "INTERRUPTED" ;
VAL_ 1860 VCLEFT_systemRecallStatus 0 "SNA" 1 "IN_PROGRESS" 2 "COMPLETE" 3 "INTERRUPTED" ;
VAL_ 1879 DIF_fluxState 5 "DI_FLUXSTATE_ENABLED" 9 "DI_FLUXSTATE_FAULT" 4 "DI_FLUXSTATE_FLUX_DOWN" 3 "DI_FLUXSTATE_FLUX_UP" 6 "DI_FLUXSTATE_ICONTROL" 2 "DI_FLUXSTATE_STANDBY" 0 "DI_FLUXSTATE_START" 10 "DI_FLUXSTATE_STATIONARY_WASTE" 1 "DI_FLUXSTATE_TEST" 7 "DI_FLUXSTATE_VCONTROL" ;
VAL_ 1879 DIF_gateDriveState 3 "PSTG_GD_STATE_CONFIGURED" 2 "PSTG_GD_STATE_CONFIGURING" 0 "PSTG_GD_STATE_INIT" 4 "PSTG_GD_STATE_NOT_CONFIGURED" 1 "PSTG_GD_STATE_SELFTEST" ;
VAL_ 1879 DIF_gateDriveSupplyState 0 "PSTG_GD_SUPPLY_DOWN" 3 "PSTG_GD_SUPPLY_FALLING" 1 "PSTG_GD_SUPPLY_RISING" 2 "PSTG_GD_SUPPLY_UP" ;
VAL_ 1879 DIF_magnetTempEst 0 "SNA" ;
VAL_ 1879 DIF_motorType 8 "DI_MOTOR_F1A" 10 "DI_MOTOR_F1AC" 11 "DI_MOTOR_F2AB" 12 "DI_MOTOR_F2AC" 13 "DI_MOTOR_F2AD" 14 "DI_MOTOR_F2AE" 26 "DI_MOTOR_F2AE_AL" 15 "DI_MOTOR_F2APMSRM" 17 "DI_MOTOR_IM100A" 19 "DI_MOTOR_IM100B" 22 "DI_MOTOR_IM130C" 24 "DI_MOTOR_IM130D" 25 "DI_MOTOR_IM130D_AL" 27 "DI_MOTOR_IM130D_AL_POSCO" 20 "DI_MOTOR_IM216A" 3 "DI_MOTOR_M7M3" 4 "DI_MOTOR_M7M4" 5 "DI_MOTOR_M7M5" 7 "DI_MOTOR_M7M6" 6 "DI_MOTOR_M8A" 16 "DI_MOTOR_PM216A" 18 "DI_MOTOR_PM216B" 21 "DI_MOTOR_PM216C" 30 "DI_MOTOR_PM216CSR" 31 "DI_MOTOR_PM216CSR_N42" 23 "DI_MOTOR_PM216D" 32 "DI_MOTOR_PM228B" 28 "DI_MOTOR_PM275B" 29 "DI_MOTOR_PM350B" 1 "DI_MOTOR_ROADSTER_BASE" 2 "DI_MOTOR_ROADSTER_SPORT" 0 "DI_MOTOR_SNA" 9 "DI_MOTOR_SSR1A" ;
VAL_ 1879 DIF_oilPumpPhaseVoltage 255 "SNA" ;
VAL_ 1879 DIF_oilPumpPressureEstimateMax 255 "SNA" ;
VAL_ 1879 DIF_oilPumpPressureExpectedMin 255 "SNA" ;
VAL_ 1879 DIF_powerStageSafeState 2 "PSTG_SAFESTATE_3PS_HIGH" 3 "PSTG_SAFESTATE_3PS_LOW" 1 "PSTG_SAFESTATE_ALL_OFF" 0 "PSTG_SAFESTATE_NONE" ;
VAL_ 1879 DIF_pwmState 1 "PWMSTATE_DPWM2" 2 "PWMSTATE_OPWM1" 3 "PWMSTATE_OPWM2" 0 "PWMSTATE_SVPWM" ;
VAL_ 1879 DIF_rotorOffsetLearningState 9 "ROL_NUM_STATES" 2 "ROL_STATE_ACCELERATE" 5 "ROL_STATE_CORRECT" 8 "ROL_STATE_DONE" 0 "ROL_STATE_INIT" 4 "ROL_STATE_MEASURE" 3 "ROL_STATE_SHIFT" 6 "ROL_STATE_VERIFY" 1 "ROL_STATE_WAIT" 7 "ROL_STATE_WRITE" ;
VAL_ 1879 DIF_ssmState 5 "SSM_STATE_ABORT" 4 "SSM_STATE_ENABLE" 8 "SSM_STATE_FAULT" 2 "SSM_STATE_IDLE" 7 "SSM_STATE_RETRY" 3 "SSM_STATE_STANDBY" 0 "SSM_STATE_START" 1 "SSM_STATE_UNAVAILABLE" 6 "SSM_STATE_WAIT_FOR_RETRY" ;
VAL_ 1879 DIF_tcMaxRequest 255 "SNA" ;
VAL_ 1879 DIF_tcMinRequest 255 "SNA" ;
VAL_ 1879 DIF_usmState 3 "USM_STATE_ABORT" 4 "USM_STATE_ENABLE" 5 "USM_STATE_FAULT" 2 "USM_STATE_RETRY" 1 "USM_STATE_STANDBY" 0 "USM_STATE_START" 6 "USM_STATE_UNAVAILABLE" 7 "USM_STATE_WAIT_FOR_RETRY" ;
VAL_ 1880 DI_dynoSelector 0 "Mux0" 1 "Mux1" 2 "Mux2" 32 "Mux32" 33 "Mux33" 64 "Mux64" ;
VAL_ 1880 DI_state 0 "UNAVAILABLE" 1 "STANDBY" 2 "FAULT" 3 "ABORT" 4 "ENABLE" ;
VAL_ 1885 CP_sensorDataSelect 0 "DOOR_COUNTS" 1 "PIN_TEMP" 2 "DOOR" 3 "LATCH" 4 "INDUCTIVE_DOOR" 5 "FAULT_LINE" 6 "UHF" 7 "RAILS" 8 "PROX" 9 "PILOT" ;
VAL_ 1885 CP_inlet1HarnessIdState 1 "INVALID" 0 "SNA" 2 "VALID" ;
VAL_ 1885 CP_inlet2HarnessIdState 1 "INVALID" 0 "SNA" 2 "VALID" ;
VAL_ 1898 HVP_ecuLogUploadRequest 0 "NONE" 1 "1" 2 "2" 3 "3" ;
VAL_ 1898 HVP_vehicleDebugMultiplexer 0 "Mux0" 1 "Mux1" 2 "Mux2" ;
VAL_ 1962 HVP_debugMessageMultiplexer 0 "Mux0" 1 "Mux1" 2 "Mux2" 3 "Mux3" 4 "Mux4" 5 "Mux5" 6 "Mux6" ;
VAL_ 1962 HVP_shuntAsicTempDbg 32768 "SNA" ;
VAL_ 1962 HVP_shuntAsicTempStatus 1 "INVALID" 0 "NOT_AVAILABLE" 3 "STALE" 2 "VALID" ;
VAL_ 1962 HVP_shuntAuxCurrentStatus 1 "INVALID" 0 "NOT_AVAILABLE" 3 "STALE" 2 "VALID" ;
VAL_ 1962 HVP_shuntBarTempDbg 32768 "SNA" ;
VAL_ 1962 HVP_shuntBarTempStatus 1 "INVALID" 0 "NOT_AVAILABLE" 3 "STALE" 2 "VALID" ;
VAL_ 1992 EPBL_infoIndex 0 "DEPRECATED_0" 1 "DEPRECATED_1" 2 "DEPRECATED_2" 3 "DEPRECATED_3" 4 "DEPRECATED_4" 5 "DEPRECATED_5" 6 "DEPRECATED_6" 7 "DEPRECATED_7" 8 "DEPRECATED_8" 9 "DEPRECATED_9" 10 "BUILD_HWID_COMPONENTID" 11 "PCBAID_ASSYID_USAGEID" 13 "APP_CRC" 14 "BOOTLOADER_SVN" 15 "BOOTLOADER_CRC" 16 "SUBCOMPONENT1" 17 "APP_GITHASH" 18 "BOOTLOADER_GITHASH" 19 "VERSION_DEPRECATED" 20 "UDS_PROTOCOL_BOOTCRC" 23 "SUBCOMPONENT2" 24 "SUBCOMPONENT3" 31 "SUBCOMPONENT4" 255 "END" ;
VAL_ 1992 EPBL_infoBuildType 0 "UNKNOWN_BUILD" 1 "PLATFORM_BUILD" 2 "LOCAL_BUILD" 3 "TRACEABLE_CI_BUILD" 4 "MFG_BUILD" ;
VAL_ 1992 EPBL_infoAssemblyId 1 "ASSEMBLY1" 255 "ASSEMBLY_SNA" ;
VAL_ 2005 DI_motorType 0 "SNA" 1 "ROADSTER_BASE" 2 "ROADSTER_SPORT" 3 "M7M3" 4 "M7M4" 5 "M7M5" 6 "M8A" 7 "M7M6" 8 "F1A" 9 "SSR1A" 10 "F1AC" 11 "F2AB" 12 "F2AC" 13 "F2AD" 14 "F2AE" 15 "F2APMSRM" 16 "PM216A" 17 "IM100A" 18 "PM216B" 19 "IM100B" 20 "IM216A" 21 "PM216C" 22 "IM130C" 23 "PM216D" 24 "IM130D" 25 "IM130D_AL" ;
VAL_ 2005 DI_ssmState 0 "START" 1 "UNAVAILABLE" 2 "IDLE" 3 "STANDBY" 4 "ENABLE" 5 "ABORT" 6 "WAIT_FOR_RETRY" 7 "RETRY" 8 "FAULT" ;
VAL_ 2005 DI_usmState 0 "START" 1 "STANDBY" 2 "RETRY" 3 "ABORT" 4 "ENABLE" 5 "FAULT" 6 "UNAVAILABLE" 7 "WAIT_FOR_RETRY" ;
VAL_ 2005 DI_tcMaxRequest 255 "SNA" ;
VAL_ 2005 DI_tcMinRequest 255 "SNA" ;
VAL_ 2005 DI_fluxState 0 "START" 1 "TEST" 2 "STANDBY" 3 "FLUX_UP" 4 "FLUX_DOWN" 5 "ENABLED" 6 "ICONTROL" 7 "VCONTROL" 9 "FAULT" ;
VAL_ 2005 DI_aebFaultReason 0 "NONE" 1 "EPB_MIA" 2 "PM_MIA" 3 "EBR_FAULT" 4 "SPEED_DELTA" 5 "DAS_CONTROL_MIA" 6 "DAS_SNA" 7 "VEL_EST_ABNORMAL" 8 "PM_REQUEST" 9 "ACCEL_OUT_OF_BOUNDS" 10 "EPB_NOT_PARKED" 11 "ESP_FAULT" 12 "ESP_MIA" 13 "MIN_TIME_BTWN_EVENTS" 14 "ACCEL_REQ_INVALID" 15 "DAS_REQ_DI_UNAVAIL" ;
VAL_ 2005 DI_aebUnavailableReason 0 "NONE" 1 "CLOSURE" 2 "GEAR" 3 "SKID" 4 "NEGATIVE_SPEED" 5 "DI_STATE" 6 "EBR_UNAVAILABLE" 7 "EPB" 8 "HYSTERESIS" ;
VAL_ 2005 DI_oilPumpPhaseCurrent 255 "SNA" ;
VAL_ 2005 DI_oilPumpPhaseVoltage 255 "SNA" ;
VAL_ 2005 DI_oilPumpPhaseAdvance 255 "SNA" ;
VAL_ 2005 DI_oilPumpPressureEstimate 255 "SNA" ;
VAL_ 2005 DI_magnetTempEst 0 "SNA" ;
VAL_ 2005 DI_magnetTempEst_SFO 0 "SNA" ;
VAL_ 2005 DI_gateDriveSupplyState 0 "DOWN" 1 "RISING" 2 "UP" 3 "FALLING" ;
VAL_ 2005 DI_gateDriveState 0 "INIT" 1 "SELFTEST" 2 "CONFIGURING" 3 "CONFIGURED" 4 "NOT_CONFIGURED" ;
VAL_ 2005 DI_powerStageSafeState 0 "NONE" 1 "ALL_OFF" 2 "3PS_HIGH" 3 "3PS_LOW" ;
VAL_ 2005 DI_brkStState 0 "UNAVAILABLE" 1 "IDLE" 2 "RUNNING_UNPRESSED" 3 "RUNNING_PRESSING" 4 "RUNNING_PRESSED" 5 "INTERRUPTED" 6 "FINISHED" ;
VAL_ 2005 DI_immobilizerCondition 0 "VIRGIN_SNA" 1 "LEARNED" ;
VAL_ 2005 DI_velocityEstimatorState 0 "NOT_INITIALIZED" 1 "WHEELS_NORMAL" 2 "BACKUP_WHEELS_A" 3 "BACKUP_WHEELS_B" 4 "BACKUP_MOTOR" ;
VAL_ 2024 EPBR_infoIndex 0 "DEPRECATED_0" 1 "DEPRECATED_1" 2 "DEPRECATED_2" 3 "DEPRECATED_3" 4 "DEPRECATED_4" 5 "DEPRECATED_5" 6 "DEPRECATED_6" 7 "DEPRECATED_7" 8 "DEPRECATED_8" 9 "DEPRECATED_9" 10 "BUILD_HWID_COMPONENTID" 11 "PCBAID_ASSYID_USAGEID" 13 "APP_CRC" 14 "BOOTLOADER_SVN" 15 "BOOTLOADER_CRC" 16 "SUBCOMPONENT1" 17 "APP_GITHASH" 18 "BOOTLOADER_GITHASH" 19 "VERSION_DEPRECATED" 20 "UDS_PROTOCOL_BOOTCRC" 23 "SUBCOMPONENT2" 24 "SUBCOMPONENT3" 31 "SUBCOMPONENT4" 255 "END" ;
VAL_ 2024 EPBR_infoBuildType 0 "UNKNOWN_BUILD" 1 "PLATFORM_BUILD" 2 "LOCAL_BUILD" 3 "TRACEABLE_CI_BUILD" 4 "MFG_BUILD" ;
VAL_ 2024 EPBR_infoAssemblyId 1 "ASSEMBLY1" 255 "ASSEMBLY_SNA" ;
VAL_ 2033 GTW_hrlIndex 1 "Mux1" 2 "Mux2" ;
VAL_ 2033 GTW_hrlState 0 "DISABLED" 1 "ENABLED" ;
VAL_ 2033 GTW_hrlTriggerType 0 "UDPAPI" 1 "EVENT" 15 "NONE" ;
VAL_ 2033 GTW_hrlTriggerBus 0 "VEH" 1 "PARTY" 2 "CH" 3 "VEH" 4 "VIRT" ;
VAL_ 2047 GTW_activeHighBeam 1 "ACTIVE" 0 "NOT_ACTIVE" ;
VAL_ 2047 GTW_activeHighBeam 1 "ACTIVE" 0 "NOT_ACTIVE" ;
VAL_ 2047 GTW_airSuspension 0 "NONE" 2 "TESLA_ADAPTIVE" 1 "TESLA_STANDARD" ;
VAL_ 2047 GTW_airbagCutoffSwitch 0 "CUTOFF_SWITCH_DISABLED" 1 "CUTOFF_SWITCH_ENABLED" ;
VAL_ 2047 GTW_audioType 0 "BASE" 2 "BASE_WITH_PREMIUM200" 1 "PREMIUM" ;
VAL_ 2047 GTW_autopilot 4 "BASIC" 2 "ENHANCED" 1 "HIGHWAY" 0 "NONE" 3 "SELF_DRIVING" ;
VAL_ 2047 GTW_autopilotCameraType 0 "RCCB_CAMERAS" ;
VAL_ 2047 GTW_auxParkLamps 2 "EU" 0 "NA_BASE" 1 "NA_PREMIUM" 3 "NONE" ;
VAL_ 2047 GTW_bPillarNFCParam 0 "MODEL_3" 1 "MODEL_Y" ;
VAL_ 2047 GTW_brakeHWType 1 "BREMBO_LARGE_P42_BREMBO_44MOC" 3 "BREMBO_LARGE_P42_BREMBO_LARGE_44MOC" 2 "BREMBO_LARGE_P42_MANDO_43MOC" 0 "BREMBO_P42_MANDO_43MOC" ;
VAL_ 2047 GTW_brakeLineSwitchType 0 "DI_VC_SHARED" 1 "VC_ONLY" ;
VAL_ 2047 GTW_cabinPTCHeaterType 0 "BORGWARNER" 1 "NONE" ;
VAL_ 2047 GTW_chassisType 2 "MODEL_3_CHASSIS" 0 "MODEL_S_CHASSIS" 1 "MODEL_X_CHASSIS" 3 "MODEL_Y_CHASSIS" ;
VAL_ 2047 GTW_compressorType 2 "DENSO_41CC_11K" 1 "DENSO_41CC_8K" 0 "HANON_33CC" ;
VAL_ 2047 GTW_connectivityPackage 0 "BASE" 1 "PREMIUM" ;
VAL_ 2047 GTW_coolantPumpType 0 "DUAL" 1 "SINGLE_PUMP_BATT" ;
VAL_ 2047 GTW_dasHw 3 "PARKER_PASCAL_2_5" 4 "TESLA_AP3" ;
VAL_ 2047 GTW_deliveryStatus 1 "DELIVERED" 0 "NOT_DELIVERED" ;
VAL_ 2047 GTW_drivetrainType 1 "AWD" 0 "RWD" ;
VAL_ 2047 GTW_eBuckConfig 1 "DEV_BUCK" 0 "NONE" ;
VAL_ 2047 GTW_eCallEnabled 0 "DISABLED" 1 "ENABLED_OHC_SOS" 2 "ENABLED_UI_SOS" ;
VAL_ 2047 GTW_efficiencyPackage 0 "DEFAULT" 2 "M3_LR_2020" 3 "M3_LR_PERFORMANCE_2020" 1 "M3_SR_PLUS_2020" ;
VAL_ 2047 GTW_epasType 0 "MANDO_VGR69_GEN3" ;
VAL_ 2047 GTW_espValveType 0 "UNKNOWN" 1 "VALVE_TYPE_1" 2 "VALVE_TYPE_2" ;
VAL_ 2047 GTW_exteriorColor 5 "DEEP_BLUE" 3 "MIDNIGHT_SILVER" 6 "PEARL_WHITE" 0 "RED_MULTICOAT" 2 "SILVER_METALLIC" 1 "SOLID_BLACK" ;
VAL_ 2047 GTW_frontFogLamps 1 "INSTALLED" 0 "NOT_INSTALLED" ;
VAL_ 2047 GTW_frontSeatHeaters 1 "KONGSBERG_LOW_POWER" 0 "NONE" ;
VAL_ 2047 GTW_frontSeatReclinerHardware 3 "LEFT_RIGHT_SEAT_REDUCED_RANGE" 2 "LEFT_SEAT_REDUCED_RANGE" 1 "RIGHT_SEAT_REDUCED_RANGE" 0 "STANDARD_RANGE" ;
VAL_ 2047 GTW_frontSeatType 0 "BASE_TESLA" 3 "PREMIUM_L_TESLA_R_YANFENG" 2 "PREMIUM_L_YANFENG_R_TESLA" 1 "PREMIUM_TESLA" 4 "PREMIUM_YANFENG" ;
VAL_ 2047 GTW_headlamps 0 "BASE" 1 "PREMIUM" ;
VAL_ 2047 GTW_headlightLevelerType 1 "GEN1" 0 "NONE" ;
VAL_ 2047 GTW_homelinkType 1 "HOMELINK_V_OPT_2" 0 "NONE" ;
VAL_ 2047 GTW_hvacPanelVaneType 1 "CONVERGENT_V1" 0 "PARALLEL_V1" ;
VAL_ 2047 GTW_immersiveAudio 1 "BASE" 0 "DISABLED" 2 "PREMIUM" ;
VAL_ 2047 GTW_interiorLighting 0 "BASE" 1 "PREMIUM" 2 "PREMIUM_NO_POCKET_LIGHT" ;
VAL_ 2047 GTW_intrusionSensorType 0 "NOT_INSTALLED" 1 "VODAFONE" ;
VAL_ 2047 GTW_lumbarECUType 1 "ALFMEIER" 0 "NONE" ;
VAL_ 2047 GTW_mapRegion 4 "AU" 3 "CN" 1 "EU" 9 "HK" 5 "JP" 7 "KR" 8 "ME" 10 "MO" 2 "NONE" 6 "TW" 0 "US" ;
VAL_ 2047 GTW_memoryMirrors 0 "NOT_INSTALLED" 1 "SMR" ;
VAL_ 2047 GTW_numberHVILNodes 0 "HVIL_NODES_0" 1 "HVIL_NODES_1" 2 "HVIL_NODES_2" 3 "HVIL_NODES_3" 4 "HVIL_NODES_4" 5 "HVIL_NODES_5" ;
VAL_ 2047 GTW_packEnergy 3 "PACK_100_KWH" 0 "PACK_50_KWH" 2 "PACK_62_KWH" 1 "PACK_74_KWH" 4 "PACK_75_KWH" ;
VAL_ 2047 GTW_passengerAirbagType 2 "EUROW" 0 "FULL_SUPPRESSION" 1 "SAFETY_VENT" ;
VAL_ 2047 GTW_passengerOccupancySensorType 0 "OCS" 1 "RESISTIVE_PAD" ;
VAL_ 2047 GTW_pedestrianWarningSound 0 "NONE" 1 "SPEAKER" ;
VAL_ 2047 GTW_performancePackage 0 "BASE" 3 "BASE_PLUS" 4 "BASE_PLUS_AWD" 2 "LUDICROUS" 1 "PERFORMANCE" ;
VAL_ 2047 GTW_plcSupportType 2 "NATIVE_CHARGE_PORT" 0 "NONE" 1 "ONBOARD_ADAPTER" ;
VAL_ 2047 GTW_powerSteeringColumn 0 "NOT_INSTALLED" 1 "TK" ;
VAL_ 2047 GTW_radarHeaterType 1 "BECKER_THIN_3M" 0 "NONE" ;
VAL_ 2047 GTW_rearFogLamps 1 "INSTALLED" 0 "NOT_INSTALLED" ;
VAL_ 2047 GTW_rearGlassType 0 "NX" 1 "TSA5_NOPET" ;
VAL_ 2047 GTW_rearLightType 1 "EU_CN" 2 "GLOBAL" 0 "NA" ;
VAL_ 2047 GTW_rearSeatHeaters 1 "KONGSBERG_LOW_POWER" 0 "NONE" ;
VAL_ 2047 GTW_refrigerantType 0 "Default" 2 "R1234YF" 1 "R134A" ;
VAL_ 2047 GTW_restraintsHardwareType 22 "EUROW_ECALL_M3" 33 "EUROW_ECALL_MY" 23 "EUROW_NO_ECALL_M3" 34 "EUROW_NO_ECALL_MY" 21 "NA_M3" 32 "NA_MY" 31 "NA_MY_OLD" ;
VAL_ 2047 GTW_rightHandDrive 0 "LEFT" 1 "RIGHT" ;
VAL_ 2047 GTW_roofGlassType 0 "TSA3_PET" 1 "TSA5_NOPET" ;
VAL_ 2047 GTW_roofType 1 "FIXED_GLASS" 0 "METAL" 2 "PANORAMIC" ;
VAL_ 2047 GTW_softRange 1 "RANGE_220_MILES" 2 "RANGE_93_MILES" 0 "STANDARD" ;
VAL_ 2047 GTW_spoilerType 0 "NOT_INSTALLED" 1 "PASSIVE" ;
VAL_ 2047 GTW_steeringColumnMotorType 0 "BOSCH" 1 "JE" ;
VAL_ 2047 GTW_steeringColumnUJointType 0 "B_SAMPLE_PHASING" 1 "C_SAMPLE_PHASING" ;
VAL_ 2047 GTW_superchargingAccess 1 "ALLOWED" 0 "NOT_ALLOWED" 2 "PAY_AS_YOU_GO" ;
VAL_ 2047 GTW_tireType 4 "CONTI_ALL_SEASON_19" 17 "GOODYEAR_ALL_SEASON_20" 3 "HANKOOK_SUMMER_19" 1 "MICHELIN_ALL_SEASON_18" 19 "MICHELIN_ALL_SEASON_21" 2 "MICHELIN_SUMMER_18" 5 "MICHELIN_SUMMER_20" 18 "PIRELLI_SUMMER_21" 0 "UNKNOWN" ;
VAL_ 2047 GTW_towPackage 0 "NONE" 1 "TESLA_REV1" ;
VAL_ 2047 GTW_tpmsType 0 "CONTI_2" 1 "TESLA_BLE" ;
VAL_ 2047 GTW_twelveVBatteryType 0 "ATLASBX_B24_FLOODED" 1 "CLARIOS_B24_FLOODED" ;
VAL_ 2047 GTW_vdcType 0 "BOSCH_VDC" 1 "TESLA_VDC" ;
VAL_ 2047 GTW_wheelType 4 "GEMINI_19_SQUARE" 5 "GEMINI_19_STAGGERED" 0 "PINWHEEL_18" 18 "PINWHEEL_18_CAP_KIT" 1 "STILETTO_19" 2 "STILETTO_20" 14 "STILETTO_20_DARK_SQUARE" 3 "STILETTO_20_DARK_STAGGERED" 19 "ZEROG_20_GUNPOWDER" 17 "APOLLO_19_SILVER" 20 "APOLLO_19_SILVER_CAP_KIT" 15 "INDUCTION_20_BLACK" 16 "UBERTURBINE_21_BLACK" ;
VAL_ 2047 GTW_windshieldType 1 "EASTMAN_ACOUSTIC" 0 "SEKISUI_ACOUSTIC" ;
VAL_ 2047 GTW_xcpESP 0 "FALSE" 1 "TRUE" ;
VAL_ 2047 GTW_xcpIbst 0 "FALSE" 1 "TRUE" ;
